VERSION ""

NS_ :

BS_:

BU_: Battery_Management_Cntrl_1 PowertrainControlModule AtmosphericSensor SafetyRestraintSystem2 Aftertreatment_2_GasOutlet Aftertreatment_2_GasIntake DieselParticulateFilterControl Turbocharger SafetyRestraintSystem1 CabDisplay2 Aftertreatment_1_GasOutlet Aftertreatment_1_GasIntake OnBoardDataLogger OffBoardDiagnosticTool2 OffBoardDiagnosticTool1 FileServer ParkingBrakeController SeatController2 FanDriveController SteeringColumnUnit CommunicationUnitRadio CommunicationUnitSatellite CommunicationUnitCellular PropulsionBatteryCharger ChassisController2 ChassisController1 EngineValveControl AuxiliaryHeater2 AuxiliaryHeater1 ClutchUnit RampControl InformationSystem1 SuspensionSystemController2 OilSensor VehicleDynamicStability ExhaustEmissionController TransmissionDisplay2 TransmissionDisplay1 ClimateControl2 WaterPumpController RearAxleSteeringController LightingOperatorControl SeatController1 IgnitionController2 IgnitionController1 TirePressureController CabController2 CabController1 PneumaticSystemController SuspensionSystemController1 HydraulicPumpController EnduranceBrakingSystem RetarderExhaustEngine2 OnBoardDiagnosticUnit HeadwayController RetarderExhaustEngine1 CabDisplay1 ManagementComputer VirtualTerminal OffVehicleGateway PowerTakeOffFront HitchControl AuxiliaryValveControl BodyController TractorTrailerBridge1 StarterSystem ElectricalSystem VehicleSecurity VehicleNavigation AerodynamicControl ElectricalChargingSystem ClimateControl1 TripRecorder InstrumentCluster SuspensionDriveAxle2 SuspensionDriveAxle1 SuspensionSteerAxle SteeringController FuelSystem CruiseControl RetarderDriveline RetarderEngine BrakesDriveAxle2 BrakesDriveAxle1 BrakesSystemController BrakesSteerAxle AxleDrive2 AxleDrive1 AxleSteering PowerTakeOff ShiftConsoleSecondary ShiftConsolePrimary Transmission2 Transmission1 Engine2 Engine1
VAL_TABLE_ FMI 22 "Data Drifted Low" 21 "Data Drifted High" 20 "Received Network Data In Error" 0 "Above normal (most severe)" 1 "Below normal (most severe)" 2 "Data erratic" 3 "Voltage above normal" 4 "Voltage below normal" 5 "Current below normal" 6 "Current above normal" 7 "Mechanical system not responding" 8 "Abnormal frequency" 9 "Abnormal update rate" 10 "Abnormal rate of change" 11 "Root cause not known" 12 "Bad intelligent device" 13 "Out of calibration" 14 "Special intstructions" 15 "Above normal (least severe)" 16 "Above normal (moderately severe)" 17 "Below normal (least severe)" 18 "Below normal (moderately severe)" 19 "Received network data in error" 31 "Condition Exists" ;
VAL_TABLE_ TireLocation_MUX 51 "TirePress_33_MUX_51" 50 "TirePress_32_MUX_50" 49 "TirePress_31_MUX_49" 48 "TirePress_30_MUX_48" 35 "TirePress_23_MUX_35" 34 "TirePress_22_MUX_34" 33 "TirePress_21_MUX_33" 32 "TirePress_20_MUX_32" 19 "TirePress_13_MUX_19" 18 "TirePress_12_MUX_18" 17 "TirePress_11_MUX_17" 16 "TirePress_10_MUX_16" 1 "TirePress_01_MUX_1" 0 "TirePress_00_MUX_0" ;

BO_ 3221225472 VECTOR__INDEPENDENT_SIG_MSG: 0 Vector__XXX
 SG_ HVES1HVBPsvITR_8432 : 0|16@1+ (0.1,0) [0|6425.5] "Ohm/V" Vector__XXX
 SG_ HVES1HVBAcvITR_8431 : 0|16@1+ (0.1,0) [0|6425.5] "Ohm/V" Vector__XXX
 SG_ HVES1LoCellStOChaCellNo_8248 : 0|8@1+ (1,0) [0|250] "count" Vector__XXX
 SG_ HVES1LoCellStOChaModuNo_8247 : 0|8@1+ (1,0) [0|250] "count" Vector__XXX
 SG_ HVES1HiCellStOChaCellNo_8246 : 0|8@1+ (1,0) [0|250] "count" Vector__XXX
 SG_ HVES1HiCellStOChaModuNo_8245 : 0|8@1+ (1,0) [0|250] "count" Vector__XXX
 SG_ TranIdleGovrnrFuelingInhbit_7829 : 0|8@1- (1,0) [0|0] "" Vector__XXX
 SG_ NumberOfMembersInWorkingSet : 0|8@1+ (1,0) [0|0] "" Vector__XXX
 SG_ SourceAddress : 0|8@1+ (1,0) [0|0] "" Vector__XXX
 SG_ NncntnuslyMonitoredSystemsStatus : 0|16@1+ (1,0) [0|0] "" Vector__XXX
 SG_ NncntnslyMonitoredSystemsSupport : 0|16@1+ (1,0) [0|0] "" Vector__XXX
 SG_ CntnslyMntrdSystmsSupport_Status : 0|8@1+ (1,0) [0|0] "" Vector__XXX
 SG_ AETCTorqueValue : 0|16@1+ (1,0) [0|64255] "Nm" Vector__XXX
 SG_ TrailerWeight : 0|16@1+ (2,0) [0|128510] "kg" Vector__XXX
 SG_ ReferenceTirePressSetting : 0|8@1+ (8,0) [0|2000] "kPa" Vector__XXX
 SG_ ReferenceTirePress : 0|8@1+ (8,0) [0|2000] "kPa" Vector__XXX
 SG_ TirePressThresholdDetection : 0|3@1+ (1,0) [0|7] "" Vector__XXX
 SG_ TireAirLeakageRate : 0|16@1+ (0.1,0) [0|6425.5] "Pa/s" Vector__XXX
 SG_ CTIWheelEndElectricalFault : 0|2@1+ (1,0) [0|3] "" Vector__XXX
 SG_ CTITireStatus : 0|2@1+ (1,0) [0|3] "" Vector__XXX
 SG_ CTIWheelSensorStatus : 0|2@1+ (1,0) [0|3] "" Vector__XXX
 SG_ TireTemp : 0|16@1+ (0.03125,-273) [-273|1734.96875] "deg C" Vector__XXX
 SG_ TirePress : 0|8@1+ (4,0) [0|1000] "kPa" Vector__XXX
 SG_ EngTurningGearEngaged : 0|2@1+ (1,0) [0|3] "" Vector__XXX
 SG_ AETCSpeedValue : 0|16@1+ (0.125,0) [0|8031.875] "rpm" Vector__XXX

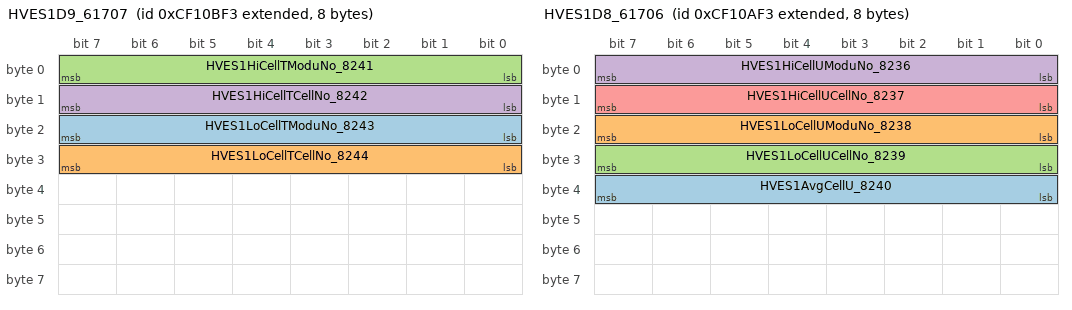
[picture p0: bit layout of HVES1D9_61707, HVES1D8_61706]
BO_ 2364607475 HVES1D9_61707: 8 Battery_Management_Cntrl_1
 SG_ HVES1LoCellTModuNo_8243 : 16|8@1+ (1,0) [0|250] "count" Vector__XXX
 SG_ HVES1LoCellTCellNo_8244 : 24|8@1+ (1,0) [0|250] "count" Vector__XXX
 SG_ HVES1HiCellTModuNo_8241 : 0|8@1+ (1,0) [0|250] "count" Vector__XXX
 SG_ HVES1HiCellTCellNo_8242 : 8|8@1+ (1,0) [0|250] "count" Vector__XXX

BO_ 2364607219 HVES1D8_61706: 8 Battery_Management_Cntrl_1
 SG_ HVES1AvgCellU_8240 : 32|8@1+ (1,0) [0|250] "count" Vector__XXX
 SG_ HVES1LoCellUModuNo_8238 : 16|8@1+ (1,0) [0|250] "count" Vector__XXX
 SG_ HVES1LoCellUCellNo_8239 : 24|8@1+ (1,0) [0|250] "count" Vector__XXX
 SG_ HVES1HiCellUModuNo_8236 : 0|8@1+ (1,0) [0|250] "count" Vector__XXX
 SG_ HVES1HiCellUCellNo_8237 : 8|8@1+ (1,0) [0|250] "count" Vector__XXX

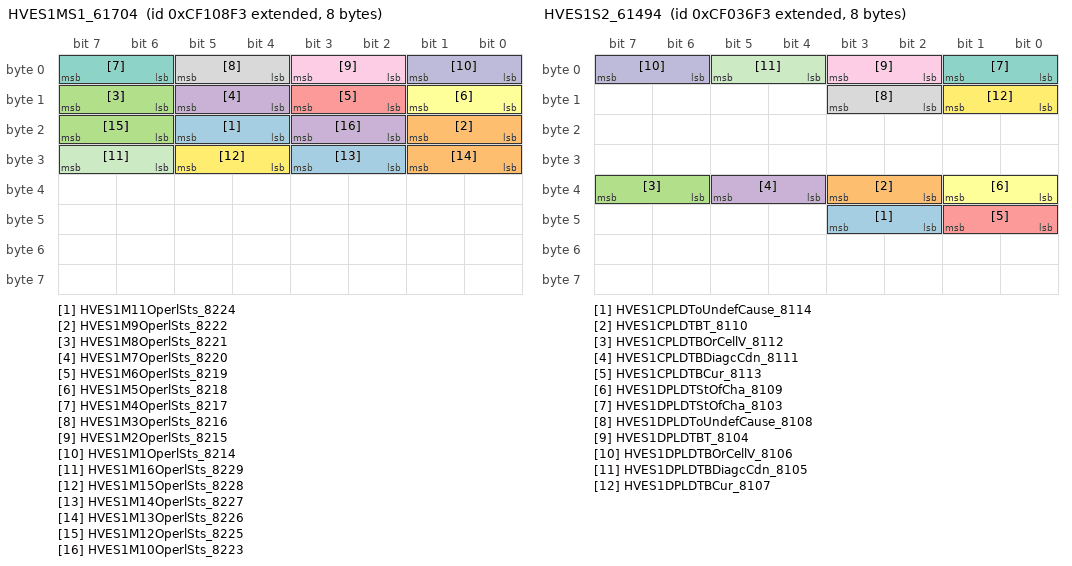
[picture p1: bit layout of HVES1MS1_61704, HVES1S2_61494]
BO_ 2364606707 HVES1MS1_61704: 8 Battery_Management_Cntrl_1
 SG_ HVES1M11OperlSts_8224 : 20|2@1+ (1,0) [0|3] "bit" Vector__XXX
 SG_ HVES1M9OperlSts_8222 : 16|2@1+ (1,0) [0|3] "bit" Vector__XXX
 SG_ HVES1M8OperlSts_8221 : 14|2@1+ (1,0) [0|3] "bit" Vector__XXX
 SG_ HVES1M7OperlSts_8220 : 12|2@1+ (1,0) [0|3] "bit" Vector__XXX
 SG_ HVES1M6OperlSts_8219 : 10|2@1+ (1,0) [0|3] "bit" Vector__XXX
 SG_ HVES1M5OperlSts_8218 : 8|2@1+ (1,0) [0|3] "bit" Vector__XXX
 SG_ HVES1M4OperlSts_8217 : 6|2@1+ (1,0) [0|3] "bit" Vector__XXX
 SG_ HVES1M3OperlSts_8216 : 4|2@1+ (1,0) [0|3] "bit" Vector__XXX
 SG_ HVES1M2OperlSts_8215 : 2|2@1+ (1,0) [0|3] "bit" Vector__XXX
 SG_ HVES1M1OperlSts_8214 : 0|2@1+ (1,0) [0|3] "bit" Vector__XXX
 SG_ HVES1M16OperlSts_8229 : 30|2@1+ (1,0) [0|3] "bit" Vector__XXX
 SG_ HVES1M15OperlSts_8228 : 28|2@1+ (1,0) [0|3] "bit" Vector__XXX
 SG_ HVES1M14OperlSts_8227 : 26|2@1+ (1,0) [0|3] "bit" Vector__XXX
 SG_ HVES1M13OperlSts_8226 : 24|2@1+ (1,0) [0|3] "bit" Vector__XXX
 SG_ HVES1M12OperlSts_8225 : 22|2@1+ (1,0) [0|3] "bit" Vector__XXX
 SG_ HVES1M10OperlSts_8223 : 18|2@1+ (1,0) [0|3] "bit" Vector__XXX

BO_ 2364552947 HVES1S2_61494: 8 Battery_Management_Cntrl_1
 SG_ HVES1CPLDToUndefCause_8114 : 42|2@1+ (1,0) [0|3] "bit" Vector__XXX
 SG_ HVES1CPLDTBT_8110 : 34|2@1+ (1,0) [0|3] "bit" Vector__XXX
 SG_ HVES1CPLDTBOrCellV_8112 : 38|2@1+ (1,0) [0|3] "bit" Vector__XXX
 SG_ HVES1CPLDTBDiagcCdn_8111 : 36|2@1+ (1,0) [0|3] "bit" Vector__XXX
 SG_ HVES1CPLDTBCur_8113 : 40|2@1+ (1,0) [0|3] "bit" Vector__XXX
 SG_ HVES1DPLDTStOfCha_8109 : 32|2@1+ (1,0) [0|3] "bit" Vector__XXX
 SG_ HVES1DPLDTStOfCha_8103 : 0|2@1+ (1,0) [0|3] "bit" Vector__XXX
 SG_ HVES1DPLDToUndefCause_8108 : 10|2@1+ (1,0) [0|3] "bit" Vector__XXX
 SG_ HVES1DPLDTBT_8104 : 2|2@1+ (1,0) [0|3] "bit" Vector__XXX
 SG_ HVES1DPLDTBOrCellV_8106 : 6|2@1+ (1,0) [0|3] "bit" Vector__XXX
 SG_ HVES1DPLDTBDiagcCdn_8105 : 4|2@1+ (1,0) [0|3] "bit" Vector__XXX
 SG_ HVES1DPLDTBCur_8107 : 8|2@1+ (1,0) [0|3] "bit" Vector__XXX

BO_ 2633785075 HVES1HIST_64606: 8 Battery_Management_Cntrl_1
 SG_ HVES1TotEgyThput_8211 : 24|32@1- (100,0) [0|421108121500] "Watt-hour" Vector__XXX
 SG_ HVES1TotAccumCha_8212 : 56|32@1- (100,0) [0|421108121500] "Ah" Vector__XXX
 SG_ HVES1StOfHealth_8121 : 0|8@1- (0.02044,0) [0|5.11] "V" Vector__XXX
 SG_ HVES1CtorOpenUndLoa_8122 : 8|16@1+ (1,0) [0|64255] "count" Vector__XXX

BO_ 2566675955 HVES1CFG_64605: 8 Battery_Management_Cntrl_1
 SG_ HVES1RecomMinSOC_8118 : 48|16@1- (0.0015625,0) [0|100.3984375] "%" Vector__XXX
 SG_ HVES1RecomMinOpergV_8116 : 16|16@1- (0.05,0) [0|3212.75] "V" Vector__XXX
 SG_ HVES1RecomMinOpergT_8208 : 96|16@1- (0.03125,-273) [-273|1734.96875] "deg C" Vector__XXX
 SG_ HVES1RecomMaxSOC_8119 : 64|16@1- (0.0015625,0) [0|100.3984375] "%" Vector__XXX
 SG_ HVES1RecomMaxOpergV_8117 : 32|16@1- (0.05,0) [0|3212.75] "V" Vector__XXX
 SG_ HVES1RecomMaxOpergT_8120 : 80|16@1- (0.03125,-273) [-273|1734.96875] "deg C" Vector__XXX
 SG_ HVES1NomVoltage_8115 : 0|16@1- (0.05,0) [0|3212.75] "V" Vector__XXX
 SG_ HVES1CellMinVLim_8210 : 120|8@1- (0.02044,0) [0|5.11] "V" Vector__XXX
 SG_ HVES1CellMaxVLim_8209 : 112|8@1- (0.02044,0) [0|5.11] "V" Vector__XXX

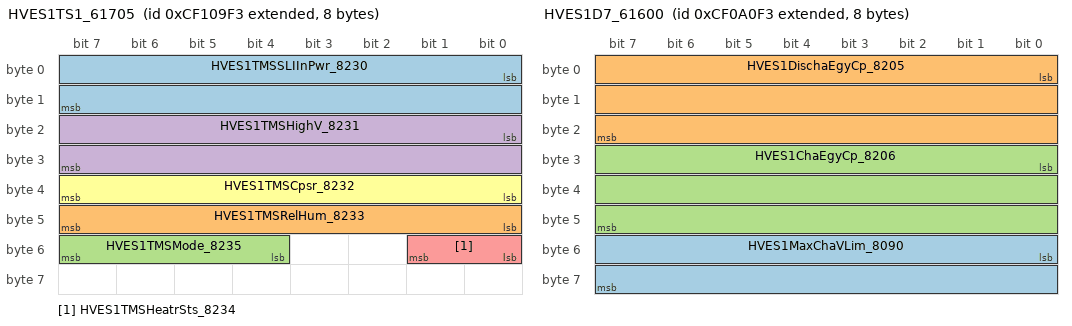
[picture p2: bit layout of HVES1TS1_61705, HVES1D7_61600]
BO_ 2364606963 HVES1TS1_61705: 8 Battery_Management_Cntrl_1
 SG_ HVES1TMSSLIInPwr_8230 : 0|16@1- (0.5,0) [0|32127.5] "W" Vector__XXX
 SG_ HVES1TMSRelHum_8233 : 40|8@1- (0.4,0) [0|100] "%" Vector__XXX
 SG_ HVES1TMSMode_8235 : 52|4@1- (1,0) [0|15] "bits" Vector__XXX
 SG_ HVES1TMSHighV_8231 : 16|16@1- (0.5,0) [0|32127.5] "W" Vector__XXX
 SG_ HVES1TMSHeatrSts_8234 : 48|2@1- (1,0) [0|3] "bits" Vector__XXX
 SG_ HVES1TMSCpsr_8232 : 32|8@1- (32,0) [0|8000] "rpm" Vector__XXX

BO_ 2364580083 HVES1D7_61600: 8 Battery_Management_Cntrl_1
 SG_ HVES1MaxChaVLim_8090 : 48|16@1- (0.05,0) [0|3212.75] "V" Vector__XXX
 SG_ HVES1DischaEgyCp_8205 : 0|24@1- (0.001,0) [0|16449.535] "kWh" Vector__XXX
 SG_ HVES1ChaEgyCp_8206 : 24|24@1- (0.001,0) [0|16449.535] "kWh" Vector__XXX

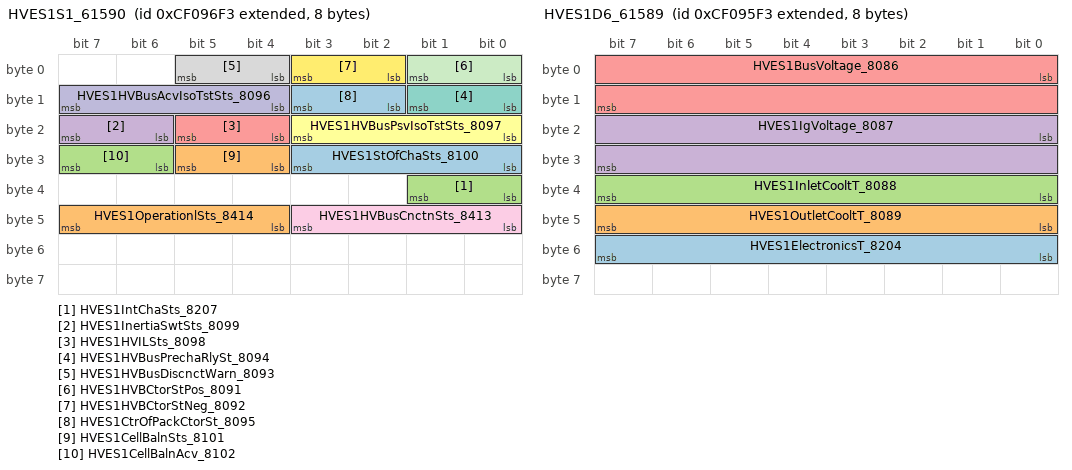
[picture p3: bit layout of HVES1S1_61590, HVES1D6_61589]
BO_ 2364577523 HVES1S1_61590: 8 Battery_Management_Cntrl_1
 SG_ HVES1StOfChaSts_8100 : 24|4@1+ (1,0) [0|15] "bits" Vector__XXX
 SG_ HVES1OperationlSts_8414 : 44|4@1+ (1,0) [0|15] "bit" Vector__XXX
 SG_ HVES1IntChaSts_8207 : 32|2@1- (1,0) [0|3] "bits" Vector__XXX
 SG_ HVES1InertiaSwtSts_8099 : 22|2@1+ (1,0) [0|3] "bits" Vector__XXX
 SG_ HVES1HVILSts_8098 : 20|2@1+ (1,0) [0|3] "bits" Vector__XXX
 SG_ HVES1HVBusPsvIsoTstSts_8097 : 16|4@1- (1,0) [0|15] "bits" Vector__XXX
 SG_ HVES1HVBusPrechaRlySt_8094 : 8|2@1+ (1,0) [0|3] "bits" Vector__XXX
 SG_ HVES1HVBusDiscnctWarn_8093 : 4|2@1+ (1,0) [0|15] "bits" Vector__XXX
 SG_ HVES1HVBusCnctnSts_8413 : 40|4@1- (1,0) [0|15] "bits" Vector__XXX
 SG_ HVES1HVBusAcvIsoTstSts_8096 : 12|4@1- (1,0) [0|15] "bits" Vector__XXX
 SG_ HVES1HVBCtorStPos_8091 : 0|2@1- (1,0) [0|3] "bit" Vector__XXX
 SG_ HVES1HVBCtorStNeg_8092 : 2|2@1- (1,0) [0|3] "bit" Vector__XXX
 SG_ HVES1CtrOfPackCtorSt_8095 : 10|2@1+ (1,0) [0|3] "bits" Vector__XXX
 SG_ HVES1CellBalnSts_8101 : 28|2@1+ (1,0) [0|3] "bit" Vector__XXX
 SG_ HVES1CellBalnAcv_8102 : 30|2@1+ (1,0) [0|3] "bit" Vector__XXX

BO_ 2364577267 HVES1D6_61589: 8 Battery_Management_Cntrl_1
 SG_ HVES1ElectronicsT_8204 : 48|8@1- (1,-40) [-40|210] "deg C" Vector__XXX
 SG_ HVES1OutletCooltT_8089 : 40|8@1- (1,-40) [-40|210] "deg C" Vector__XXX
 SG_ HVES1InletCooltT_8088 : 32|8@1- (1,-40) [-40|210] "deg C" Vector__XXX
 SG_ HVES1IgVoltage_8087 : 16|16@1- (0.01,0) [0|642.55] "V" Vector__XXX
 SG_ HVES1BusVoltage_8086 : 0|16@1- (0.05,0) [0|3212.75] "V" Vector__XXX

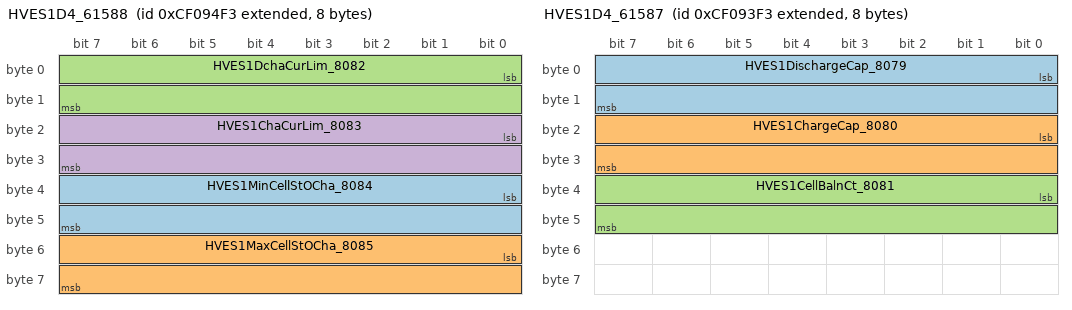
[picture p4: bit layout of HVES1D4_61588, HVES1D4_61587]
BO_ 2364577011 HVES1D4_61588: 8 Battery_Management_Cntrl_1
 SG_ HVES1MinCellStOCha_8084 : 32|16@1- (0.0015625,0) [0|100.3984375] "%" Vector__XXX
 SG_ HVES1MaxCellStOCha_8085 : 48|16@1- (0.0015625,0) [0|100.3984375] "%" Vector__XXX
 SG_ HVES1DchaCurLim_8082 : 0|16@1- (0.05,-1600) [-1600|1612.75] "A" Vector__XXX
 SG_ HVES1ChaCurLim_8083 : 16|16@1- (0.05,-1600) [-1600|1612.75] "A" Vector__XXX

BO_ 2364576755 HVES1D4_61587: 8 Battery_Management_Cntrl_1
 SG_ HVES1DischargeCap_8079 : 0|16@1- (0.01,0) [0|642.55] "Ah" Vector__XXX
 SG_ HVES1ChargeCap_8080 : 16|16@1- (0.01,0) [0|642.55] "Ah" Vector__XXX
 SG_ HVES1CellBalnCt_8081 : 32|16@1- (1,0) [0|64255] "count" Vector__XXX

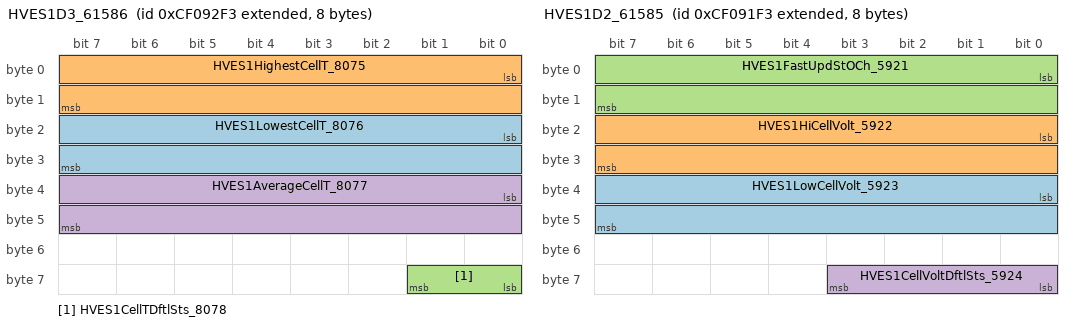
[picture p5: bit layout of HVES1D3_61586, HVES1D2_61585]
BO_ 2364576499 HVES1D3_61586: 8 Battery_Management_Cntrl_1
 SG_ HVES1LowestCellT_8076 : 16|16@1- (0.03125,-273) [-273|1734.96875] "degrees C" Vector__XXX
 SG_ HVES1HighestCellT_8075 : 0|16@1- (0.03125,-273) [-273|1734.96875] "degrees C" Vector__XXX
 SG_ HVES1CellTDftlSts_8078 : 56|2@1- (1,0) [0|3] "bits" Vector__XXX
 SG_ HVES1AverageCellT_8077 : 32|16@1- (0.03125,-273) [-273|1734.96875] "degrees C" Vector__XXX

BO_ 2364576243 HVES1D2_61585: 8 Battery_Management_Cntrl_1
 SG_ HVES1LowCellVolt_5923 : 32|16@1- (0.001,0) [0|64.255] "V" Vector__XXX
 SG_ HVES1HiCellVolt_5922 : 16|16@1- (0.001,0) [0|64.255] "V" Vector__XXX
 SG_ HVES1FastUpdStOCh_5921 : 0|16@1- (0.0015625,0) [0|100.3984375] "%" Vector__XXX
 SG_ HVES1CellVoltDftlSts_5924 : 56|4@1- (1,0) [0|15] "bot" Vector__XXX

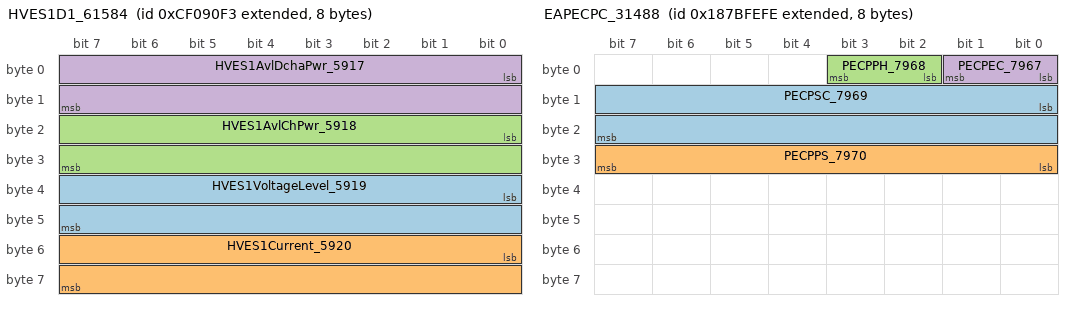
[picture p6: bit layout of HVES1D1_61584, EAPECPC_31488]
BO_ 2364575987 HVES1D1_61584: 8 Battery_Management_Cntrl_1
 SG_ HVES1VoltageLevel_5919 : 32|16@1- (0.05,0) [0|3212.75] "V" Vector__XXX
 SG_ HVES1Current_5920 : 48|16@1- (0.05,-1600) [-1600|1612.75] "A" Vector__XXX
 SG_ HVES1AvlChPwr_5918 : 16|16@1- (0.05,0) [0|3212.75] "kW" Vector__XXX
 SG_ HVES1AvlDchaPwr_5917 : 0|16@1- (0.05,0) [0|3212.75] "kW" Vector__XXX

BO_ 2558263038 EAPECPC_31488: 8 Vector__XXX
 SG_ PECPSC_7969 : 8|16@1+ (0.5,0) [0|32767.5] "rpm" Vector__XXX
 SG_ PECPPS_7970 : 24|8@1+ (0.5,0) [0|127.5] "%" Vector__XXX
 SG_ PECPPH_7968 : 2|2@1+ (1,0) [0|3] "" Vector__XXX
 SG_ PECPEC_7967 : 0|2@1+ (1,0) [0|3] "" Vector__XXX

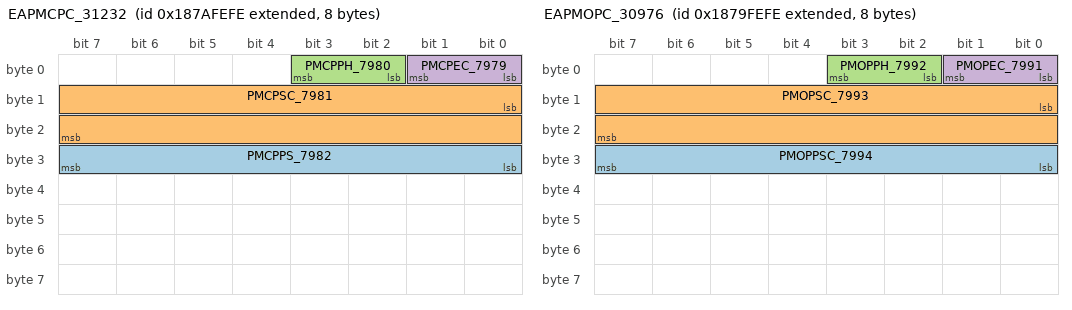
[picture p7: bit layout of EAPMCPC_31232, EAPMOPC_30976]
BO_ 2558197502 EAPMCPC_31232: 8 Vector__XXX
 SG_ PMCPPS_7982 : 24|8@1+ (0.5,0) [0|127.5] "%" Vector__XXX
 SG_ PMCPSC_7981 : 8|16@1+ (0.5,0) [0|32767.5] "rpm" Vector__XXX
 SG_ PMCPPH_7980 : 2|2@1+ (1,0) [0|3] "" Vector__XXX
 SG_ PMCPEC_7979 : 0|2@1+ (1,0) [0|3] "" Vector__XXX

BO_ 2558131966 EAPMOPC_30976: 8 Vector__XXX
 SG_ PMOPPSC_7994 : 24|8@1+ (0.5,0) [0|127.5] "%" Vector__XXX
 SG_ PMOPSC_7993 : 8|16@1+ (0.5,0) [0|32767.5] "rpm" Vector__XXX
 SG_ PMOPPH_7992 : 2|2@1+ (1,0) [0|3] "" Vector__XXX
 SG_ PMOPEC_7991 : 0|2@1+ (1,0) [0|3] "" Vector__XXX

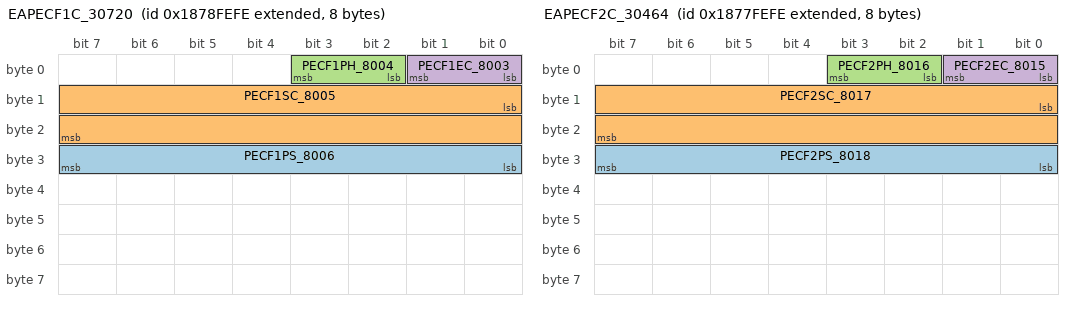
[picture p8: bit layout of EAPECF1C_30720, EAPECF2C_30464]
BO_ 2558066430 EAPECF1C_30720: 8 Vector__XXX
 SG_ PECF1PS_8006 : 24|8@1+ (0.5,0) [0|127.5] "%" Vector__XXX
 SG_ PECF1SC_8005 : 8|16@1+ (0.5,0) [0|32767.5] "rpm" Vector__XXX
 SG_ PECF1PH_8004 : 2|2@1+ (1,0) [0|3] "" Vector__XXX
 SG_ PECF1EC_8003 : 0|2@1+ (1,0) [0|3] "" Vector__XXX

BO_ 2558000894 EAPECF2C_30464: 8 Vector__XXX
 SG_ PECF2PS_8018 : 24|8@1+ (0.5,0) [0|127.5] "%" Vector__XXX
 SG_ PECF2SC_8017 : 8|16@1+ (0.5,0) [0|32767.5] "rpm" Vector__XXX
 SG_ PECF2PH_8016 : 2|2@1+ (1,0) [0|3] "" Vector__XXX
 SG_ PECF2EC_8015 : 0|2@1+ (1,0) [0|3] "" Vector__XXX

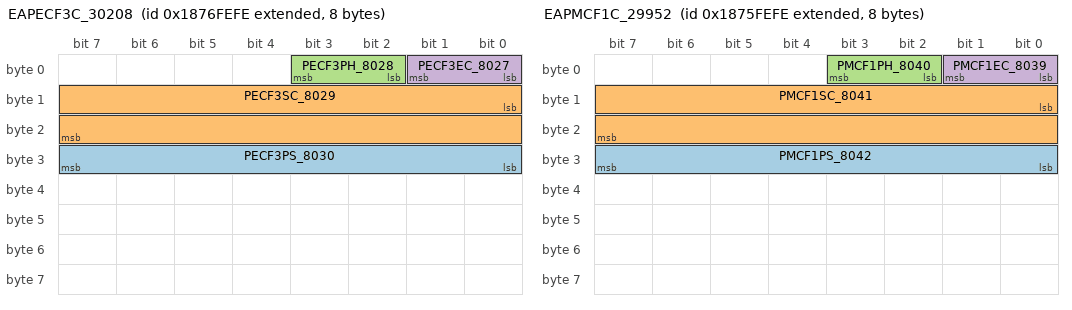
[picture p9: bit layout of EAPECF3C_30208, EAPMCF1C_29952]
BO_ 2557935358 EAPECF3C_30208: 8 Vector__XXX
 SG_ PECF3PS_8030 : 24|8@1+ (0.5,0) [0|127.5] "%" Vector__XXX
 SG_ PECF3SC_8029 : 8|16@1+ (0.5,0) [0|32767.5] "rpm" Vector__XXX
 SG_ PECF3PH_8028 : 2|2@1+ (1,0) [0|3] "" Vector__XXX
 SG_ PECF3EC_8027 : 0|2@1+ (1,0) [0|3] "" Vector__XXX

BO_ 2557869822 EAPMCF1C_29952: 8 Vector__XXX
 SG_ PMCF1PS_8042 : 24|8@1+ (0.5,0) [0|127.5] "%" Vector__XXX
 SG_ PMCF1SC_8041 : 8|16@1+ (0.5,0) [0|32767.5] "rpm" Vector__XXX
 SG_ PMCF1PH_8040 : 2|2@1+ (1,0) [0|3] "" Vector__XXX
 SG_ PMCF1EC_8039 : 0|2@1+ (1,0) [0|3] "" Vector__XXX

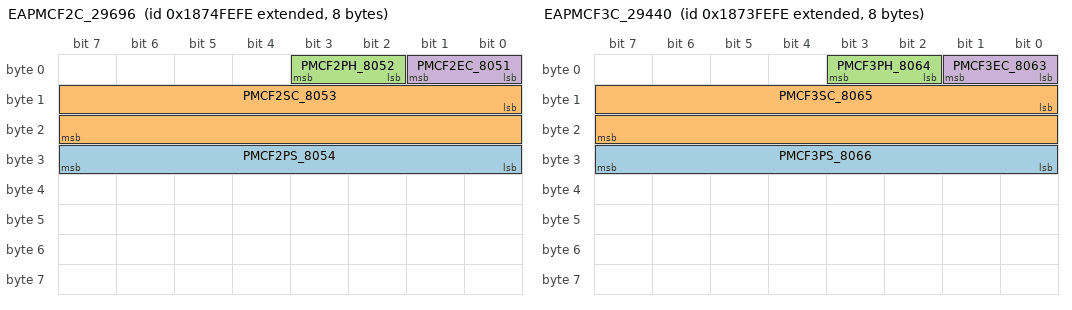
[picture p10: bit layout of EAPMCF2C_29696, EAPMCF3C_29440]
BO_ 2557804286 EAPMCF2C_29696: 8 Vector__XXX
 SG_ PMCF2PS_8054 : 24|8@1+ (0.5,0) [0|127.5] "%" Vector__XXX
 SG_ PMCF2SC_8053 : 8|16@1+ (0.5,0) [0|32767.5] "rpm" Vector__XXX
 SG_ PMCF2PH_8052 : 2|2@1+ (1,0) [0|3] "" Vector__XXX
 SG_ PMCF2EC_8051 : 0|2@1+ (1,0) [0|3] "" Vector__XXX

BO_ 2557738750 EAPMCF3C_29440: 8 Vector__XXX
 SG_ PMCF3PS_8066 : 24|8@1+ (0.5,0) [0|127.5] "%" Vector__XXX
 SG_ PMCF3SC_8065 : 8|16@1+ (0.5,0) [0|32767.5] "rpm" Vector__XXX
 SG_ PMCF3PH_8064 : 2|2@1+ (1,0) [0|3] "" Vector__XXX
 SG_ PMCF3EC_8063 : 0|2@1+ (1,0) [0|3] "" Vector__XXX

BO_ 2557673214 ODMCC_29184: 37 Vector__XXX
 SG_ ODMFB5CC_8203 : 272|24@1+ (1,0) [0|16449535] "" Vector__XXX
 SG_ ODMFB5CC_8202 : 248|24@1+ (1,0) [0|16449535] "" Vector__XXX
 SG_ ODMFB5CC_8201 : 224|24@1+ (1,0) [0|16449535] "" Vector__XXX
 SG_ ODMFB5CC_8200 : 200|24@1+ (1,0) [0|16449535] "" Vector__XXX
 SG_ ODMFB5CC_8199 : 176|24@1+ (1,0) [0|16449535] "" Vector__XXX
 SG_ ODMFB7CC_8198 : 152|24@1+ (1,0) [0|16449535] "" Vector__XXX
 SG_ ODMFB6CC_8197 : 128|24@1+ (1,0) [0|16449535] "" Vector__XXX
 SG_ ODMFB5CC_8196 : 104|24@1+ (1,0) [0|16449535] "" Vector__XXX
 SG_ ODMFB4CC_8195 : 80|24@1+ (1,0) [0|16449535] "" Vector__XXX
 SG_ ODMFB2CC_8193 : 32|24@1+ (1,0) [0|16449535] "" Vector__XXX
 SG_ ODMFB3CC_8194 : 56|24@1+ (1,0) [0|16449535] "" Vector__XXX
 SG_ ODMFB1CC_8192 : 8|24@1+ (1,0) [0|16449535] "" Vector__XXX
 SG_ ODMCIN_8191 : 0|8@1+ (1,0) [0|255] "" Vector__XXX

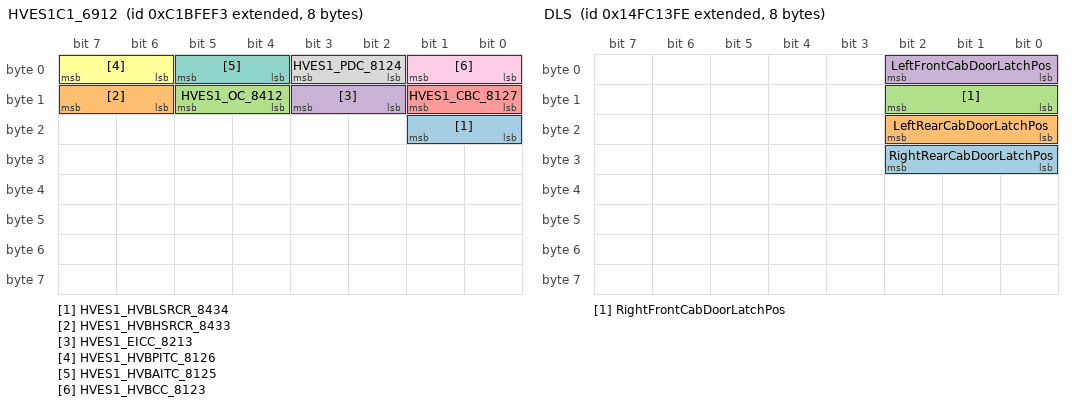
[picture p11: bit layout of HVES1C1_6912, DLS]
BO_ 2350644979 HVES1C1_6912: 8 Battery_Management_Cntrl_1
 SG_ HVES1_HVBLSRCR_8434 : 16|2@1+ (1,0) [0|3] "" Vector__XXX
 SG_ HVES1_HVBHSRCR_8433 : 14|2@1+ (1,0) [0|3] "" Vector__XXX
 SG_ HVES1_OC_8412 : 12|2@1+ (1,0) [0|3] "" Vector__XXX
 SG_ HVES1_EICC_8213 : 10|2@1+ (1,0) [0|3] "" Vector__XXX
 SG_ HVES1_CBC_8127 : 8|2@1+ (1,0) [0|3] "" Vector__XXX
 SG_ HVES1_HVBPITC_8126 : 6|2@1+ (1,0) [0|3] "" Vector__XXX
 SG_ HVES1_HVBAITC_8125 : 4|2@1+ (1,0) [0|3] "" Vector__XXX
 SG_ HVES1_PDC_8124 : 2|2@1+ (1,0) [0|3] "" Vector__XXX
 SG_ HVES1_HVBCC_8123 : 0|2@1+ (1,0) [0|3] "" Vector__XXX

BO_ 2566658558 PLST1: 8 Vector__XXX
 SG_ TotalHaulCycleCount : 32|32@1+ (1,0) [0|4211081215] "" Vector__XXX
 SG_ TotalDeliveredPayloadWeight : 0|32@1+ (100,0) [0|421108121500] "kg" Vector__XXX

BO_ 2566658302 PLST2: 8 Vector__XXX
 SG_ TotalPayloadTransactionCount : 0|32@1+ (1,0) [0|4211081215] "" Vector__XXX

BO_ 2499549182 PLT1: 8 Vector__XXX

BO_ 2499548926 PLT2: 8 Vector__XXX

BO_ 2499548670 VEP6: 8 Vector__XXX

BO_ 2499548158 DLS: 8 Vector__XXX
 SG_ RightRearCabDoorLatchPos : 24|3@1+ (1,0) [0|7] "" Vector__XXX
 SG_ LeftRearCabDoorLatchPos : 16|3@1+ (1,0) [0|7] "" Vector__XXX
 SG_ RightFrontCabDoorLatchPos : 8|3@1+ (1,0) [0|7] "" Vector__XXX
 SG_ LeftFrontCabDoorLatchPos : 0|3@1+ (1,0) [0|7] "" Vector__XXX

BO_ 2499547902 CDC: 8 Vector__XXX
 SG_ MirrorRight2HeatCmd : 54|2@1+ (1,0) [0|3] "" Vector__XXX
 SG_ MirrorLeft2HeatCmd : 52|2@1+ (1,0) [0|3] "" Vector__XXX
 SG_ MirrorRight1HeatCmd : 50|2@1+ (1,0) [0|3] "" Vector__XXX
 SG_ MirrorLeft1HeatCmd : 48|2@1+ (1,0) [0|3] "" Vector__XXX
 SG_ MirrorRight2VerticalCmd : 46|2@1+ (1,0) [0|3] "" Vector__XXX
 SG_ MirrorRight2HorizontalCmd : 44|2@1+ (1,0) [0|3] "" Vector__XXX
 SG_ MirrorLeft2VerticalCmd : 42|2@1+ (1,0) [0|3] "" Vector__XXX
 SG_ MirrorLeft2HorizontalCmd : 40|2@1+ (1,0) [0|3] "" Vector__XXX
 SG_ MirrorRight1VerticalCmd : 38|2@1+ (1,0) [0|3] "" Vector__XXX
 SG_ MirrorRight1HorizontalCmd : 36|2@1+ (1,0) [0|3] "" Vector__XXX
 SG_ MirrorLeft1VerticalCmd : 34|2@1+ (1,0) [0|3] "" Vector__XXX
 SG_ MirrorLeft1HorizontalCmd : 32|2@1+ (1,0) [0|3] "" Vector__XXX
 SG_ RightRearWindowPosCmd : 27|3@1+ (1,0) [0|7] "" Vector__XXX
 SG_ LeftRearWindowPosCmd : 24|3@1+ (1,0) [0|7] "" Vector__XXX
 SG_ RightFrontWindowPosCmd : 19|3@1+ (1,0) [0|7] "" Vector__XXX
 SG_ LeftFrontWindowPosCmd : 16|3@1+ (1,0) [0|7] "" Vector__XXX
 SG_ RemoteCabDoorLockReq : 8|3@1+ (1,0) [0|7] "" Vector__XXX
 SG_ DoorsLockActCmd : 0|3@1+ (1,0) [0|7] "" Vector__XXX

BO_ 2566656510 TGFI: 8 Vector__XXX
 SG_ EngTotalGasIdleFuelVolumeUsed : 32|32@1+ (0.5,0) [0|2105540607.5] "m³" Vector__XXX
 SG_ EngTotalGasFuelVolumeUsed : 0|32@1+ (0.5,0) [0|2105540607.5] "m³" Vector__XXX

BO_ 2565929214 ADASIS3: 8 Vector__XXX

BO_ 2565928958 ADASIS2: 8 Vector__XXX

BO_ 2565928702 ADASIS1: 8 Vector__XXX

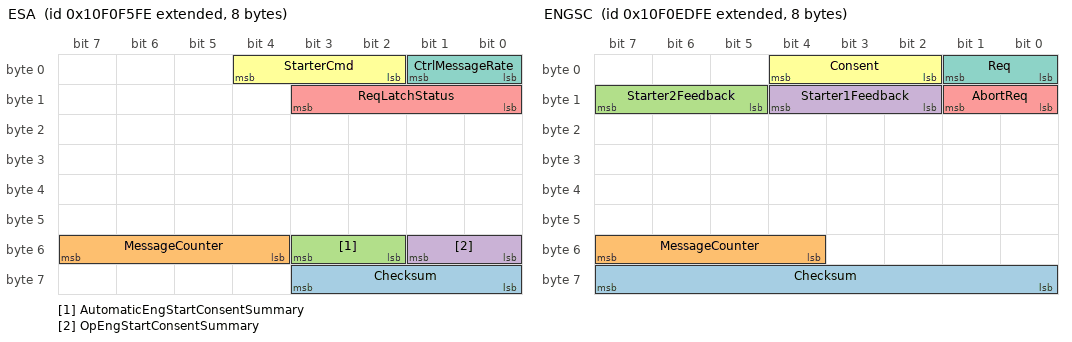
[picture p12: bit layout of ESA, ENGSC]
BO_ 2431710718 ESA: 8 Vector__XXX
 SG_ Checksum : 56|4@1+ (1,0) [0|15] "" Vector__XXX
 SG_ MessageCounter : 52|4@1+ (1,0) [0|15] "" Vector__XXX
 SG_ AutomaticEngStartConsentSummary : 50|2@1+ (1,0) [0|3] "" Vector__XXX
 SG_ OpEngStartConsentSummary : 48|2@1+ (1,0) [0|3] "" Vector__XXX
 SG_ ReqLatchStatus : 8|4@1+ (1,0) [0|15] "" Vector__XXX
 SG_ StarterCmd : 2|3@1+ (1,0) [0|7] "" Vector__XXX
 SG_ CtrlMessageRate : 0|2@1+ (1,0) [0|3] "" Vector__XXX

BO_ 2431708670 ENGSC: 8 Vector__XXX
 SG_ Checksum : 56|8@1+ (1,0) [0|255] "" Vector__XXX
 SG_ MessageCounter : 52|4@1+ (1,0) [0|15] "" Vector__XXX
 SG_ Starter2Feedback : 13|3@1+ (1,0) [0|7] "" Vector__XXX
 SG_ Starter1Feedback : 10|3@1+ (1,0) [0|7] "" Vector__XXX
 SG_ AbortReq : 8|2@1+ (1,0) [0|3] "" Vector__XXX
 SG_ Consent : 2|3@1+ (1,0) [0|7] "" Vector__XXX
 SG_ Req : 0|2@1+ (1,0) [0|3] "" Vector__XXX

BO_ 2566661118 LFC2: 8 Vector__XXX
 SG_ EngTotalDieselFuelDemand : 0|32@1+ (0.5,0) [0|2105540607.5] "L" Vector__XXX

BO_ 2633769726 EEC19: 8 Vector__XXX
 SG_ TotalEngEnergy : 0|32@1+ (1,0) [0|4211081215] "kWh" Vector__XXX

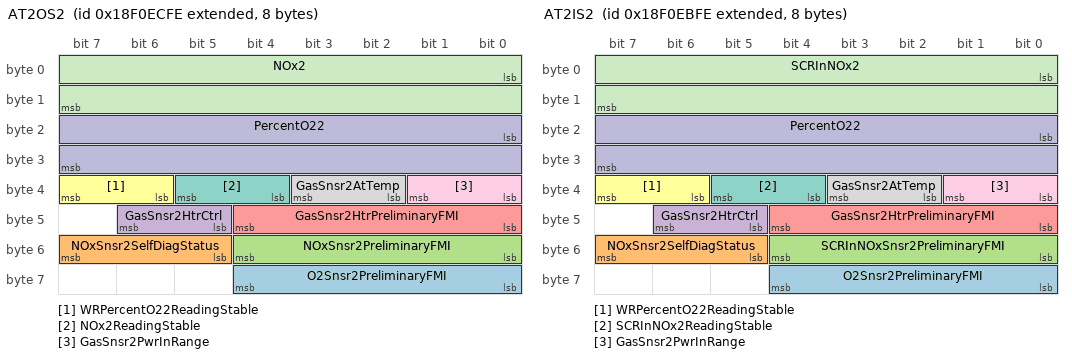
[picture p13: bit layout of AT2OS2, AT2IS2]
BO_ 2565926142 AT2OS2: 8 Vector__XXX
 SG_ O2Snsr2PreliminaryFMI : 56|5@1+ (1,0) [0|31] "" Vector__XXX
 SG_ NOxSnsr2SelfDiagStatus : 53|3@1+ (1,0) [0|7] "" Vector__XXX
 SG_ NOxSnsr2PreliminaryFMI : 48|5@1+ (1,0) [0|31] "" Vector__XXX
 SG_ GasSnsr2HtrCtrl : 45|2@1+ (1,0) [0|3] "" Vector__XXX
 SG_ GasSnsr2HtrPreliminaryFMI : 40|5@1+ (1,0) [0|31] "" Vector__XXX
 SG_ WRPercentO22ReadingStable : 38|2@1+ (1,0) [0|3] "" Vector__XXX
 SG_ NOx2ReadingStable : 36|2@1+ (1,0) [0|3] "" Vector__XXX
 SG_ GasSnsr2AtTemp : 34|2@1+ (1,0) [0|3] "" Vector__XXX
 SG_ GasSnsr2PwrInRange : 32|2@1+ (1,0) [0|3] "" Vector__XXX
 SG_ PercentO22 : 16|16@1+ (0.000514,-12) [-12|21.02707] "%" Vector__XXX
 SG_ NOx2 : 0|16@1+ (0.05,-200) [-200|3012.75] "ppm" Vector__XXX

BO_ 2565925886 AT2IS2: 8 Vector__XXX
 SG_ O2Snsr2PreliminaryFMI : 56|5@1+ (1,0) [0|31] "" Vector__XXX
 SG_ NOxSnsr2SelfDiagStatus : 53|3@1+ (1,0) [0|7] "" Vector__XXX
 SG_ SCRInNOxSnsr2PreliminaryFMI : 48|5@1+ (1,0) [0|31] "" Vector__XXX
 SG_ GasSnsr2HtrCtrl : 45|2@1+ (1,0) [0|3] "" Vector__XXX
 SG_ GasSnsr2HtrPreliminaryFMI : 40|5@1+ (1,0) [0|31] "" Vector__XXX
 SG_ WRPercentO22ReadingStable : 38|2@1+ (1,0) [0|3] "" Vector__XXX
 SG_ SCRInNOx2ReadingStable : 36|2@1+ (1,0) [0|3] "" Vector__XXX
 SG_ GasSnsr2AtTemp : 34|2@1+ (1,0) [0|3] "" Vector__XXX
 SG_ GasSnsr2PwrInRange : 32|2@1+ (1,0) [0|3] "" Vector__XXX
 SG_ PercentO22 : 16|16@1+ (0.000514,-12) [-12|21.02707] "%" Vector__XXX
 SG_ SCRInNOx2 : 0|16@1+ (0.05,-200) [-200|3012.75] "ppm" Vector__XXX

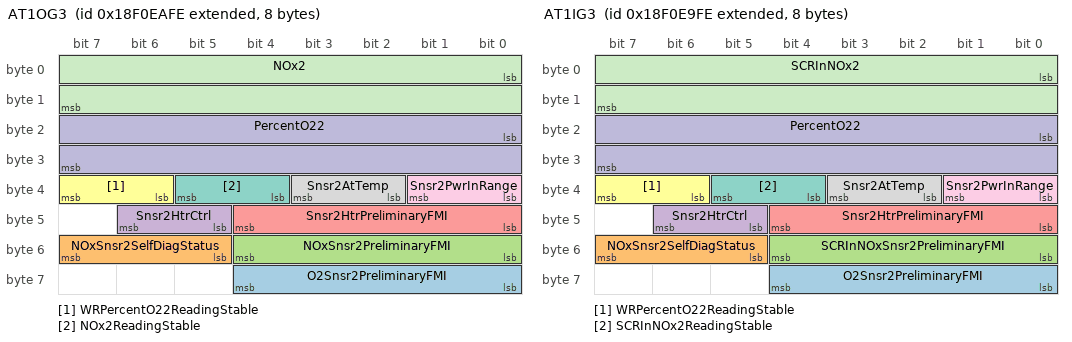
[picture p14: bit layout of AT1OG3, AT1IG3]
BO_ 2565925630 AT1OG3: 8 Vector__XXX
 SG_ O2Snsr2PreliminaryFMI : 56|5@1+ (1,0) [0|31] "" Vector__XXX
 SG_ NOxSnsr2SelfDiagStatus : 53|3@1+ (1,0) [0|7] "" Vector__XXX
 SG_ NOxSnsr2PreliminaryFMI : 48|5@1+ (1,0) [0|31] "" Vector__XXX
 SG_ Snsr2HtrCtrl : 45|2@1+ (1,0) [0|3] "" Vector__XXX
 SG_ Snsr2HtrPreliminaryFMI : 40|5@1+ (1,0) [0|31] "" Vector__XXX
 SG_ WRPercentO22ReadingStable : 38|2@1+ (1,0) [0|3] "" Vector__XXX
 SG_ NOx2ReadingStable : 36|2@1+ (1,0) [0|3] "" Vector__XXX
 SG_ Snsr2AtTemp : 34|2@1+ (1,0) [0|3] "" Vector__XXX
 SG_ Snsr2PwrInRange : 32|2@1+ (1,0) [0|3] "" Vector__XXX
 SG_ PercentO22 : 16|16@1+ (0.000514,-12) [-12|21.02707] "%" Vector__XXX
 SG_ NOx2 : 0|16@1+ (0.05,-200) [-200|3012.75] "ppm" Vector__XXX

BO_ 2565925374 AT1IG3: 8 Vector__XXX
 SG_ O2Snsr2PreliminaryFMI : 56|5@1+ (1,0) [0|31] "" Vector__XXX
 SG_ NOxSnsr2SelfDiagStatus : 53|3@1+ (1,0) [0|7] "" Vector__XXX
 SG_ SCRInNOxSnsr2PreliminaryFMI : 48|5@1+ (1,0) [0|31] "" Vector__XXX
 SG_ Snsr2HtrCtrl : 45|2@1+ (1,0) [0|3] "" Vector__XXX
 SG_ Snsr2HtrPreliminaryFMI : 40|5@1+ (1,0) [0|31] "" Vector__XXX
 SG_ WRPercentO22ReadingStable : 38|2@1+ (1,0) [0|3] "" Vector__XXX
 SG_ SCRInNOx2ReadingStable : 36|2@1+ (1,0) [0|3] "" Vector__XXX
 SG_ Snsr2AtTemp : 34|2@1+ (1,0) [0|3] "" Vector__XXX
 SG_ Snsr2PwrInRange : 32|2@1+ (1,0) [0|3] "" Vector__XXX
 SG_ PercentO22 : 16|16@1+ (0.000514,-12) [-12|21.02707] "%" Vector__XXX
 SG_ SCRInNOx2 : 0|16@1+ (0.05,-200) [-200|3012.75] "ppm" Vector__XXX

BO_ 2364598526 TFAC2: 8 Vector__XXX
 SG_ FuelAct4CtrlCmd : 48|16@1+ (0.0025,0) [0|160.6375] "%" Vector__XXX
 SG_ FuelAct3CtrlCmd : 32|16@1+ (0.0025,0) [0|100] "%" Vector__XXX

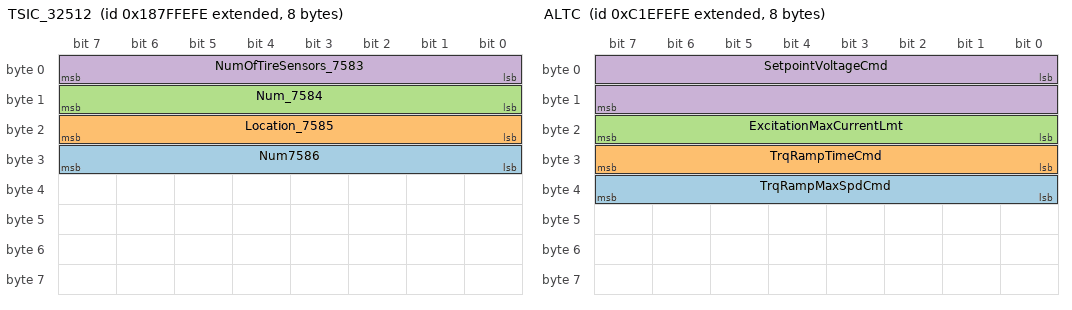
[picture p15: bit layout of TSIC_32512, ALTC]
BO_ 2558525182 TSIC_32512: 8 Vector__XXX
 SG_ Num7586 : 24|8@1+ (1,0) [0|255] "" Vector__XXX
 SG_ Location_7585 : 16|8@1+ (1,0) [0|0] "" Vector__XXX
 SG_ Num_7584 : 8|8@1+ (1,0) [0|250] "" Vector__XXX
 SG_ NumOfTireSensors_7583 : 0|8@1+ (1,0) [0|250] "" Vector__XXX

BO_ 2350841598 ALTC: 8 Vector__XXX
 SG_ TrqRampMaxSpdCmd : 32|8@1+ (32,0) [0|8000] "rpm" Vector__XXX
 SG_ TrqRampTimeCmd : 24|8@1+ (0.1,0) [0.1|25] "s" Vector__XXX
 SG_ ExcitationMaxCurrentLmt : 16|8@1+ (0.25,0) [0|62.5] "A" Vector__XXX
 SG_ SetpointVoltageCmd : 0|16@1+ (0.001,0) [0|64.255] "V" Vector__XXX

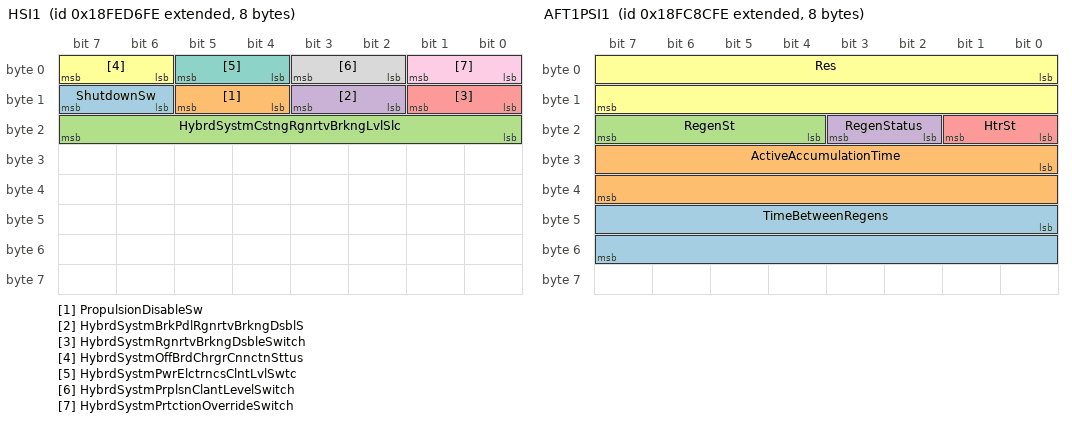
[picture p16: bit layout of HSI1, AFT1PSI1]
BO_ 2566838014 HSI1: 8 Vector__XXX
 SG_ ShutdownSw : 14|2@1+ (1,0) [0|3] "" Vector__XXX
 SG_ PropulsionDisableSw : 12|2@1+ (1,0) [0|3] "" Vector__XXX
 SG_ HybrdSystmCstngRgnrtvBrkngLvlSlc : 16|8@1+ (0.4,0) [0|100] "%" Vector__XXX
 SG_ HybrdSystmBrkPdlRgnrtvBrkngDsblS : 10|2@1+ (1,0) [0|3] "" Vector__XXX
 SG_ HybrdSystmRgnrtvBrkngDsbleSwitch : 8|2@1+ (1,0) [0|3] "" Vector__XXX
 SG_ HybrdSystmOffBrdChrgrCnnctnSttus : 6|2@1+ (1,0) [0|3] "" Vector__XXX
 SG_ HybrdSystmPwrElctrncsClntLvlSwtc : 4|2@1+ (1,0) [0|3] "" Vector__XXX
 SG_ HybrdSystmPrplsnClantLevelSwitch : 2|2@1+ (1,0) [0|3] "" Vector__XXX
 SG_ HybrdSystmPrtctionOverrideSwitch : 0|2@1+ (1,0) [0|3] "" Vector__XXX

BO_ 2566761726 EFI: 8 Vector__XXX
 SG_ EngIdleFuelFlowRateThreshold : 8|32@1+ (0.001,0) [0|4211081.215] "L/h" Vector__XXX
 SG_ NmbrOfFlCnsmptnMntrngTransducers : 0|8@1+ (1,0) [0|250] "" Vector__XXX

BO_ 2566756350 LFI3: 8 Vector__XXX
 SG_ EngFuelReturnTemp : 8|8@1+ (1,-40) [-40|210] "°C" Vector__XXX
 SG_ EngFuelSupplyTemp : 0|8@1+ (1,-40) [-40|210] "°C" Vector__XXX

BO_ 2566756094 LFI2: 8 Vector__XXX
 SG_ EngFuelReturnFlowRate : 32|32@1+ (0.001,0) [0|4211081.215] "L/h" Vector__XXX
 SG_ EngFuelSupplyFlowRate : 0|32@1+ (0.001,0) [0|4211081.215] "L/h" Vector__XXX

BO_ 2566687998 AFT1PSI1: 8 Vector__XXX
 SG_ TimeBetweenRegens : 40|16@1+ (6,0) [0|385530] "s" Vector__XXX
 SG_ ActiveAccumulationTime : 24|16@1+ (6,0) [0|385530] "s" Vector__XXX
 SG_ RegenSt : 20|4@1+ (1,0) [0|15] "" Vector__XXX
 SG_ RegenStatus : 18|2@1+ (1,0) [0|3] "" Vector__XXX
 SG_ HtrSt : 16|2@1+ (1,0) [0|3] "" Vector__XXX
 SG_ Res : 0|16@1+ (1,0) [0|62500] "kohm" Vector__XXX

BO_ 2566687742 AFT1PSI2: 8 Vector__XXX
 SG_ HtrRes : 40|16@1+ (0.1,0) [0|6425.5] "ohm" Vector__XXX
 SG_ MaxRes : 32|16@1+ (250,0) [0|62500] "kohm" Vector__XXX
 SG_ Temp : 16|16@1+ (0.03125,-273) [-273|1734.96875] "°C" Vector__XXX
 SG_ RegenFailedCount : 8|8@1+ (1,0) [0|250] "" Vector__XXX
 SG_ PwrSupply : 4|2@1+ (1,0) [0|3] "" Vector__XXX
 SG_ DetectionStatus : 0|4@1+ (1,0) [0|15] "" Vector__XXX

BO_ 2365348350 ELS: 8 Vector__XXX
 SG_ EngLoadShareStatus : 2|4@1+ (1,0) [0|15] "" Vector__XXX
 SG_ EngUnloadStatus : 0|2@1+ (1,0) [0|3] "" Vector__XXX

BO_ 2566674686 TCI7: 8 Vector__XXX
 SG_ EngTurbo4LubeOilPress : 16|8@1+ (4,0) [0|1000] "kPa" Vector__XXX
 SG_ EngTurbo3LubeOilPress : 8|8@1+ (4,0) [0|1000] "kPa" Vector__XXX
 SG_ EngTurbo2LubeOilPress : 0|8@1+ (4,0) [0|1000] "kPa" Vector__XXX

BO_ 2566674430 SCROII1: 8 Vector__XXX
 SG_ DslExhstFldQalityMalfunctionTime : 32|32@1+ (1,0) [0|4211081215] "s" Vector__XXX
 SG_ DieselExhaustFluidTank1EmptyTime : 0|32@1+ (1,0) [0|4211081215] "s" Vector__XXX

BO_ 2566674174 SCROII2: 8 Vector__XXX
 SG_ SCROperatorInducementTotalTime : 32|32@1+ (1,0) [0|4211081215] "s" Vector__XXX
 SG_ AFTSCRMalfunctionTime : 0|32@1+ (1,0) [0|4211081215] "s" Vector__XXX

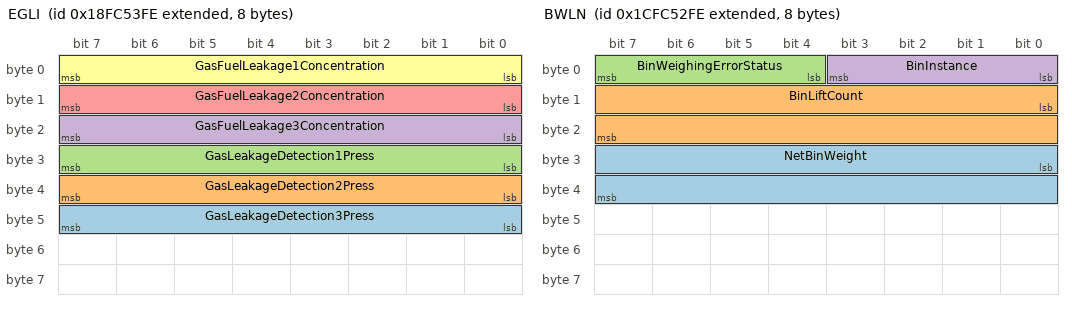
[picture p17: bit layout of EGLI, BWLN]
BO_ 2566673406 EGLI: 8 Vector__XXX
 SG_ GasLeakageDetection3Press : 40|8@1+ (4,0) [0|100] "kPa" Vector__XXX
 SG_ GasLeakageDetection2Press : 32|8@1+ (4,0) [0|100] "kPa" Vector__XXX
 SG_ GasLeakageDetection1Press : 24|8@1+ (4,0) [0|100] "kPa" Vector__XXX
 SG_ GasFuelLeakage3Concentration : 16|8@1+ (0.5,0) [0|100] "%" Vector__XXX
 SG_ GasFuelLeakage2Concentration : 8|8@1+ (0.5,0) [0|100] "%" Vector__XXX
 SG_ GasFuelLeakage1Concentration : 0|8@1+ (0.5,0) [0|100] "%" Vector__XXX

BO_ 2633782014 BWLN: 8 Vector__XXX
 SG_ NetBinWeight : 24|16@1+ (2,0) [0|128510] "kg" Vector__XXX
 SG_ BinLiftCount : 8|16@1+ (1,0) [0|64255] "" Vector__XXX
 SG_ BinWeighingErrorStatus : 4|4@1+ (1,0) [0|15] "" Vector__XXX
 SG_ BinInstance : 0|4@1+ (1,0) [0|15] "" Vector__XXX

BO_ 2365346302 ASC7: 8 Vector__XXX
 SG_ LiftAxle2Status : 3|3@1+ (1,0) [0|7] "" Vector__XXX
 SG_ LiftAxle1Status : 0|3@1+ (1,0) [0|7] "" Vector__XXX

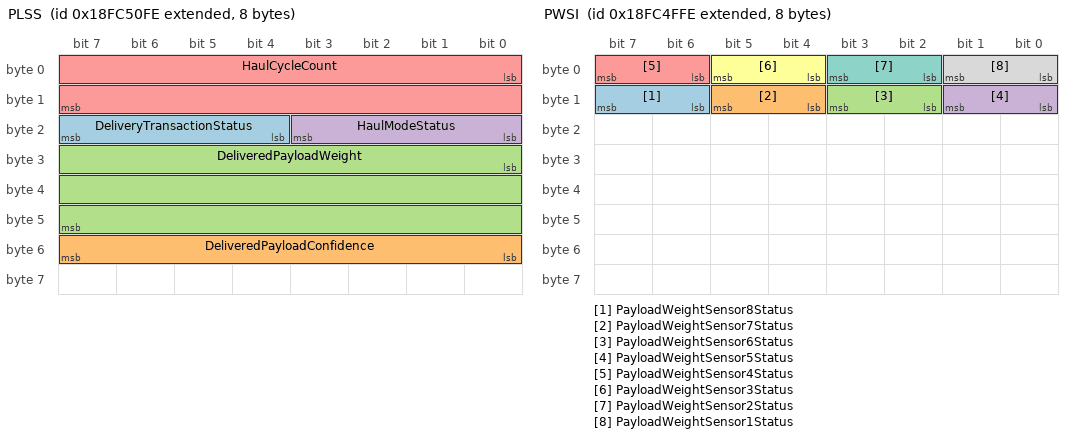
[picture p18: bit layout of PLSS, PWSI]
BO_ 2566672638 PLSS: 8 Vector__XXX
 SG_ DeliveryTransactionStatus : 20|4@1+ (1,0) [0|15] "" Vector__XXX
 SG_ DeliveredPayloadConfidence : 48|8@1+ (0.5,0) [0|100] "%" Vector__XXX
 SG_ DeliveredPayloadWeight : 24|24@1+ (2,0) [0|32899070] "kg" Vector__XXX
 SG_ HaulModeStatus : 16|4@1+ (1,0) [0|15] "" Vector__XXX
 SG_ HaulCycleCount : 0|16@1+ (1,0) [0|64255] "" Vector__XXX

BO_ 2566672382 PWSI: 8 Vector__XXX
 SG_ PayloadWeightSensor8Status : 14|2@1+ (1,0) [0|3] "" Vector__XXX
 SG_ PayloadWeightSensor7Status : 12|2@1+ (1,0) [0|3] "" Vector__XXX
 SG_ PayloadWeightSensor6Status : 10|2@1+ (1,0) [0|3] "" Vector__XXX
 SG_ PayloadWeightSensor5Status : 8|2@1+ (1,0) [0|3] "" Vector__XXX
 SG_ PayloadWeightSensor4Status : 6|2@1+ (1,0) [0|3] "" Vector__XXX
 SG_ PayloadWeightSensor3Status : 4|2@1+ (1,0) [0|3] "" Vector__XXX
 SG_ PayloadWeightSensor2Status : 2|2@1+ (1,0) [0|3] "" Vector__XXX
 SG_ PayloadWeightSensor1Status : 0|2@1+ (1,0) [0|3] "" Vector__XXX

BO_ 2566672126 A1SCRDSI3: 8 Vector__XXX
 SG_ DEFDoser2Temp : 16|8@1+ (1,-40) [-40|210] "°C" Vector__XXX
 SG_ DEFDoser2AbsPress : 8|8@1+ (8,0) [0|2000] "kPa" Vector__XXX
 SG_ DEFDosingPress : 0|8@1+ (4,0) [0|1000] "kPa" Vector__XXX

BO_ 2566671870 A2SCRDSI3: 8 Vector__XXX
 SG_ DEFDosing2Temp : 16|8@1+ (1,-40) [-40|210] "°C" Vector__XXX
 SG_ DEFDoser2AbsPress : 8|8@1+ (8,0) [0|2000] "kPa" Vector__XXX
 SG_ DEFDosingPress : 0|8@1+ (4,0) [0|1000] "kPa" Vector__XXX

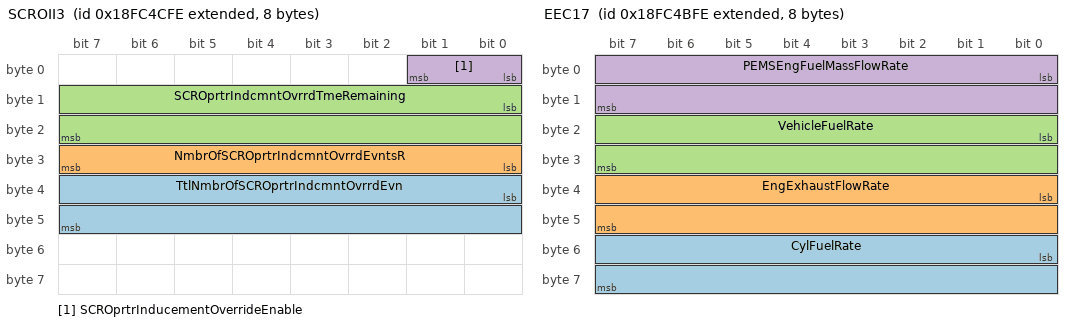
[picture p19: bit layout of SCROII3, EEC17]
BO_ 2566671614 SCROII3: 8 Vector__XXX
 SG_ TtlNmbrOfSCROprtrIndcmntOvrrdEvn : 32|16@1+ (1,0) [0|64255] "" Vector__XXX
 SG_ NmbrOfSCROprtrIndcmntOvrrdEvntsR : 24|8@1+ (1,0) [0|250] "" Vector__XXX
 SG_ SCROprtrIndcmntOvrrdTmeRemaining : 8|16@1+ (1,0) [0|64255] "s" Vector__XXX
 SG_ SCROprtrInducementOverrideEnable : 0|2@1+ (1,0) [0|3] "" Vector__XXX

BO_ 2566671358 EEC17: 8 Vector__XXX
 SG_ CylFuelRate : 48|16@1+ (0.03125,0) [0|2007.96875] "mg/stroke" Vector__XXX
 SG_ EngExhaustFlowRate : 32|16@1+ (0.2,0) [0|12851] "kg/h" Vector__XXX
 SG_ VehicleFuelRate : 16|16@1+ (0.02,0) [0|1285.1] "g/s" Vector__XXX
 SG_ PEMSEngFuelMassFlowRate : 0|16@1+ (0.02,0) [0|1285.1] "g/s" Vector__XXX

CM_ BU_ PowertrainControlModule "Electronic control module in charge of controlling and coordinating the operation of a hybrid propulsion system.";
CM_ BU_ HitchControl "Straight truck hitch (NOT Agricultural hitch – it is in IG 2) ";
CM_ BO_ 3221225472 "This is a message for not used signals, created by Vector CANdb++ DBC OLE DB Provider.";
CM_ SG_ 3221225472 HVES1HVBPsvITR_8432 "See HVES1 High-Voltage Bus Passive Isolation Test Status (SPN 8097) for test status and HVES1 High-Voltage Bus Active Isolation Test Command (SPN 8126) for the command to run the test.";
CM_ SG_ 3221225472 HVES1HVBAcvITR_8431 "See HVES1 High-Voltage Bus Active Isolation Test Status (SPN 8096) for test status and HVES1 High-Voltage Bus Active Isolation Test Command (SPN 8125) for the command to run the test.";
CM_ SG_ 3221225472 HVES1LoCellStOChaCellNo_8248 "Identifies the location of the HVES1 Lowest Cell State of Charge (SPN 8084) within the HVES1 Lowest Cell State of Charge Module Number (SPN 8247).";
CM_ SG_ 3221225472 HVES1LoCellStOChaModuNo_8247 "Identifies the location of the HVES1 Highest Cell State of Charge (SPN 8085) within the HVES1 Highest Cell State of Charge Module Number (SPN 8245).";
CM_ SG_ 3221225472 HVES1HiCellStOChaCellNo_8246 "Identifies the location of the HVES1 Highest Cell State of Charge (SPN 8085) within the HVES1 Highest Cell State of Charge Module Number (SPN 8245).";
CM_ SG_ 3221225472 HVES1HiCellStOChaModuNo_8245 "Identifies the location of the module containing the HVES1 Highest Cell State of Charge (SPN 8085).";
CM_ SG_ 3221225472 TranIdleGovrnrFuelingInhbit_7829 "This parameter is a command provided to the Engine Control Module (ECM) from the Transmission Control Module (TCM) to inhibit idle governor fueling in the unlikely event that transmission has detected a failure preventing driveline disengagement.";
CM_ SG_ 3221225472 NumberOfMembersInWorkingSet "The number of members in a particular Working Set.";
CM_ SG_ 3221225472 SourceAddress "Instance of a Source Address listed a Network Message data field.";
CM_ SG_ 3221225472 NncntnuslyMonitoredSystemsStatus "Identifies the non-continuously monitored systems status. Each bit identifies whether a particular test is complete for a given controller.
";
CM_ SG_ 3221225472 NncntnslyMonitoredSystemsSupport "Identifies the non-continuously monitored systems support.
";
CM_ SG_ 3221225472 CntnslyMntrdSystmsSupport_Status "Identifies the continuously monitored system support and status.
";
CM_ SG_ 3221225472 AETCTorqueValue "Engine torque value of the data points in PGN 64912 – Advertised Engine Torque Curve (AETC).";
CM_ SG_ 3221225472 TrailerWeight "Total mass of freight-carrying vehicle designed to be pulled by truck, including the weight of the contents.";
CM_ SG_ 3221225472 ReferenceTirePressSetting "Reference value of the tire pressure setting as basis for the tire pressure monitoring ...";
CM_ SG_ 3221225472 ReferenceTirePress "Reference value of the tire pressure as basis for the tire pressure monitoring ...";
CM_ SG_ 3221225472 TirePressThresholdDetection "Signal indicating the pressure level of the tire.  The levels defined represent different pressure conditions of the tire: 000 Extreme over pressure - The tire pressure is at a level where the safety of the vehicle may be jeopardised.";
CM_ SG_ 3221225472 TireAirLeakageRate "The pressure loss rate of a tire.";
CM_ SG_ 3221225472 CTIWheelEndElectricalFault "Indicates the status of electrical fault on CTI wheel interface.";
CM_ SG_ 3221225472 CTITireStatus "Indicates the status of the tire.";
CM_ SG_ 3221225472 CTIWheelSensorStatus "Indicates whether the wheel is being monitored by the CTI controller.";
CM_ SG_ 3221225472 TireTemp "Temperature at the surface of the tire sidewall.";
CM_ SG_ 3221225472 TirePress "Pressure at which air is contained in cavity formed by tire and rim.";
CM_ SG_ 3221225472 EngTurningGearEngaged "Status signal which indicates that the turning gear is engaged.  The turning gear is used to turn the flywheel/crankshaft, ...";
CM_ SG_ 3221225472 AETCSpeedValue "Engine speed value of the data points in PGN 64912 – Advertised Engine Torque Curve (AETC).";
CM_ BO_ 2364607475 "Data set 9 (thermal) for High Voltage Energy Storage pack (or system) 1.";
CM_ SG_ 2364607475 HVES1LoCellTModuNo_8243 "Identifies the location of the module containing the HVES1 Highest Cell Temperature (SPN 8075).";
CM_ SG_ 2364607475 HVES1LoCellTCellNo_8244 "Identifies the location of the HVES1 Highest Cell Temperature (SPN 8075) within the HVES1 Highest Cell Temperature Module Number (SPN 8241).";
CM_ SG_ 2364607475 HVES1HiCellTModuNo_8241 "Identifies the location of the module containing the HVES1 Highest Cell Voltage (SPN 5922).";
CM_ SG_ 2364607475 HVES1HiCellTCellNo_8242 "ntifies the location of HVES1 Highest Cell Voltage (SPN 5922) within the HVES1 Highest Cell Voltage Module Number (SPN 8236).";
CM_ BO_ 2364607219 "Data set 8 (electrical data) for High Voltage Energy Storage pack (or system) 1.";
CM_ SG_ 2364607219 HVES1AvgCellU_8240 "The average cell voltage in the High Voltage Energy Storage 1 pack (or system).";
CM_ SG_ 2364607219 HVES1LoCellUModuNo_8238 "Identifies the location of the module containing the HVES1 Lowest Cell Temperature (SPN 8076).";
CM_ SG_ 2364607219 HVES1LoCellUCellNo_8239 "Identifies the location of the HVES1 Lowest Cell Temperature (SPN 8076) within the HVES1 Lowest Cell Temperature Module Number (SPN 8243).";
CM_ SG_ 2364607219 HVES1HiCellUModuNo_8236 "Identifies the location of the module containing the HVES1 Highest Cell Voltage (SPN 5922).";
CM_ SG_ 2364607219 HVES1HiCellUCellNo_8237 "ntifies the location of HVES1 Highest Cell Voltage (SPN 5922) within the HVES1 Highest Cell Voltage Module Number (SPN 8236).";
CM_ BO_ 2364606707 "Module Status message 1 for High Voltage Energy Storage pack (or system) 1.";
CM_ SG_ 2364606707 HVES1M11OperlSts_8224 "Not Operational is used when the module is initializing or not able to function (e.g. internal module level monitors have failed).  Operational indicates that the module is fully functional.  Error is used when the module status is not known.";
CM_ SG_ 2364606707 HVES1M9OperlSts_8222 "Not Operational is used when the module is initializing or not able to function (e.g. internal module level monitors have failed).  Operational indicates that the module is fully functional.  Error is used when the module status is not known.";
CM_ SG_ 2364606707 HVES1M8OperlSts_8221 "Not Operational is used when the module is initializing or not able to function (e.g. internal module level monitors have failed).  Operational indicates that the module is fully functional.  Error is used when the module status is not known.";
CM_ SG_ 2364606707 HVES1M7OperlSts_8220 "Not Operational is used when the module is initializing or not able to function (e.g. internal module level monitors have failed).  Operational indicates that the module is fully functional.  Error is used when the module status is not known.";
CM_ SG_ 2364606707 HVES1M6OperlSts_8219 "Not Operational is used when the module is initializing or not able to function (e.g. internal module level monitors have failed).  Operational indicates that the module is fully functional.  Error is used when the module status is not known.";
CM_ SG_ 2364606707 HVES1M5OperlSts_8218 "Not Operational is used when the module is initializing or not able to function (e.g. internal module level monitors have failed).  Operational indicates that the module is fully functional.  Error is used when the module status is not known.";
CM_ SG_ 2364606707 HVES1M4OperlSts_8217 "Not Operational is used when the module is initializing or not able to function (e.g. internal module level monitors have failed).  Operational indicates that the module is fully functional.  Error is used when the module status is not known.";
CM_ SG_ 2364606707 HVES1M3OperlSts_8216 "Not Operational is used when the module is initializing or not able to function (e.g. internal module level monitors have failed).  Operational indicates that the module is fully functional.  Error is used when the module status is not known.";
CM_ SG_ 2364606707 HVES1M2OperlSts_8215 "Not Operational is used when the module is initializing or not able to function (e.g. internal module level monitors have failed).  Operational indicates that the module is fully functional.  Error is used when the module status is not known.";
CM_ SG_ 2364606707 HVES1M1OperlSts_8214 "Not Operational is used when the module is initializing or not able to function (e.g. internal module level monitors have failed).  Operational indicates that the module is fully functional.  Error is used when the module status is not known.";
CM_ SG_ 2364606707 HVES1M16OperlSts_8229 "Not Operational is used when the module is initializing or not able to function (e.g. internal module level monitors have failed).  Operational indicates that the module is fully functional.  Error is used when the module status is not known.";
CM_ SG_ 2364606707 HVES1M15OperlSts_8228 "Not Operational is used when the module is initializing or not able to function (e.g. internal module level monitors have failed).  Operational indicates that the module is fully functional.  Error is used when the module status is not known.";
CM_ SG_ 2364606707 HVES1M14OperlSts_8227 "Not Operational is used when the module is initializing or not able to function (e.g. internal module level monitors have failed).  Operational indicates that the module is fully functional.  Error is used when the module status is not known.";
CM_ SG_ 2364606707 HVES1M13OperlSts_8226 "Not Operational is used when the module is initializing or not able to function (e.g. internal module level monitors have failed).  Operational indicates that the module is fully functional.  Error is used when the module status is not known.";
CM_ SG_ 2364606707 HVES1M12OperlSts_8225 "Not Operational is used when the module is initializing or not able to function (e.g. internal module level monitors have failed).  Operational indicates that the module is fully functional.  Error is used when the module status is not known.";
CM_ SG_ 2364606707 HVES1M10OperlSts_8223 "Not Operational is used when the module is initializing or not able to function (e.g. internal module level monitors have failed).  Operational indicates that the module is fully functional.  Error is used when the module status is not known.";
CM_ BO_ 2364552947 "Status data set 2 for High Voltage Energy Storage pack (or system) 1.";
CM_ SG_ 2364552947 HVES1CPLDToUndefCause_8114 "Indicates whether or not HVES1 charge power is being limited due to an undefined cause.";
CM_ SG_ 2364552947 HVES1CPLDTBT_8110 "Indicates whether or not HVES1 charge power is being limited due to battery temperature.";
CM_ SG_ 2364552947 HVES1CPLDTBOrCellV_8112 "Indicates whether or not HVES1 charge power is being limited due to a battery or cell voltage level.";
CM_ SG_ 2364552947 HVES1CPLDTBDiagcCdn_8111 "Indicates whether or not HVES1 charge power is being limited due to a battery diagnostic condition.";
CM_ SG_ 2364552947 HVES1CPLDTBCur_8113 "Indicates whether or not HVES1 charge power is being limited due to battery current.";
CM_ SG_ 2364552947 HVES1DPLDTStOfCha_8109 "Indicates whether or not HVES1 charge power is being limited due to state of charge.";
CM_ SG_ 2364552947 HVES1DPLDTStOfCha_8103 "Indicates whether or not HVES1 discharge power is being limited due to state of charge.";
CM_ SG_ 2364552947 HVES1DPLDToUndefCause_8108 "Indicates whether or not HVES1 discharge power is being limited due to an undefined cause.";
CM_ SG_ 2364552947 HVES1DPLDTBT_8104 "Indicates whether or not HVES1 discharge power is being limited due to battery temperature.";
CM_ SG_ 2364552947 HVES1DPLDTBOrCellV_8106 "Indicates whether or not HVES1 discharge power is being limited due to a battery or cell voltage level.";
CM_ SG_ 2364552947 HVES1DPLDTBDiagcCdn_8105 "Indicates whether or not HVES1 discharge power is being limited due to a battery diagnostic condition.";
CM_ SG_ 2364552947 HVES1DPLDTBCur_8107 "Indicates whether or not HVES1 discharge power is being limited due to battery current.";
CM_ BO_ 2633785075 "Historical data for High Voltage Energy Storage pack (or system) 1.";
CM_ SG_ 2633785075 HVES1TotEgyThput_8211 "The total energy throughput which has flowed through High Voltage Energy Storage 1 pack (or system).  This parameter is the sum of the absolute values of the Energy into and out of HVES1.  ";
CM_ SG_ 2633785075 HVES1TotAccumCha_8212 "The total accumulated amp hours which have flowed through High Voltage Energy Storage 1 pack (or system).  This parameter is the sum of the absolute values of the Ampere hours into and out of HVES1.  ";
CM_ SG_ 2633785075 HVES1StOfHealth_8121 "This value should begin at 100%, and end at 0% when “no” energy is able to be put in or taken out.  “No” could be absolute zero, or it could be some rated value of the pack.";
CM_ SG_ 2633785075 HVES1CtorOpenUndLoa_8122 "The current level shall be defined by the HVES manufacturer, but in general should be a level at which the contactor life may be reduced if repeated cycles occur.";
CM_ BO_ 2566675955 "Configuration data for High Voltage Energy Storage pack (or system) 1.  Note that configuration data should not dynamically change during vehicle operation.";
CM_ SG_ 2566675955 HVES1RecomMinSOC_8118 "Per the HVES manufacturer, this is the recommended minimum state of charge for High Voltage Energy Storage 1 pack (or system) operation.  Operating below this value may compromise HVES life.";
CM_ SG_ 2566675955 HVES1RecomMinOpergV_8116 "Per the HVES manufacturer, this is the minimum recommended voltage level for High Voltage Energy Storage 1 pack (or system) operation.  Operating below this value may compromise HVES life.";
CM_ SG_ 2566675955 HVES1RecomMinOpergT_8208 "Per the HVES manufacturer, this is the recommended minimum temperature for High Voltage Energy Storage 1 pack (or system) operation.  Operating below this value may damage HVES hardware, or compromise HVES life.";
CM_ SG_ 2566675955 HVES1RecomMaxSOC_8119 "Per the HVES manufacturer, this is the recommended maximum state of charge for High Voltage Energy Storage 1 pack (or system) operation.  Operating above this value may compromise HVES life.";
CM_ SG_ 2566675955 HVES1RecomMaxOpergV_8117 "Per the HVES manufacturer, this is the maximum recommended voltage level for High Voltage Energy Storage 1 pack (or system) operation.  Operating above this value may compromise HVES life.";
CM_ SG_ 2566675955 HVES1RecomMaxOpergT_8120 "Per the HVES manufacturer, this is the recommended maximum temperature for High Voltage Energy Storage 1 pack (or system) operation.  Operating above this value may damage HVES hardware, or compromise HVES life.";
CM_ SG_ 2566675955 HVES1NomVoltage_8115 "Per the HVES manufacturer, this is the nominal operating voltage of the High Voltage Energy Storage 1 pack (or system), e.g. “300V” or “600V”.";
CM_ SG_ 2566675955 HVES1CellMinVLim_8210 "Per the HVES manufacturer, this is the minimum cell voltage for High Voltage Energy Storage 1 pack (or system) operation.  Operating below this value may damage HVES hardware, or compromise HVES life.";
CM_ SG_ 2566675955 HVES1CellMaxVLim_8209 "Per the HVES manufacturer, this is the maximum cell voltage for High Voltage Energy Storage 1 pack (or system) operation.  Operating above this value may damage HVES hardware, or compromise HVES life.";
CM_ BO_ 2364606963 "A collection of data that High Voltage Energy Storage 1 Thermal Management System sends to the Hybrid Controller.";
CM_ SG_ 2364606963 HVES1TMSSLIInPwr_8230 "In multiple HVES configurations, this is the low-voltage power consumed by the HVES1 Thermal Management System (TMS).   If there is only one HVES, or a single TMS for all HVES, then this represents the total low-voltage power consumed.  ";
CM_ SG_ 2364606963 HVES1TMSRelHum_8233 "When the High Voltage Energy Storage 1 Thermal Management System is equipped with a relative humidity sensor, this is the  measured Relative Humidity.";
CM_ SG_ 2364606963 HVES1TMSMode_8235 " The heat transfer medium may be (e.g. liquid or air).  The cooling system may be fans, liquid coolant, or a combination of mediums.  The system may include an air and/or liquid conditioning system with active Cooling, Heating, and/or Drying capabilities.";
CM_ SG_ 2364606963 HVES1TMSHighV_8231 "In multiple HVES configurations, this is the high-voltage power consumed by the HVES1 Thermal Management System (TMS).   If there is only one HVES, or a single TMS for all HVES, then this represents the total high voltage power consumed.";
CM_ SG_ 2364606963 HVES1TMSHeatrSts_8234 "This is the state of the High Voltage Energy Storage 1 heater";
CM_ SG_ 2364606963 HVES1TMSCpsr_8232 "When the High Voltage Energy Storage 1 Thermal Management System is equipped with an active cooling system (e.g. air conditioner), this is the Compressor Speed.";
CM_ BO_ 2364580083 "Data set 7 (electrical) for High Voltage Energy Storage pack (or system) 1.";
CM_ SG_ 2364580083 HVES1MaxChaVLim_8090 "The maximum voltage level not to be exceeded while charging the High Voltage Energy Storage 1 pack (or system).  If this parameter is not supported, the maximum charge voltage should be limited to SPN 8117 (HVES1 Recommended Maximum Operating Voltage).";
CM_ SG_ 2364580083 HVES1DischaEgyCp_8205 "The amount of stored electrical energy in High Voltage Energy Storage 1 pack (or system) that is available for use by the hybrid system, i.e. “how full is the tank”.  See HVES1 Discharge Capacity (SPN 8079) for Ampere-hours (Ah).";
CM_ SG_ 2364580083 HVES1ChaEgyCp_8206 "The amount of stored electrical energy in High Voltage Energy Storage 1 pack (or system) that is available for use by the hybrid system, i.e. “how full is the tank”.  See HVES1 Discharge Capacity (SPN 8079) for Ampere-hours (Ah).";
CM_ BO_ 2364577523 "Status data set 1 for High Voltage Energy Storage pack (or system) 1.";
CM_ SG_ 2364577523 HVES1StOfChaSts_8100 "Status of the High Voltage Energy Storage 1 pack (or system) State of Charge (SOC).  Note:  A given HVES controller may not support all of the states.";
CM_ SG_ 2364577523 HVES1OperationlSts_8414 "Provides feedback on where the HVES1 pack (or system) is in its operating spectrum, and includes feedback in response to the Operation Consent [i.e. HVES1 Operation Consent (SPN 8412)] and Power Down Command";
CM_ SG_ 2364577523 HVES1IntChaSts_8207 "Indicates that the charger in the HVES1 is on.  External chargers may use the External Energy Source Connection Status (SPN 7898) and related SPNs.";
CM_ SG_ 2364577523 HVES1InertiaSwtSts_8099 "Switch indicating that an impact has been sensed by the HVES1 pack (or system).   May require action.  For example, a controller may elect to take HVES1 off-line to reduce an electrocution hazard during or after a vehicle crash.";
CM_ SG_ 2364577523 HVES1HVILSts_8098 "Status of the High Voltage Interlock Loop from the viewpoint of the High Voltage Energy Storage 1 pack (or system).";
CM_ SG_ 2364577523 HVES1HVBusPsvIsoTstSts_8097 "Status of the high-voltage bus electrical passive isolation test as performed by the High Voltage Energy Storage 1 pack (or system).";
CM_ SG_ 2364577523 HVES1HVBusPrechaRlySt_8094 " Position of the high-voltage bus contactor pre-charge relay.  When this relay is closed, the High Voltage Energy Storage 1 pack (or system) is bringing the high-voltage bus up to its operating level.";
CM_ SG_ 2364577523 HVES1HVBusDiscnctWarn_8093 "Indicates that the High Voltage Energy Storage 1 pack (or system) is about to disconnect from the high voltage bus due to unacceptable conditions.";
CM_ SG_ 2364577523 HVES1HVBusCnctnSts_8413 "This parameter provides high level feedback on the HVES1 pack (or system) high voltage bus connection.  For specific contactor information, see  (SPN 8091),  (SPN 8095), and  (SPN 8094).";
CM_ SG_ 2364577523 HVES1HVBusAcvIsoTstSts_8096 "Status of the high-voltage bus electrical active isolation test as performed by the High Voltage Energy Storage 1 pack (or system).";
CM_ SG_ 2364577523 HVES1HVBCtorStPos_8091 " When this contactor is closed, the positive side of HVES1 is connected to the positive side.  In systems where all contactors are controlled as a single unit, this parameter may be used to convey the overall contactor status.";
CM_ SG_ 2364577523 HVES1HVBCtorStNeg_8092 " If a system controls the positive, negative, and center contactors as a single unit, then SPN 8091 should be used to convey overall contactor status.";
CM_ SG_ 2364577523 HVES1CtrOfPackCtorSt_8095 " When this contactor is closed, the positive half of the HVES1 pack (or system) is connected to the negative half.  If a system controls the positive, negative, and center contactors as a single unit, then SPN 8091 should be used.";
CM_ SG_ 2364577523 HVES1CellBalnSts_8101 "Indicates whether or not the cells in the High Voltage Energy Storage 1 pack (or system) are balanced.";
CM_ BO_ 2364577267 "Data set 6 (external or interface data) for High Voltage Energy Storage pack (or system) 1.";
CM_ SG_ 2364577267 HVES1ElectronicsT_8204 "The temperature of the electronics or control modules in the High Voltage Energy Storage 1 pack (or system).  If there are mulitple temperature sensors then this parameter would be set to the maximum sensor reading.";
CM_ SG_ 2364577267 HVES1OutletCooltT_8089 "The temperature of liquid coolant as it exits the High Voltage Energy Storage 1 pack (or system).";
CM_ SG_ 2364577267 HVES1InletCooltT_8088 "The temperature of liquid coolant as it enters the High Voltage Energy Storage 1 pack (or system).";
CM_ SG_ 2364577267 HVES1IgVoltage_8087 "The voltage level at the ignition input of the High Voltage Energy Storage 1 pack (or system) controller.";
CM_ SG_ 2364577267 HVES1BusVoltage_8086 "The voltage level of the high voltage bus, as measured by the High Voltage Energy Storage 1 pack (or system) on the bus side (not the battery side) of its contactors.";
CM_ BO_ 2364577011 "Data set 5 (electrical data) for High Voltage Energy Storage pack (or system) 1.";
CM_ SG_ 2364577011 HVES1MinCellStOCha_8084 "Indicates the state of charge of the lowest-charged cell in the High Voltage Energy Storage 1 pack (or system).  0% means no charge remaining, 100% means the cell is fully charged.   If a single state of charge value covers more than one cell, the value";
CM_ SG_ 2364577011 HVES1MaxCellStOCha_8085 "Indicates the state of charge of the highest-charged cell in the High Voltage Energy Storage 1 pack (or system).  0% means no charge remaining, 100% means the cell is fully charged.  If a single state of charge value covers more than one cell";
CM_ SG_ 2364577011 HVES1DchaCurLim_8082 "The maximum permissible current flow out of the High Voltage Energy Storage 1 pack (or system).  This parameter is defined from the high voltage energy storage system's point of view.  A negative value represents current flowing out of";
CM_ SG_ 2364577011 HVES1ChaCurLim_8083 "The maximum permissible current flow into the High Voltage Energy Storage 1 pack (or system).  This parameter is defined from the high voltage energy storage system's point of view.  A positive value represents current flowing into";
CM_ BO_ 2364576755 "Data set 4 (electrical data) for High Voltage Energy Storage pack (or system) 1.";
CM_ SG_ 2364576755 HVES1DischargeCap_8079 "The amount of stored electrical charge in the High Voltage Energy Storage 1 pack (or system) that is available for use by the hybrid system, i.e. “how full is the tank”.  See HVES1 Discharge Energy Capacity (SPN 8205) for kilowatt-hours (kWh).";
CM_ SG_ 2364576755 HVES1ChargeCap_8080 "The amount of unused electrical charge storage in the High Voltage Energy Storage 1 pack (or system) that is available to be filled by charging, i.e. “how much empty space is remaining in the tank”.  See HVES1 Charge Energy Capacity (SPN 8206)";
CM_ SG_ 2364576755 HVES1CellBalnCt_8081 "The number of cells that are currently being balanced in the High Voltage Energy Storage 1 pack (or system).";
CM_ BO_ 2364576499 "Data set 3 (thermal data) for High Voltage Energy Storage pack (or system) 1.";
CM_ SG_ 2364576499 HVES1LowestCellT_8076 "The lowest temperature level reported by any cell in the High Voltage Energy Storage 1 pack (or system).  If a single temperature sensor covers more than one cell, the value in this parameter is for the smallest group of cells measured.";
CM_ SG_ 2364576499 HVES1HighestCellT_8075 "The highest temperature level reported by any cell in the High Voltage Energy Storage 1 pack (or system).  If a single temperature sensor covers more than one cell, the value in this parameter is for the smallest group of cells measured.";
CM_ SG_ 2364576499 HVES1AverageCellT_8077 "The average temperature level of all cells in the High Voltage Energy Storage 1 pack (or system).";
CM_ BO_ 2364576243 "Data set 2 (electrical data) for High Voltage Energy Storage pack (or system) 1.";
CM_ SG_ 2364576243 HVES1LowCellVolt_5923 "The lowest voltage level reported by any cell in the High Voltage Energy Storage 1 pack (or system).   If a single voltage sensor covers more than one cell, the value in this parameter is for the smallest group of cells measured.  See HVES1 Lowest";
CM_ SG_ 2364576243 HVES1HiCellVolt_5922 "Highest Cell Voltage Cell Number (SPN 8237) for cell location information.";
CM_ SG_ 2364576243 HVES1FastUpdStOCh_5921 "Indicates the High Voltage Energy Storage 1 pack (or system) state of charge.  0% means no charge remaining, 100% means the system is fully charged in terms of physical limits of the energy storage system.  Acceptable state of charge upper and";
CM_ SG_ 2364576243 HVES1CellVoltDftlSts_5924 "Indicates whether or not the differential between the highest and lowest cell voltages are within acceptable limits, according to the High Voltage Energy Storage 1 pack (or system).   The actual voltage differential can be calculated by ";
CM_ BO_ 2364575987 "Data set 1 (electrical data) for High Voltage Energy Storage pack (or system) 1.";
CM_ SG_ 2364575987 HVES1VoltageLevel_5919 "The voltage level of the High Voltage Energy Storage 1 pack (or system).  This parameter should be synchronized with SPN 5920 (HVES1 Current) such that a realized power value can be calculated.  If the HVES component physically ";
CM_ SG_ 2364575987 HVES1Current_5920 "The current in or out of the High Voltage Energy 
";
CM_ SG_ 2364575987 HVES1AvlChPwr_5918 "The rate at which the High Voltage Energy Storage 1 pack (or system) can currently receive energy from a regenerative or recharging system.";
CM_ SG_ 2364575987 HVES1AvlDchaPwr_5917 "The rate at which the High Voltage Energy Storage 1 pack (or system) can currently provide energy for propulsion or other uses.";
CM_ BO_ 2558263038 "Electrified Accessory Power Electronics Coolant Pump Command - The command message to the electrified accessory: Power Electronics Coolant Pump.  See PGN 64511 for the corresponding status message.";
CM_ SG_ 2558263038 PECPSC_7969 "Speed command to the Power Electronics Coolant Pump.
";
CM_ SG_ 2558263038 PECPPS_7970 "Power Electronics Coolant Pump Percent Speed Command";
CM_ SG_ 2558263038 PECPPH_7968 "Command to allow the Power Electronics Coolant Pump to remain alive independently of the electrical enable input to the Accessory Motor.  
00 - Power Hold Disabled
01 - Power Hold Enabled
10 - Reserved
11 - Don't Care/Take no action";
CM_ SG_ 2558263038 PECPEC_7967 "Enable and direction command to the Power Electonics Coolant Pump.

00 - Accessory Motor Off
01 - Accessory Motor On Normal/Default Direction
10 - Accessory Motor On Reverse Direction
11 - Don't Care/Take no action";
CM_ BO_ 2558197502 "Electrified Accessory Propulsion Motor Coolant Pump Command - The command message to the electrified accessory: Propulsion Motor Coolant pump.  See PGN 64510 for the corresponding status message.";
CM_ SG_ 2558197502 PMCPPS_7982 "Speed command to the Propulsion Motor Coolant Pump in percentage of maximum speed.";
CM_ SG_ 2558197502 PMCPSC_7981 "Speed command to the Propulsion Motor Coolant Pump. ";
CM_ SG_ 2558197502 PMCPPH_7980 "Command to allow the Propulsion Motor Coolant Pump to remain alive independently of the electrical enable input to the Accessory Motor. 
00 - Power Hold Disabled
01 - Power Hold Enabled
10 - Reserved
11 - Don't Care/Take no action";
CM_ SG_ 2558197502 PMCPEC_7979 "Enable and direction command to the Propulsion Motor Coolant Pump.

00 - Accessory Motor Off
01 - Accessory Motor On Normal/Default Direction
10 - Accessory Motor On Reverse Direction
11 - Don't Care/Take no action";
CM_ BO_ 2558131966 "Electrified Accessory Propulsion Motor Oil Pump Command - The command message to the electrified accessory: Propulsion Motor Oil pump.  See PGN 64509 for the corresponding status message.";
CM_ SG_ 2558131966 PMOPPSC_7994 "Speed command to the Propulsion Motor Oil Pump in percentage of maximum speed.
";
CM_ SG_ 2558131966 PMOPSC_7993 "Speed command to the Propulsion Motor Oil Pump. ";
CM_ SG_ 2558131966 PMOPPH_7992 "Command to allow the Propulsion Motor Oil Pump to remain alive independently of the electrical enable input to the Accessory Motor.
00 - Power Hold Disabled
01 - Power Hold Enabled
10 - Reserved
11 - Don't Care/Take no action";
CM_ SG_ 2558131966 PMOPEC_7991 "Enable and direction command to the Propulsion Motor Oil Pump.

00 - Accessory Motor Off
01 - Accessory Motor On Normal/Default Direction
10 - Accessory Motor On Reverse Direction
11 - Don't Care/Take no action";
CM_ BO_ 2558066430 "Electrified Accessory Power Electronics Coolant Fan 1 Command - The command message to the electrified accessory: Power Electronics Coolant Fan 1.  See PGN 64508 for the corresponding status message.";
CM_ SG_ 2558066430 PECF1PS_8006 "Speed command to the Power Electronics Coolant Fan 1 in percentage of maximum speed.";
CM_ SG_ 2558066430 PECF1SC_8005 "Speed command to the Power Electronics Coolant Fan 1.";
CM_ SG_ 2558066430 PECF1PH_8004 "Command to allow the Power Electronics Coolant Fan 1 to remain alive independently of the electrical enable input to the Accessory Motor.
00 - Power Hold Disabled
01 - Power Hold Enabled
10 - Reserved
11 - Don't Care/Take no action";
CM_ SG_ 2558066430 PECF1EC_8003 "Enable and direction command to the Power Electonics Coolant Fan 1.

00 - Accessory Motor Off
01 - Accessory Motor On Normal/Default Direction
10 - Accessory Motor On Reverse Direction
11 - Don't Care/Take no action";
CM_ BO_ 2558000894 "Electrified Accessory Power Electronics Coolant Fan 2 Command - The command message to the electrified accessory: Power Electronics Coolant Fan 2.  See PGN 64507 for the corresponding status message.";
CM_ SG_ 2558000894 PECF2PS_8018 "Speed command to the Power Electronics Coolant Fan 2 in percentage of maximum speed.";
CM_ SG_ 2558000894 PECF2SC_8017 "Speed command to the Power Electronics Coolant Fan 2.";
CM_ SG_ 2558000894 PECF2PH_8016 "Command to allow the Power Electronics Coolant Fan 2 to remain alive independently of the electrical enable input to the Accessory Motor.  
00 - Power Hold Disabled
01 - Power Hold Enabled
10 - Reserved
11 - Don't Care/Take no action";
CM_ SG_ 2558000894 PECF2EC_8015 "Enable and direction command to the Power Electonics Coolant Fan 2.

00 - Accessory Motor Off
01 - Accessory Motor On Normal/Default Direction
10 - Accessory Motor On Reverse Direction
11 - Don't Care/Take no action";
CM_ BO_ 2557935358 "Electrified Accessory Power Electronics Coolant Fan 3 Command - The command message to the electrified accessory: Power Electronics Coolant Fan 3.  See PGN 64506 for the corresponding status message.";
CM_ SG_ 2557935358 PECF3PS_8030 "Speed command to the Power Electronics Coolant Fan 3 in percentage of maximum speed.";
CM_ SG_ 2557935358 PECF3SC_8029 "Speed command to the Power Electronics Coolant Fan 3.";
CM_ SG_ 2557935358 PECF3PH_8028 "Command to allow the Power Electronics Coolant Fan 3 to remain alive independently of the electrical enable input to the Accessory Motor.  
00 - Power Hold Disabled
01 - Power Hold Enabled
10 - Reserved
11 - Don't Care/Take no action";
CM_ SG_ 2557935358 PECF3EC_8027 "Enable and direction command to the Power Electonics Coolant Fan 3.

00 - Accessory Motor Off
01 - Accessory Motor On Normal/Default Direction
10 - Accessory Motor On Reverse Direction
11 - Don't Care/Take no action";
CM_ BO_ 2557869822 "Electrified Accessory Propulsion Motor Coolant Fan 1 Command - The command message to the electrified accessory: Propulsion Motor Coolant Fan 1.  See PGN 64505 for the corresponding status message.";
CM_ SG_ 2557869822 PMCF1PS_8042 "Speed command to the Propulsion Motor Coolant Fan 1 in percentage of maximum speed.";
CM_ SG_ 2557869822 PMCF1SC_8041 "Speed command to the Propulsion Motor Coolant Fan 1.";
CM_ SG_ 2557869822 PMCF1PH_8040 "Command to allow the Propulsion Motor Coolant Fan 1 to remain alive independently of the electrical enable input to the Accessory Motor. 
00 - Power Hold Disabled
01 - Power Hold Enabled
10 - Reserved
11 - Don't Care/Take no action";
CM_ SG_ 2557869822 PMCF1EC_8039 "Enable and direction command to the Propulsion Motor Coolant Fan 1.

00 - Accessory Motor Off
01 - Accessory Motor On Normal/Default Direction
10 - Accessory Motor On Reverse Direction
11 - Don't Care/Take no action";
CM_ BO_ 2557804286 "Electrified Accessory Propulsion Motor Coolant Fan 2 Command - The command message to the electrified accessory: Propulsion Motor Coolant Fan 2.  See PGN 64504 for the corresponding status message.";
CM_ SG_ 2557804286 PMCF2PS_8054 "Speed command to the Propulsion Motor Coolant Fan 2 in percentage of maximum speed.";
CM_ SG_ 2557804286 PMCF2SC_8053 "Speed command to the Propulsion Motor Coolant Fan 2.";
CM_ SG_ 2557804286 PMCF2PH_8052 "Command to allow the Propulsion Motor Coolant Fan 2 to remain alive independently of the electrical enable input to the Accessory Motor. 
00 - Power Hold Disabled
01 - Power Hold Enabled
10 - Reserved
11 - Don't Care/Take no action";
CM_ SG_ 2557804286 PMCF2EC_8051 "Enable and direction command to the Power Motor Coolant Fan 2.

00 - Accessory Motor Off
01 - Accessory Motor On Normal/Default Direction
10 - Accessory Motor On Reverse Direction
11 - Don't Care/Take no action";
CM_ BO_ 2557738750 "Electrified Accessory Propulsion Motor Coolant Fan 3 Command - The command message to the electrified accessory: Propulsion Motor Coolant Fan 3.  See PGN 64503 for the corresponding status message.";
CM_ SG_ 2557738750 PMCF3PS_8066 "Speed command to the Propulsion Motor Coolant Fan 3 in percentage of maximum speed.";
CM_ SG_ 2557738750 PMCF3SC_8065 "Speed command to the Propulsion Motor Coolant Fan 3.";
CM_ SG_ 2557738750 PMCF3PH_8064 "Command to allow the Propulsion Motor Coolant Fan 3 to remain alive independently of the electrical enable input to the Accessory Motor.  
00 - Power Hold Disabled
01 - Power Hold Enabled
10 - Reserved
11 - Don't Care/Take no action";
CM_ SG_ 2557738750 PMCF3EC_8063 "Enable and direction command to the Power Motor Coolant Fan 3.

00 - Accessory Motor Off
01 - Accessory Motor On Normal/Default Direction
10 - Accessory Motor On Reverse Direction
11 - Don't Care/Take no action";
CM_ SG_ 2557673214 ODMFB5CC_8203 "New starting value for total count of particles detected in Ferrous bin 6.";
CM_ SG_ 2557673214 ODMFB5CC_8202 "New starting value for total count of particles detected in Ferrous bin 5.";
CM_ SG_ 2557673214 ODMFB5CC_8201 "New starting value for total count of particles detected in Ferrous bin 4.";
CM_ SG_ 2557673214 ODMFB5CC_8200 "New starting value for total count of particles detected in Ferrous bin 3.";
CM_ SG_ 2557673214 ODMFB5CC_8199 "New starting value for total count of particles detected in Ferrous bin 2.";
CM_ SG_ 2557673214 ODMFB7CC_8198 "New starting value for total count of particles detected in Non-Ferrous bin 1.";
CM_ SG_ 2557673214 ODMFB6CC_8197 "New starting value for total count of particles detected in Ferrous bin 6.";
CM_ SG_ 2557673214 ODMFB5CC_8196 "New starting value for total count of particles detected in Ferrous bin 5.";
CM_ SG_ 2557673214 ODMFB4CC_8195 "New starting value for total count of particles detected in Ferrous bin 3.";
CM_ SG_ 2557673214 ODMFB2CC_8193 "New starting value for total count of particles detected in Ferrous bin 2.";
CM_ SG_ 2557673214 ODMFB3CC_8194 "New starting value for total count of particles detected in Ferrous bin 4.";
CM_ SG_ 2557673214 ODMCIN_8191 "Identification number of the Oil Debris Monitoring (ODM) sensor being configured. Identification numbers are application specific.";
CM_ BO_ 2350644979 "High Voltage Energy Storage 1 Control 1 - Control commands to be sent to High Voltage Energy Storage pack (or system) 1.";
CM_ BO_ 2566658558 "Payload System Totals 1
Payload measurement system accumulators related to the haul cycle productivity.";
CM_ SG_ 2566658558 TotalHaulCycleCount "The total accumulated number of haul cycles over the life of the product.
This should be a monotonically increasing number that sums Haul Cycle Count (SPN 6847). If transactions are supported via Payload Delivery Transaction Status (SPN 7702) then ...";
CM_ SG_ 2566658558 TotalDeliveredPayloadWeight "The accumulated delivered payload mass over the life of the product.
This should be a monotonically increasing number that sums delivered payload weights (SPN 6849) If transactions are supported (Payload Delivery Transaction Status, SPN 7702) then ...";
CM_ BO_ 2566658302 "Payload System Totals 2
Payload measurement system accumulators.";
CM_ SG_ 2566658302 TotalPayloadTransactionCount "The accumulated number of completed payload delivery transactions over the life of the product.
If transaction status monitoring is supported via Payload Delivery Transaction Status (SPN 7702) then total payload transaction count may increment when ...";
CM_ BO_ 2499549182 "Payload Temperature 1
Payload temperatures";
CM_ BO_ 2499548926 "Payload Temperature 2
Payload temperatures";
CM_ BO_ 2499548670 "Vehicle Electrical Power 6
Voltage and current measurements for batteries 3 and 4.";
CM_ BO_ 2499548158 "Door Latch Status
This message provides status of the cabin door  latches. Doors are numbered left to right, front to back.";
CM_ SG_ 2499548158 RightRearCabDoorLatchPos "Status of the right rear cab door latch. Door latches may have 3 positions indicating fully open, 1st detent or \"ajar\", and 2nd detent or fully closed.
000 = Door Latch Open
001 = Door Latch Fully Closed/Latched
010 = Door Latch Ajar
011 = ...";
CM_ SG_ 2499548158 LeftRearCabDoorLatchPos "Status of the left rear cab door latch. Door latches may have 3 positions indicating fully open, 1st detent or \"ajar\", and 2nd detent or fully closed.
000 = Door Latch Open
001 = Door Latch Fully Closed/Latched
010 = Door Latch Ajar
011 = ...";
CM_ SG_ 2499548158 RightFrontCabDoorLatchPos "Status of the right front cab door latch (passenger door for left-hand steer vehicles). Door latches may have 3 positions indicating fully open, 1st detent or \"ajar\", and 2nd detent or fully closed.
000 = Door Latch Open
001 = Door Latch Fully ...";
CM_ SG_ 2499548158 LeftFrontCabDoorLatchPos "Status of the left front cab door latch (driver door for left-hand steer vehicles). Door latches may have 3 positions indicating fully open, 1st detent or \"ajar\", and 2nd detent or fully closed.
000 = Door Latch Open
001 = Door Latch Fully ...";
CM_ BO_ 2499547902 "Cab Door Control
This message requests or commands the cabin door functionality; door latches, windows, and mirrors. Doors are numbered left to right, front to back.";
CM_ SG_ 2499547902 MirrorRight2HeatCmd "Command to activate heater for second mirror on the right side (passenger side for left-hand steer vehicle).  Mirror heat may be expected to latch in the \"on\" state upon receipt of the command, stay on while the command is \"take no action\" and turn ...";
CM_ SG_ 2499547902 MirrorLeft2HeatCmd "Command to activate heater for second mirror on the left side (driver side for left-hand steer vehicle).  Mirror heat may be expected to latch in the \"on\" state upon receipt of the command, stay on while the command is \"take no action\" and turn off ...";
CM_ SG_ 2499547902 MirrorRight1HeatCmd "Command to activate heater for primary mirror on the right side (passenger side for left-hand steer vehicle).  Mirror heat may be expected to latch in the \"on\" state upon receipt of the command, stay on while the command is \"take no action\" and turn ...";
CM_ SG_ 2499547902 MirrorLeft1HeatCmd "Command to activate heater for primary mirror on the left side (driver side for left-hand steer vehicle).  Mirror heat may be expected to latch in the \"on\" state upon receipt of the command, stay on while the command is \"take no action\" and turn off ...";
CM_ SG_ 2499547902 MirrorRight2VerticalCmd "Commands vertical position change of the second mirror on the right side (passenger side for lefthand steer vehicles).

00 = Move up
01 = Move down
10 = Reserved
11 = Take no action";
CM_ SG_ 2499547902 MirrorRight2HorizontalCmd "Commands horizontal position change of the second mirror on the right side (passenger side for lefthand steer vehicles).

00 = Move left
01 = Move right
10 = Reserved
11 = Take no action";
CM_ SG_ 2499547902 MirrorLeft2VerticalCmd "Commands vertical position change of the second mirror on the left side (driver side for left-hand steer vehicles). 

00 = Move up
01 = Move down
10 = Reserved
11 = Take no action";
CM_ SG_ 2499547902 MirrorLeft2HorizontalCmd "Commands horizontal position change of the second mirror on the left side (driver side for left-hand steer vehicles).

00 = Move left
01 = Move right
10 = Reserved
11 = Take no action";
CM_ SG_ 2499547902 MirrorRight1VerticalCmd "Commands vertical position change of the primary mirror on the right side (passenger side for lefthand steer vehicles).

00 = Move up
01 = Move down
10 = Reserved
11 = Take no action";
CM_ SG_ 2499547902 MirrorRight1HorizontalCmd "Commands horizontal position change of the primary mirror on the right side (passenger side for lefthand steer vehicles).

00 = Move left
01 = Move right
10 = Reserved
11 = Take no action";
CM_ SG_ 2499547902 MirrorLeft1VerticalCmd "Commands vertical position change of the primary mirror on the left side (driver side for left-hand steer vehicles).

00 = Move up
01 = Move down
10 = Reserved
11 = Take no action";
CM_ SG_ 2499547902 MirrorLeft1HorizontalCmd "Commands horizontal position change of the primary mirror on the left side (driver side for left-hand steer vehicles).

00 = Move left
01 = Move right
10 = Reserved
11 = Take no action";
CM_ SG_ 2499547902 RightRearWindowPosCmd "Commands position change of the right rear window.

000 = Window move up
001 = Window move down
010 = Window auto up
011 = Window auto down
100 = Reserved
101 = Reserved
110 = Reserved
111 = Take no action";
CM_ SG_ 2499547902 LeftRearWindowPosCmd "Commands position change of left rear window.

000 = Window move up
001 = Window move down
010 = Window auto up
011 = Window auto down
100 = Reserved
101 = Reserved
110 = Reserved
111 = Take no action";
CM_ SG_ 2499547902 RightFrontWindowPosCmd "Commands position change of right front window (passenger door window on left-hand steer vehicles).
000 = Window move up
001 = Window move down
010 = Window auto up
011 = Window auto down
100 = Reserved
101 = Reserved
110 = Reserved
111 = ...";
CM_ SG_ 2499547902 LeftFrontWindowPosCmd "Commands position change of left front window (driver door window on left-hand steer vehicles).
000 = Window move up
001 = Window move down
010 = Window auto up
011 = Window auto down
100 = Reserved
101 = Reserved
110 = Reserved
111 = Take ...";
CM_ SG_ 2499547902 RemoteCabDoorLockReq "Request to the cab door lock controller from Remote Keyless Entry or or other external device to lock or unlock doors.
This parameter is different from Cab Doors Lock Actuation Command (SPN xxxx) because this is a request to actuate door locks ...";
CM_ SG_ 2499547902 DoorsLockActCmd "Commands cab door latch state change: lock or unlock.
000 = Unlock left front cab door latch (driver door on LH steer vehicles)
001 = Unlock right front cab door latch (front passenger door for LH steer vehicles)
010 = Unlock left rear cab door ...";
CM_ BO_ 2566656510 "Total Gaseous Fuel Information
Reports the total fuel information of systems using gaseous fuel.";
CM_ SG_ 2566656510 EngTotalGasIdleFuelVolumeUsed "Accumulated volume of engine gaseous fuel used during vehicle operation under idle conditions, in standard cubic meters.";
CM_ SG_ 2566656510 EngTotalGasFuelVolumeUsed "Accumulated volume of engine gaseous fuel used during vehicle operation, in standard cubic meters.

See SPN 1040 for alternate units.";
CM_ BO_ 2565929214 "Advanced Driver Assistance Systems Interface Specification 3
Refer to ADASIS for specific message and parameter definitions. See the ADASIS1  (PGN xxx) for more information.";
CM_ BO_ 2565928958 "Advanced Driver Assistance Systems Interface Specification 2
Refer to ADASIS for specific message and parameter  definitions. See ADASIS1 (PGN 61686) for more information.";
CM_ BO_ 2565928702 "Advanced Driver Assistance Systems Interface Specification 1
Advanced Driver Assistance Systems Interface Specification (ADASIS) defines parameters that describe the upcoming vehicle's environment, including the attributes about the current ...";
CM_ BO_ 2431710718 "Engine Start Arbitrator
Message from the engine start arbitrator, used to manage engine starts.
Default broadcast rate of 20 ms unless the arbitrator is transmitting Engine Start Control Message Rate (SPN 7752) indicating a switch to 250 ms or on ...";
CM_ SG_ 2431710718 Checksum "Checksum to allow detection of data integrity issues. The receiving node shall calculate the checksum and compare its calculated value with the received checksum. In case of a mismatch the message shall be discarded.
The message checksum is ...";
CM_ SG_ 2431710718 MessageCounter "Message counter to allow detection of data integrity issues. The counter is incremented every time a device sends out the Engine Start Control message. When the counter has reached a value of 15 it starts over at 0 for the next message cycle ...";
CM_ SG_ 2431710718 AutomaticEngStartConsentSummary "Arbitrator’s summary of the consent statuses of all devices which the arbitrator considers for automatic start requests. The purpose of this parameter is for requesters to determine if an automatic start request would be honored at the current time.
 ...";
CM_ SG_ 2431710718 OpEngStartConsentSummary "Arbitrator’s summary of the consent statuses of all devices which the arbitrator considers for operator start requests. The purpose of this parameter is for requesters to determine if an operator start request would be honored at the current time.
 ...";
CM_ SG_ 2431710718 ReqLatchStatus "Indicates the arbitrator’s latch status for engine start requests. All “unlatched” states shall transition to state “0 - Start Request not received” after 1000 ms unless a different state becomes more appropriate in the meantime. While this time may ...";
CM_ SG_ 2431710718 StarterCmd "Command from the arbitrator to the engine starter controller(s).
The arbitrator takes input from consenters and requesters to initiate an engine start. This signal is used by the arbitrator to command the first or second starter instance.
Starter ...";
CM_ SG_ 2431710718 CtrlMessageRate "This signal is sent by the arbitrator to control the rate at which other participants send the Engine Start Control Message (ENGSC). The arbitrator sets this signal to the slower rate after the first engine start attempt after initial power-up is ...";
CM_ BO_ 2431708670 "Engine Start Control
Message used to manage engine starts.
Default broadcast rate of 20 ms unless the sending  device has received Engine Start Control Message Rate (SPN 7752j) from the engine start arbitrator indicating a  switch to 250 ms or on ...";
CM_ SG_ 2431708670 Checksum "Checksum to allow detection of data integrity issues. The receiving node shall calculate the checksum and compare its calculated value with the received checksum. In case of a mismatch the message shall be discarded.
The message checksum is ...";
CM_ SG_ 2431708670 MessageCounter "Message counter to allow detection of data integrity issues. The counter is incremented every time a device sends out the Engine Start Control message. When the counter has reached a value of 15 it starts over at 0 for the next message cycle ...";
CM_ SG_ 2431708670 Starter2Feedback "Feedback of the current state of second engine starter. This signal is intended to be used by the arbitrator as feedback to its command signal (SPN 7753).
Additional details regarding the starter state may be available in SPN 1675.
000 = Starter ...";
CM_ SG_ 2431708670 Starter1Feedback "Feedback of the current state of first engine starter. This signal is intended to be used by the arbitrator as feedback to its command signal (SPN 7753).
Additional details regarding the starter state may be available in SPN 1675.
000 = Starter ...";
CM_ SG_ 2431708670 AbortReq "Indicates the sender’s desire to abort an engine start. This signal is used by requesters and consenters to request that the arbitrator cancel an engine start that is in progress.
The sender of this signal may increase the broadcast rate ...";
CM_ SG_ 2431708670 Consent "Indicates the sender’s consent to start the engine for different start types. An operator-requested engine start is a start that is initiated directly by the operator (i.e. via the key switch). An automatic engine start is one that is initiated by a ...";
CM_ SG_ 2431708670 Req "Indicates the sender’s desire to start the engine. The engine start arbitrator latches this signal and, if possible, completes the engine start regardless of a change of state of this signal. Use Engine Start Abort Request (SPN 7747) to un-latch the ...";
CM_ BO_ 2566661118 "Fuel Consumption (Liquid) 2
Engine fuel consumption accumulators.";
CM_ SG_ 2566661118 EngTotalDieselFuelDemand "Accumulated amount of liquid fuel that would have been used during engine operation, including actual diesel fuel used and the diesel fuel that was displaced by gaseous fuel.

This is the cumulative value of SPN 7596.";
CM_ BO_ 2633769726 "Electronic Engine Controller 19
Engine related parameters";
CM_ SG_ 2633769726 TotalEngEnergy "The total amount of energy delivered by the engine. It is accumulated over the life of the engine.";
CM_ BO_ 2565926142 "Aftertreatment 2 Outlet Sensor 2
The purpose of this PGN is to group the aftertreatment outlet sensor data for bank 2.  These values include the NOx, %O2, status of the sensors with respect to the power being supplied and the heating element, ...";
CM_ SG_ 2565926142 O2Snsr2PreliminaryFMI "Used to identify the applicable J1939-73 FMI detected in the aftertreatment outlet oxygen second sensor by the manufacturer’s sensor control software in exhaust bank 2.  When there is no failure FMI 31 is sent.  In the case of multiple failures the ...";
CM_ SG_ 2565926142 NOxSnsr2SelfDiagStatus "Self-diagnosis result status for second NOx sensor ATO2 (Aftertreatment Outlet Bank 2)
000 Diagnosis not active
001 NOx Sensor ATO2 Self Diagnosis active flag
010 NOx Sensor ATO2 Self Diagnosis Result Complete
011 NOx Sensor ATO2 Self Diagnosis ...";
CM_ SG_ 2565926142 NOxSnsr2PreliminaryFMI "Used to identify the applicable J1939-73 FMI detected in the aftertreatment outlet NOx second sensor by the manufacturer’s sensor control software in exhaust bank 2.  When there is no failure FMI 31 is sent.  In the case of multiple failures the ...";
CM_ SG_ 2565926142 GasSnsr2HtrCtrl "Indicates the heater status in the warm-up process.  Upon receiving a power-up command, the gas second sensor ramps up according to a manufacturer defined profile.  The Preheat 1, Preheat 2, and Automatic messages are regions within this profile in ...";
CM_ SG_ 2565926142 GasSnsr2HtrPreliminaryFMI "Used to identify the applicable J1939-73 FMI detected in the heater of the outlet exhaust gas second sensor, either NOx or O2, by the manufacturer’s sensor control software in exhaust bank 2.  When there is no failure FMI 31 is sent.  In the case of ...";
CM_ SG_ 2565926142 WRPercentO22ReadingStable "Indicates that the percent oxygen reading of the aftertreatment outlet gas second sensor, either NOx or O2, is stable as determined by the manufacturer's control software in exhaust bank 2.
For a single exhaust bank system, refer to parameters in ...";
CM_ SG_ 2565926142 NOx2ReadingStable "Indicates that the NOx reading of the aftertreatment outlet NOx second sensor is stable as determined by the manufacturer’s control software in exhaust bank 2.
For a single exhaust bank system, refer to parameters in PGNs 61454, 61455, 64946, ...";
CM_ SG_ 2565926142 GasSnsr2AtTemp "Indicates that the heater element of the aftertreatment outlet gas second sensor, either NOx or O2, is within the manufacturer’s specified range for accurate measurements in exhaust bank 2.
For a single exhaust bank system, refer to parameters in ...";
CM_ SG_ 2565926142 GasSnsr2PwrInRange "Indicates that the power supplied to the aftertreatment outlet gas second sensor, either NOx or O2, is within the manufacturer’s specification in exhaust bank 2.
For a single exhaust bank system, refer to parameters in PGNs 61454, 61455, 64946, ...";
CM_ SG_ 2565926142 PercentO22 "The actual oxidation factor (percent oxygen) of the gas within the exhaust stream.  For positive values, the parameter represents the percent oxygen in excess of the amount required for stoichiometric combustion.  For negative values, the parameter ...";
CM_ SG_ 2565926142 NOx2 "The amount of combined NO and NO2 in the exhaust entering the aftertreatment system measured by the second NOx sensor at the aftertreatment outlet, represented in NOx molecule parts per million non-NOx molecules in exhaust bank 2.
For a single ...";
CM_ BO_ 2565925886 "Aftertreatment 2 Intake Sensor 2
The purpose of this PGN is to group the aftertreatment intake sensor data for bank 2.  These values include the NOx, %O2, status of the sensors with respect to the power being supplied and the heating element, ...";
CM_ SG_ 2565925886 O2Snsr2PreliminaryFMI "Used to identify the applicable J1939-73 FMI detected in the aftertreatment intake oxygen second sensor by the manufacturer’s sensor control software in exhaust bank 2.  When there is no failure FMI 31 is sent.  In the case of multiple failures the ...";
CM_ SG_ 2565925886 NOxSnsr2SelfDiagStatus "Self-diagnosis result status for NOx second sensor ATI2 (Aftertreatment Intake Bank 2)
000 Diagnosis not active
001 NOx Sensor ATI2 Self Diagnosis active flag
010 NOx Sensor ATI2 Self Diagnosis Result Complete
011 NOx Sensor ATI2 Self Diagnosis ...";
CM_ SG_ 2565925886 SCRInNOxSnsr2PreliminaryFMI "Used to identify the applicable J1939-73 FMI detected in the aftertreatment intake NOx second sensor by the manufacturer’s sensor control software in exhaust bank 2.  When there is no failure FMI 31 is sent.  In the case of multiple failures the ...";
CM_ SG_ 2565925886 GasSnsr2HtrCtrl "Indicates the heater status in the warm-up process.  Upon receiving a power-up command, the second gas sensor ramps up according to a manufacturer defined profile.  The Preheat 1, Preheat 2, and Automatic messages are regions within this profile in ...";
CM_ SG_ 2565925886 GasSnsr2HtrPreliminaryFMI "Used to identify the applicable J1939-73 FMI detected in the heater of the intake exhaust gas second sensor, either NOx or O2, by the manufacturer’s sensor control software in exhaust bank 2.  When there is no failure FMI 31 is sent.  In the case of ...";
CM_ SG_ 2565925886 WRPercentO22ReadingStable "Indicates that the percent oxygen reading of the aftertreatment intake gas second sensor, either NOx or O2, is stable as determined by the manufacturer's control software in exhaust bank 2.
For a single exhaust bank system, refer to parameters in ...";
CM_ SG_ 2565925886 SCRInNOx2ReadingStable "Indicates that the NOx reading of the aftertreatment intake NOx second sensor is stable as determined by the manufacturer’s control software in exhaust bank 2.
For a single exhaust bank system, refer to parameters in PGNs 61454, 61455, 64946, ...";
CM_ SG_ 2565925886 GasSnsr2AtTemp "Indicates that the heater element of the aftertreatment intake gas second sensor, either NOx or O2, is within the manufacturer’s specified range for accurate measurements in exhaust bank 2.
For a single exhaust bank system, refer to parameters in ...";
CM_ SG_ 2565925886 GasSnsr2PwrInRange "Indicates that the power supplied to the aftertreatment intake gas second sensor, either NOx or O2, is within the manufacturer’s specification in exhaust bank 2.
For a single exhaust bank system, refer to parameters in PGNs 61454, 61455, 64946, ...";
CM_ SG_ 2565925886 PercentO22 "The actual oxidation factor (percent oxygen) of the gas within the exhaust stream.  For positive values, the parameter represents the percent oxygen in excess of the amount required for stoichiometric combustion.  For negative values, the parameter ...";
CM_ SG_ 2565925886 SCRInNOx2 "The amount of combined NO and NO2 in the exhaust entering the aftertreatment system measured by the second NOx sensor at the aftertreatment intake, represented in NOx molecule parts per million non-NOx molecules in exhaust bank 2.
For a single ...";
CM_ BO_ 2565925630 "Aftertreatment 1 Outlet Gas 3
The purpose of this PGN is to group the aftertreatment outlet sensor data for bank 1.  These values include the NOx, %O2, Status of the sensors with respect to the power being supplied and the heating element, errors ...";
CM_ SG_ 2565925630 O2Snsr2PreliminaryFMI "Used to identify the applicable J1939-73 FMI detected in the aftertreatment outlet oxygen second sensor by the manufacturer’s sensor control software in exhaust bank 1.  When there is no failure FMI 31 is sent.  In the case of multiple failures the ...";
CM_ SG_ 2565925630 NOxSnsr2SelfDiagStatus "Self-diagnosis result status for NOx second sensor ATO1 (Aftertreatment Outlet Bank 1)
000 Diagnosis not active
001 NOx Sensor ATO1 Self Diagnosis active flag
010 NOx Sensor ATO1 Self Diagnosis Result Complete
011 NOx Sensor ATO1 Self Diagnosis ...";
CM_ SG_ 2565925630 NOxSnsr2PreliminaryFMI "Used to identify the applicable J1939-73 FMI detected in the aftertreatment outlet NOx second sensor by the manufacturer’s sensor control software in exhaust bank 1.  When there is no failure FMI 31 is sent.  In the case of multiple failures the ...";
CM_ SG_ 2565925630 Snsr2HtrCtrl "Indicates the heater status in the warm-up process.  Upon receiving a power-up command, the gas second sensor ramps up according to a manufacturer defined profile.  The Preheat 1, Preheat 2, and Automatic messages are regions within this profile in ...";
CM_ SG_ 2565925630 Snsr2HtrPreliminaryFMI "Used to identify the applicable J1939-73 FMI detected in the heater of the outlet exhaust gas second sensor, either NOx or O2, by the manufacturer’s sensor control software in exhaust bank 1.  When there is no failure FMI 31 is sent.  In the case of ...";
CM_ SG_ 2565925630 WRPercentO22ReadingStable "Indicates that the percent oxygen reading of the aftertreatment outlet gas second sensor, either NOx or O2, is stable as determined by the manufacturer's control software in exhaust bank 1.
00 - Not stable
01 - Stable
10 - Error
11 - Not ...";
CM_ SG_ 2565925630 NOx2ReadingStable "Indicates that the NOx reading of the aftertreatment outlet NOx second sensor is stable as determined by the manufacturer’s control software in exhaust bank 1.

00 - Not stable
01 - Stable
10 - Error
11 - Not available";
CM_ SG_ 2565925630 Snsr2AtTemp "Indicates that the heater element of the aftertreatment outlet gas second sensor, either NOx or O2, is within the manufacturer’s specified range for accurate measurements in exhaust bank 1.
00 - Not in range
01 - In range
10 - Error
11 - Not ...";
CM_ SG_ 2565925630 Snsr2PwrInRange "Indicates that the second measurement of power supplied to the aftertreatment outlet gas sensor, either NOx or O2, is within the manufacturer’s specification in exhaust bank 1. This parameter reports the status as reported by the sensor.
00 - Not ...";
CM_ SG_ 2565925630 PercentO22 "The second measurement of the actual oxidation factor (percent oxygen) of the gas within the exhaust stream.  For positive values, the parameter represents the percent oxygen in excess of the amount required for stoichiometric combustion.  For ...";
CM_ SG_ 2565925630 NOx2 "The second measurement of the amount of combined NO and NO2 in the exhaust exiting the aftertreatment system measured by a NOx sensor at the aftertreatment outlet, represented in NOx molecule parts per million non-NOx molecules in exhaust bank 1.";
CM_ BO_ 2565925374 "Aftertreatment 1 Intake Gas 3
The purpose of this PGN is to group the aftertreatment intake sensor data for bank 1.  These values include the NOx, %O2, Status of the sensors with respect to the power being supplied and the heating element, errors ...";
CM_ SG_ 2565925374 O2Snsr2PreliminaryFMI "Used to identify the second applicable J1939-73 FMI detected in the aftertreatment intake oxygen sensor by the manufacturer’s sensor control software in exhaust bank 1.  When there is no failure FMI 31 is sent.  In the case of multiple failures the ...";
CM_ SG_ 2565925374 NOxSnsr2SelfDiagStatus "Self-diagnosis result status for the second NOx sensor ATI1 (Aftertreatment Intake Bank 1)
000 Diagnosis not active
001 NOx Sensor ATI1 Self Diagnosis active flag
010 NOx Sensor ATI1 Self Diagnosis Result Complete
011 NOx Sensor ATI1 Self ...";
CM_ SG_ 2565925374 SCRInNOxSnsr2PreliminaryFMI "Used to identify the applicable J1939-73 FMI detected in the aftertreatment intake NOx second sensor by the manufacturer’s sensor control software in exhaust bank 1.  When there is no failure FMI 31 is sent.  In the case of multiple failures the ...";
CM_ SG_ 2565925374 Snsr2HtrCtrl "Indicates the heater status in the warm-up process.  Upon receiving a power-up command, the second gas sensor ramps up according to a manufacturer defined profile.  The Preheat 1, Preheat 2, and Automatic messages are regions within this profile in ...";
CM_ SG_ 2565925374 Snsr2HtrPreliminaryFMI "Used to identify the second applicable J1939-73 FMI detected in the heater of the intake exhaust gas sensor, either NOx or O2, by the manufacturer’s sensor control software in exhaust bank 1.  When there is no failure FMI 31 is sent.  In the case of ...";
CM_ SG_ 2565925374 WRPercentO22ReadingStable "Indicates that the second measurement of the percent oxygen reading of the aftertreatment intake gas sensor, either NOx or O2, is stable as determined by the manufacturer's control software in exhaust bank 1.
00 - Not stable
01 - Stable
10 - ...";
CM_ SG_ 2565925374 SCRInNOx2ReadingStable "Indicates that the NOx reading of the aftertreatment intake NOx second sensor is stable as determined by the manufacturer’s control software in exhaust bank 1.

00 - Not stable
01 - Stable
10 - Error
11 - Not available";
CM_ SG_ 2565925374 Snsr2AtTemp "Indicates that the heater element of the aftertreatment intake gas second sensor, either NOx or O2, is within the manufacturer’s specified range for accurate measurements in exhaust bank 1.
00 - Not in range
01 - In range
10 - Error
11 - Not ...";
CM_ SG_ 2565925374 Snsr2PwrInRange "Indicates that the second measurement of power supplied to the aftertreatment intake gas sensor, either NOx or O2, is within the manufacturer’s specification in exhaust bank 1.  This parameter reports the status as reported by the sensor.
00 - Not ...";
CM_ SG_ 2565925374 PercentO22 "The second measurement of the actual oxidation factor (Percent Oxygen) of the gas within the exhaust stream. For positive values, the parameter represents the percent oxygen in excess of the amount required for stoichiometric combustion. For ...";
CM_ SG_ 2565925374 SCRInNOx2 "The second measurement of the amount of combined NO and NO2 in the exhaust entering the aftertreatment system measured by a NOx sensor at the aftertreatment intake, represented in NOx molecule parts per million non-NOx molecules in exhaust bank 1 ...";
CM_ BO_ 2364598526 "Engine Throttle / Fuel Actuator Control Command 2
Used to control networked electronic throttle control actuator and/or fuel control actuator valves.
Otherwise, this PGN can be used to monitor commanded % positioning to electronic throttle control ...";
CM_ SG_ 2364598526 FuelAct4CtrlCmd "The control command to fuel actuator 4, normalized to percent, where 0% represents fully closed and 100% represents fully open.  Typically, this fuel actuator is used to regulate low pressure natural gas flow rate, mixing into the air flow, which ...";
CM_ SG_ 2364598526 FuelAct3CtrlCmd "The control command to fuel actuator 3, normalized to percent, where 0% represents fully closed and 100% represents fully open.  Typically, this fuel actuator is used to regulate low pressure natural gas flow rate, mixing into the air flow, which ...";
CM_ BO_ 2558525182 "Tire Sensor Identification Command - The tire sensor identification number command for each monitored tire.
The command will be used to program sensor identification numbers for individual tire. Since there are multiple tire sensors to report, the ...";
CM_ SG_ 2558525182 Num7586 "The identification number of tire sensor for the tire specified in the tire sensor tire number (SPN 7584) or tire sensor location (SPN 7585).";
CM_ SG_ 2558525182 Location_7585 "The location of monitored tire that corresponds with the tire sensor identification number SPN 7586. In order to specify the monitored tire by tire number, use the tire number SPN 7584.
The high order 4 bits indicate the vehicle axle position of ...";
CM_ SG_ 2558525182 Num_7584 "The number of the monitored tire that corresponds with the tire sensor identification number SPN 7586. In order to specify the monitored tire by location, use the tire location SPN 7585.

The value 0xFF indicates this SPN is not used.";
CM_ SG_ 2558525182 NumOfTireSensors_7583 "Total count of monitored tire sensor identification numbers represented in this instance of the parameter group.";
CM_ BO_ 2350841598 "Alternator Control
Parameters to control the alternator.";
CM_ SG_ 2350841598 TrqRampMaxSpdCmd "The Alternator Torque Ramp Time Command (SPN 7591) is applied if the alternator speed is less than Alternator Torque Ramp Maximum Speed Command (SPN 7592). If the alternator speed is greater than Alternator Torque Ramp Maximum Speed Command, then ...";
CM_ SG_ 2350841598 TrqRampTimeCmd "Sets the torque ramp rate in which the alternator can respond to a change in electrical load. 100% represents the reference engine torque (SPN 544).
This value will be applied if the alternator speed is less than Alternator Torque Ramp Maximum ...";
CM_ SG_ 2350841598 ExcitationMaxCurrentLmt "Command sent to alternator to set the maximum excitation current of the alternator.";
CM_ SG_ 2350841598 SetpointVoltageCmd "Setpoint voltage command to alternator. The setpoint voltage is the point that is regulated by the alternator. This may or may not be the output of the alternator.";
CM_ BO_ 2566838014 "Hybrid System Inputs 1
This message can be sent by any controller that has hybrid system related information.";
CM_ SG_ 2566838014 ShutdownSw "When the operator enables this switch, all hybrid system functionality is disabled including propulsion, regenerative braking, and hybrid powered accessories.  For electric hybrids, the hybrid system shall be placed in an electrically off state ...";
CM_ SG_ 2566838014 PropulsionDisableSw "When the operator enables this switch, the propulsion aspect of hybrid system operation will be disabled.  However, hybrid powered accessories may be on and the engine may still run.  Regenerative braking is allowed unless disabled by SPN 7552 ...";
CM_ SG_ 2566838014 HybrdSystmCstngRgnrtvBrkngLvlSlc "Indicates the coasting regenerative braking level selector position.  Coasting regenerative braking occurs when neither the accelerator nor the brake pedal are depressed.
The coasting regenerative braking level is the position of the driver’s ...";
CM_ SG_ 2566838014 HybrdSystmBrkPdlRgnrtvBrkngDsblS "Indicates the brake pedal regenerative braking disable switch position.  This switch allows the operator to disable regenerative braking (e.g. such as during slippery road conditions) that is controlled by brake pedal application.   Regenerative ...";
CM_ SG_ 2566838014 HybrdSystmRgnrtvBrkngDsbleSwitch "Indicates the regenerative braking disable switch position.  This switch gives the operator the ability to disable all regenerative braking from all inputs (e.g. such as during slippery road conditions).
00 = Regenerative Braking Disable Switch is ...";
CM_ SG_ 2566838014 HybrdSystmOffBrdChrgrCnnctnSttus "Indicates the off-board plug-in charger connection status.  One of the uses of this signal is to protect against vehicle motion while a charger is plugged in.
00 = Off-board charger is not connected
01 = Off-board charger is connected
10 = Error
 ...";
CM_ SG_ 2566838014 HybrdSystmPwrElctrncsClntLvlSwtc "Indicates the coolant level switch position in the hybrid system power electronics (e.g. Inverters, DC/DC converters) cooling system.

00 = Coolant Level is not sufficient
01 = Coolant Level is sufficient
10 = Error
11 = Not Available";
CM_ SG_ 2566838014 HybrdSystmPrplsnClantLevelSwitch "Indicates the coolant level switch position in the hybrid system propulsion (e.g. electric motor, generator) cooling system.

00 = Coolant Level is not sufficient
01 = Coolant Level is sufficient
10 = Error
11 = Not Available";
CM_ SG_ 2566838014 HybrdSystmPrtctionOverrideSwitch "Indicates the Protection Override switch position.  This switch allows the operator to override hybrid system protection features and failure modes allowing hybrid system to continue to operate if possible.
00 = Not Active
01 = Active
10 = Error
 ...";
CM_ BO_ 2566761726 "Engine Fuel Information
Configuration information for engine fuel system.";
CM_ SG_ 2566761726 EngIdleFuelFlowRateThreshold "A configuration value that indicates the maximum flow rate for engine idle operation.";
CM_ SG_ 2566761726 NmbrOfFlCnsmptnMntrngTransducers "The number of fuel consumption monitoring transducers installed in the fuel consumption monitoring system.";
CM_ BO_ 2566756350 "Fuel Information 3 (Liquid)
Message for reporting information associated with liquid fuel.";
CM_ SG_ 2566756350 EngFuelReturnTemp "The temperature of the fuel flowing through a fuel return line from the engine back to the fuel tank.";
CM_ SG_ 2566756350 EngFuelSupplyTemp "The temperature of the fuel flowing through a fuel supply line from the fuel tank to the engine.";
CM_ BO_ 2566756094 "Fuel Information 2 (Liquid)
Message for reporting information associated with liquid fuel.";
CM_ SG_ 2566756094 EngFuelReturnFlowRate "The rate of fuel flowing through a fuel return line carrying fuel from the engine back to fuel tank.";
CM_ SG_ 2566756094 EngFuelSupplyFlowRate "The rate of fuel flowing through a fuel supply line carrying fuel from the fuel tank to the engine.";
CM_ BO_ 2566687998 "Aftertreatment 1 Particulate Sensor Information 1
This message contains information for the particulate sensor in bank 1 of a 2 bank system or the particulate sensor in a single bank system.

This sensor is downstream of the DPF.";
CM_ SG_ 2566687998 TimeBetweenRegens "This is the time between the last two successful regenerations of the particulate sensor for the current power cycle. This parameter reflects the time when the engine was running, not a duration based on a real time clock. If two successful ...";
CM_ SG_ 2566687998 ActiveAccumulationTime "This is the amount of time since the last successful regeneration completed.  The sensor has been accumulating particulate matter since that time.";
CM_ SG_ 2566687998 RegenSt "Indicates if the particulate sensor regeneration is currently active, and if so, the reason for the regeneration.
0000 - Regeneration is not active
0001 - Regneration is active and has been initiated by request via SPN 6783
0010 - Regeneration is ...";
CM_ SG_ 2566687998 RegenStatus "The status of the most recent attempt of this power cycle to activate the particulate sensor regeneration process. This will not be updated until the regeneration is no longer active, as indicated by SPN 6774.
Power cycle refers to the time that ...";
CM_ SG_ 2566687998 HtrSt "The states of the particulate sensor heater.  The heater will change states from 11 to 10, 10 to 01, and 01 to 00 in a typical heating event.
00 - Heater is in closed loop control
01 - Heater is being held at a specified level
10 - Heater is in ...";
CM_ SG_ 2566687998 Res "This sensor is located in the exhaust stream somewhere after the DPF, but not necessarily immediately after the DPF.  It provides a resistance value that can be used to determine particulate matter in the exhaust stream. The value in this parameter ...";
CM_ BO_ 2566687742 "Aftertreatment 1 Particulate Sensor Information 2
This message contains information for the particulate sensor in bank 1 of a 2 bank system or the particulate sensor in a single bank system.

This sensor is downstream of the DPF.";
CM_ SG_ 2566687742 HtrRes "The resistance of the particulate sensor heater.";
CM_ SG_ 2566687742 MaxRes "This is the maximum resistance that the particulate sensor can measure.";
CM_ SG_ 2566687742 Temp "Temperature of the particulate sensor.";
CM_ SG_ 2566687742 RegenFailedCount "This is the number of times that the particulate sensor regeneration process has been attempted but failed to complete this power cycle.";
CM_ SG_ 2566687742 PwrSupply "State signal which indicates when the Aftertreatment 1 particulate sensor has power applied to it. Note that this is referring to the power supplied to the sensor, not the power supplied to the controller connected to the sensor.
00 - Off
01 - On
 ...";
CM_ SG_ 2566687742 DetectionStatus "Detection status of the particulate sensor
0000 - Initialization for particulate matter detection
0001 - Waiting for dew point (see SPN 6784)
0010 - Particulate matter detection
0011 - Heater is active for particulate sensor regeneration
0100 - ...";
CM_ BO_ 2365348350 "Engine Load Sharing Information
This PGN contains information relating to integrated engine load sharing status values.";
CM_ SG_ 2365348350 EngLoadShareStatus "This signal indicates that the status of an engine load sharing feature.

0000 - Offline
0001 - Master
0010 - Slave
0011 - Loading
0100 - Unloading
0101 -1101 - Reserved
1110 - Error
1111 - Unavailable";
CM_ SG_ 2365348350 EngUnloadStatus "This signal indicates the status of an external request to unload the engine, such as the external unload request switch.

00 - Not Requested
01 - Requested
10 - Error
11 - Not Available";
CM_ BO_ 2566674686 "Turbocharger Information 7
Turbocharger Information";
CM_ SG_ 2566674686 EngTurbo4LubeOilPress "Gage pressure of oil in the lubrication system for the 4th turbocharger.";
CM_ SG_ 2566674686 EngTurbo3LubeOilPress "Gage pressure of oil in the lubrication system for the 3rd turbocharger.";
CM_ SG_ 2566674686 EngTurbo2LubeOilPress "Gage pressure of oil in the lubrication system for the 2nd turbocharger.";
CM_ BO_ 2566674430 "SCR Operator Inducement Information 1
Contains timers that indicate how long specific causes for inducement have been active.";
CM_ SG_ 2566674430 DslExhstFldQalityMalfunctionTime "Indicates the amount of time an error has been active due to detection of low Diesel Exhaust Fluid Quality. This will accumulate over the life of the product and will never be reset.";
CM_ SG_ 2566674430 DieselExhaustFluidTank1EmptyTime "Indicates the time the Diesel Exhaust Fluid Tank 1 Level is indicated as empty. This will accumulate over the life of the product and will never be reset.";
CM_ BO_ 2566674174 "SCR Operator Inducement Information 2
Contains parameters that are related to SCR inducement.";
CM_ SG_ 2566674174 SCROperatorInducementTotalTime "Indicates the time that operator inducement has been active. This will accumulate over the life of the product and will never be reset.";
CM_ SG_ 2566674174 AFTSCRMalfunctionTime "Indicates the amount of time an error condition has been active due to a malfunction in the Aftertreatment SCR system.
The source of the malfunction condition could be a component failure, detection of tampering, or other reason that prevents ...";
CM_ BO_ 2566673406 "Engine Gaseous Leakage Information
Used to transmit the gaseous fuel leakage information determined by the engine monitoring system.";
CM_ SG_ 2566673406 GasLeakageDetection3Press "Pressure measured in gas leakage detection point 3. Measured media is of the gas, meaning it could be air, inert gas, fuel air mixture or charge air mixture, depending on the failure mode detected. The third measurement point is in a separate leak ...";
CM_ SG_ 2566673406 GasLeakageDetection2Press "Pressure measured in gas leakage detection point 2. Measured media is of the gas, meaning it could be air, inert gas, fuel air mixture or charge air mixture, depending on the failure mode detected. The second measurement point is either another ...";
CM_ SG_ 2566673406 GasLeakageDetection1Press "Pressure measured in gas leakage detection point 1. Measured media is of the gas, meaning it could be air, inert gas, fuel air mixture or charge air mixture, depending on the failure mode detected. The measurement point is typically in the engine ...";
CM_ SG_ 2566673406 GasFuelLeakage3Concentration "Percentage of detected gaseous fuel leak compared to the lower explosion limit (LEL). 100% means the measured value is on the lower explosion limit. 0% means no detected gaseous fuel in measurement point. The third measurement point is in a separate ...";
CM_ SG_ 2566673406 GasFuelLeakage2Concentration "Percentage of detected gaseous fuel leak compared to the lower explosion limit (LEL). 100% means the measured value is on the lower explosion limit. 0% means no detected gaseous fuel in measurement point. The second  measurement point is either ...";
CM_ SG_ 2566673406 GasFuelLeakage1Concentration "Percentage of detected gaseous fuel leak compared to the lower explosion limit (LEL). 100% means the measured value is on the lower explosion limit. 0% means no detected gaseous fuel in measurement point. The measurement point is typically in the ...";
CM_ BO_ 2633782014 "Bin Weight and Lift Count
Used to transmit bin weights.

Note:  This PGN is transmitted for as many Bin Instances as exist on the vehicle.";
CM_ SG_ 2633782014 NetBinWeight "Mass of bin contents at most recent unload";
CM_ SG_ 2633782014 BinLiftCount "Increments with each lift, whether or not net bin weight changes.  The count rolls over at data range limit.

The count can be reset using SPN 6898 in PGN 56832.";
CM_ SG_ 2633782014 BinWeighingErrorStatus "Bin weighing error status

0 = No error
1 = Bad lift cycle
2 = Weighing error: bin lifted, not emptied
3 = Weighing error: empty bin lifted, emptied
4 - 14 = Reserved
15 = Not available / not applicable";
CM_ SG_ 2633782014 BinInstance "Gives the instance of the bin on the vehicle whose parameters are transmitted in the remainder of the PGN, with the first or only bin as instance 1.";
CM_ BO_ 2365346302 "Air Suspension Control 7
Used for suspension control information";
CM_ SG_ 2365346302 LiftAxle2Status "Indicates the status of a tag axle 2.  Numbering of lift/tag axles starts at front axle.  SPN 1822 may be used if less detail is acceptable.
000 - Down (tag axle is laden)
001 - Unloading (load is being transferred from the tag axle)
010 - ...";
CM_ SG_ 2365346302 LiftAxle1Status "Indicates the status of a tag axle 1.  Numbering of lift/tag axles starts at front axle.  SPN 1743 may be used if less detail is acceptable.
000 - Down (tag axle is laden)
001 - Unloading (load is being transferred from the tag axle)
010 - ...";
CM_ BO_ 2566672638 "Payload System Status
Status Information for Payload Measurement Systems.
 
This provides the last haul cycle payload information to the operator.";
CM_ SG_ 2566672638 DeliveryTransactionStatus "The current state of the payload delivery transaction.
When a transaction is in progress, a receiving node may monitor Haul Cycle Count (SPN 6847) and Delivered Payload Weight (SPN 6849) in order to track the progress of a transaction, where the ...";
CM_ SG_ 2566672638 DeliveredPayloadConfidence "The level of confidence of the delivered payload weight measurement. Higher confidence values indicate greater probability the delivered payload weight is the actual weight and providing feedback on the potential for improving system accuracy.";
CM_ SG_ 2566672638 DeliveredPayloadWeight "The delivered payload mass during the last haul cycle. This is the amount of material moved and delivered by a machine is a key work cycle parameter.
Delivered payload weight is defined as the last loaded weight less the carry back weight (material ...";
CM_ SG_ 2566672638 HaulModeStatus "The current operating state of the haul cycle.
0000 - Not in Haul Mode
0001 - Loading -- Payload is being added to the machine
0010 - Approaching Loaded -- Machine is near its maximum capacity
0011 - Loaded -- Loading operation has been ...";
CM_ SG_ 2566672638 HaulCycleCount "A counter incremented by 1 with each instance of a new haul cycle, defined as a dump to dump cycle. The counter shall increment from 0 to 64255, rolling over to 0 on the next increment after 64255.";
CM_ BO_ 2566672382 "Payload Weight Sensor Information
Staus Information on each Payload sensor in a payload measurement system";
CM_ SG_ 2566672382 PayloadWeightSensor8Status "Status of the payload system sensor 8 measurement.

00 = Sensor fully functional
01 = Sensor degraded
10 = Error (Sensor failed)
11 = Not available";
CM_ SG_ 2566672382 PayloadWeightSensor7Status "Status of the payload system sensor 7 measurement.

00 = Sensor fully functional
01 = Sensor degraded
10 = Error (Sensor failed)
11 = Not available";
CM_ SG_ 2566672382 PayloadWeightSensor6Status "Status of the payload system sensor 6 measurement.

00 = Sensor fully functional
01 = Sensor degraded
10 = Error (Sensor failed)
11 = Not available";
CM_ SG_ 2566672382 PayloadWeightSensor5Status "Status of the payload system sensor 5 measurement.

00 = Sensor fully functional
01 = Sensor degraded
10 = Error (Sensor failed)
11 = Not available";
CM_ SG_ 2566672382 PayloadWeightSensor4Status "Status of the payload system sensor 4 measurement.

00 = Sensor fully functional
01 = Sensor degraded
10 = Error (Sensor failed)
11 = Not available";
CM_ SG_ 2566672382 PayloadWeightSensor3Status "Status of the payload system sensor 3 measurement.

00 = Sensor fully functional
01 = Sensor degraded
10 = Error (Sensor failed)
11 = Not available";
CM_ SG_ 2566672382 PayloadWeightSensor2Status "Status of the payload system sensor 2 measurement.

00 = Sensor fully functional
01 = Sensor degraded
10 = Error (Sensor failed)
11 = Not available";
CM_ SG_ 2566672382 PayloadWeightSensor1Status "Status of the payload system sensor 1 measurement.

00 = Sensor fully functional
01 = Sensor degraded
10 = Error (Sensor failed)
11 = Not available";
CM_ BO_ 2566672126 "Aftertreatment 1 SCR Dosing System Information 3
This message contains additional  SCR dosing system information for aftertreatment system 1 (or bank 1).";
CM_ SG_ 2566672126 DEFDoser2Temp "The temperature (measured closest to dosing valve) of the second DEF dosing unit for aftertreatment system 1 (exhaust bank 1).";
CM_ SG_ 2566672126 DEFDoser2AbsPress "The SCR doser 2 diesel exhaust fluid absolute pressure (measured closest to dosing valve) for aftertreatment system 1 (exhaust bank 1).";
CM_ SG_ 2566672126 DEFDosingPress "The SCR dosing diesel exhaust fluid gage pressure (measured closest to dosing valve) for aftertreatment system 1 (exhaust bank 1). This is the gage equivalent to SPN 4334.";
CM_ BO_ 2566671870 "Aftertreatment 2 SCR Dosing System Information 3
This message contains additional  SCR dosing system information for aftertreatment system 2 (or bank 2).";
CM_ SG_ 2566671870 DEFDosing2Temp "The temperature (measured closest to dosing valve) of the second DEF dosing unit for aftertreatment system 2 (exhaust bank 2).";
CM_ SG_ 2566671870 DEFDoser2AbsPress "The SCR doser 2 diesel exhaust fluid absolute pressure (measured closest to dosing valve) for aftertreatment system 2 (exhaust bank 2).";
CM_ SG_ 2566671870 DEFDosingPress "The SCR dosing diesel exhaust fluid gage pressure (measured closest to dosing valve) for aftertreatment system 2 (exhaust bank 2). This is the gage equivalent to SPN 4387.";
CM_ BO_ 2566671614 "SCR Operator Inducement Information 3
Contains parameters related to overriding the operator inducement.";
CM_ SG_ 2566671614 TtlNmbrOfSCROprtrIndcmntOvrrdEvn "Indicates total number of operator inducement override events activated throughout the lifetime of engine operation.
This number will remain at the maximum value once it is reached.
See EU Commission directive 2012/46/EU. Appendix 1 Section 5.5 ...";
CM_ SG_ 2566671614 NmbrOfSCROprtrIndcmntOvrrdEvntsR "During an operator inducement event, the operator may be able to override the inducement multiple times. This parameter indicates the remaining number of times that the currently active inducement can be overridden during an operator inducement ...";
CM_ SG_ 2566671614 SCROprtrIndcmntOvrrdTmeRemaining "This parameter is used to indicate the time remaining during an operator inducement override event.  See also SPN 7344 for an alternate SLOT.
When an operator inducement is not active, this parameter indicates the maximum time that an operator ...";
CM_ SG_ 2566671614 SCROprtrInducementOverrideEnable "Indicates if an operator inducement derate is allowed to be overridden.

Note: Inducement override is only allowed under certain conditions approved by EPA/ARB.

00 Override not allowed
01 Override allowed
10 SAE Reserved
11 Not available";
CM_ BO_ 2566671358 "Electronic Engine Controller 17
This message includes some parameters that are used to support PEMS.
Manufacturers that support this PGN shall support both PEMS Engine Fuel Mass Flow Rate (SPN 6893) and Vehicle Fuel Rate (SPN 6894) even if the ...";
CM_ SG_ 2566671358 CylFuelRate "Cylinder fuel rate shall indicate the amount of fuel injected into the cylinder for combustion during the most recent intake stroke of the engine.

NOTE: Cylinder fuel rate shall indicate zero mg/stroke when the engine is not running.";
CM_ SG_ 2566671358 EngExhaustFlowRate "Engine Exhaust Flow Rate shall indicate the measured/calculated exhaust gas mass flow upstream of the aftertreatment system.
Engine Exhaust Flow Rate shall be calculated as the average exhaust flow rate over the last 1000 milliseconds prior to the ...";
CM_ SG_ 2566671358 VehicleFuelRate "Vehicle Fuel Rate shall indicate the amount of fuel consumed by the engine and fuel injected directly into the aftertreatment system per unit of time, in grams per second.
Vehicle Fuel Rate shall be calculated as the sum of the fuel consumed over ...";
CM_ SG_ 2566671358 PEMSEngFuelMassFlowRate "PEMS Engine Fuel Mass Flow Rate shall indicate the amount of fuel consumed by the engine per unit of time (does not include fuel injected directly into the aftertreatment system, but does include fuel injected into the engine cylinders for the ...";
BA_DEF_  "DBName" STRING ;
BA_DEF_ SG_  "SigType" ENUM  "Default","Range","RangeSigned","ASCII","Discrete","Control","ReferencePGN","DTC","StringDelimiter","StringLength","StringLengthControl","MessageCounter","MessageChecksum";
BA_DEF_ SG_  "GenSigStartValue" INT 0 2147483647;
BA_DEF_ SG_  "GenSigSendType" ENUM  "Cyclic","OnWrite","OnWriteWithRepetition","OnChange","OnChangeWithRepetition","IfActive","IfActiveWithRepetition","NoSigSendType";
BA_DEF_ SG_  "GenSigILSupport" ENUM  "No","Yes";
BA_DEF_ SG_  "GenSigEVName" STRING ;
BA_DEF_ SG_  "SPN" INT 0 524287;
BA_DEF_ BO_  "TpJ1939VarDlc" ENUM  "No","Yes";
BA_DEF_ BO_  "GenMsgCycleTimeFast" INT 0 3600000;
BA_DEF_ BO_  "GenMsgStartDelayTime" INT 0 100000;
BA_DEF_ BO_  "GenMsgILSupport" ENUM  "No","Yes";
BA_DEF_ BO_  "GenMsgDelayTime" INT 0 1000;
BA_DEF_ BO_  "GenMsgRequestable" INT 0 1;
BA_DEF_ BO_  "GenMsgSendType" ENUM  "cyclic","NotUsed","NotUsed","NotUsed","NotUsed","NotUsed","NotUsed","IfActive","noMsgSendType";
BA_DEF_ BO_  "VFrameFormat" ENUM  "StandardCAN","ExtendedCAN","reserved","J1939PG";
BA_DEF_ BO_  "GenMsgCycleTime" INT 0 3600000;
BA_DEF_ BU_  "NmStationAddress" INT 0 255;
BA_DEF_ BU_  "NmJ1939IndustryGroup" INT 0 7;
BA_DEF_ BU_  "NmJ1939System" INT 0 127;
BA_DEF_ BU_  "NmJ1939Function" INT 0 255;
BA_DEF_ BU_  "NmJ1939FunctionInstance" INT 0 7;
BA_DEF_ BU_  "NmJ1939ECUInstance" INT 0 3;
BA_DEF_  "SAE_J1939_DA_SpecVersion" STRING ;
BA_DEF_  "SAE_J1939_81_SpecVersion" STRING ;
BA_DEF_  "DatabaseVersion" STRING ;
BA_DEF_  "BusType" STRING ;
BA_DEF_  "ProtocolType" STRING ;
BA_DEF_  "SAE_J1939_75_SpecVersion" STRING ;
BA_DEF_  "SAE_J1939_21_SpecVersion" STRING ;
BA_DEF_  "SAE_J1939_73_SpecVersion" STRING ;
BA_DEF_  "SAE_J1939_71_SpecVersion" STRING ;
BA_DEF_ SG_  "SystemSignalLongSymbol" STRING ;
BA_DEF_DEF_  "DBName" "";
BA_DEF_DEF_  "SigType" "Default";
BA_DEF_DEF_  "GenSigStartValue" 0;
BA_DEF_DEF_  "GenSigSendType" "NoSigSendType";
BA_DEF_DEF_  "GenSigILSupport" "Yes";
BA_DEF_DEF_  "GenSigEVName" "Env@Nodename_@Signame";
BA_DEF_DEF_  "SPN" 0;
BA_DEF_DEF_  "TpJ1939VarDlc" "No";
BA_DEF_DEF_  "GenMsgCycleTimeFast" 0;
BA_DEF_DEF_  "GenMsgStartDelayTime" 0;
BA_DEF_DEF_  "GenMsgILSupport" "Yes";
BA_DEF_DEF_  "GenMsgDelayTime" 0;
BA_DEF_DEF_  "GenMsgRequestable" 1;
BA_DEF_DEF_  "GenMsgSendType" "noMsgSendType";
BA_DEF_DEF_  "VFrameFormat" "J1939PG";
BA_DEF_DEF_  "GenMsgCycleTime" 0;
BA_DEF_DEF_  "NmStationAddress" 254;
BA_DEF_DEF_  "NmJ1939IndustryGroup" 0;
BA_DEF_DEF_  "NmJ1939System" 0;
BA_DEF_DEF_  "NmJ1939Function" 0;
BA_DEF_DEF_  "NmJ1939FunctionInstance" 0;
BA_DEF_DEF_  "NmJ1939ECUInstance" 0;
BA_DEF_DEF_  "SAE_J1939_DA_SpecVersion" "";
BA_DEF_DEF_  "SAE_J1939_81_SpecVersion" "";
BA_DEF_DEF_  "DatabaseVersion" "";
BA_DEF_DEF_  "BusType" "";
BA_DEF_DEF_  "ProtocolType" "";
BA_DEF_DEF_  "SAE_J1939_75_SpecVersion" "";
BA_DEF_DEF_  "SAE_J1939_21_SpecVersion" "";
BA_DEF_DEF_  "SAE_J1939_73_SpecVersion" "";
BA_DEF_DEF_  "SAE_J1939_71_SpecVersion" "";
BA_DEF_DEF_  "SystemSignalLongSymbol" "";
BA_ "SAE_J1939_DA_SpecVersion" "2015-01";
BA_ "SAE_J1939_81_SpecVersion" "2012-05";
BA_ "DatabaseVersion" "8.5";
BA_ "BusType" "CAN";
BA_ "ProtocolType" "J1939";
BA_ "SAE_J1939_75_SpecVersion" "2012-05";
BA_ "SAE_J1939_21_SpecVersion" "2006-10";
BA_ "SAE_J1939_73_SpecVersion" "2012-10";
BA_ "SAE_J1939_71_SpecVersion" "2012-10";
BA_ "DBName" "J1939";
BA_ "NmStationAddress" BU_ Battery_Management_Cntrl_1 243;
BA_ "NmStationAddress" BU_ PowertrainControlModule 90;
BA_ "NmStationAddress" BU_ AtmosphericSensor 89;
BA_ "NmJ1939Function" BU_ AtmosphericSensor 76;
BA_ "NmStationAddress" BU_ SafetyRestraintSystem2 88;
BA_ "NmJ1939Function" BU_ SafetyRestraintSystem2 132;
BA_ "NmJ1939FunctionInstance" BU_ SafetyRestraintSystem2 1;
BA_ "NmStationAddress" BU_ Aftertreatment_2_GasOutlet 87;
BA_ "NmJ1939Function" BU_ Aftertreatment_2_GasOutlet 68;
BA_ "NmJ1939FunctionInstance" BU_ Aftertreatment_2_GasOutlet 1;
BA_ "NmJ1939ECUInstance" BU_ Aftertreatment_2_GasOutlet 1;
BA_ "NmStationAddress" BU_ Aftertreatment_2_GasIntake 86;
BA_ "NmJ1939Function" BU_ Aftertreatment_2_GasIntake 68;
BA_ "NmJ1939FunctionInstance" BU_ Aftertreatment_2_GasIntake 1;
BA_ "NmStationAddress" BU_ DieselParticulateFilterControl 85;
BA_ "NmJ1939Function" BU_ DieselParticulateFilterControl 69;
BA_ "NmStationAddress" BU_ Turbocharger 2;
BA_ "NmJ1939Function" BU_ Turbocharger 133;
BA_ "NmStationAddress" BU_ SafetyRestraintSystem1 83;
BA_ "NmJ1939Function" BU_ SafetyRestraintSystem1 132;
BA_ "NmStationAddress" BU_ CabDisplay2 84;
BA_ "NmJ1939Function" BU_ CabDisplay2 60;
BA_ "NmJ1939FunctionInstance" BU_ CabDisplay2 1;
BA_ "NmStationAddress" BU_ Aftertreatment_1_GasOutlet 82;
BA_ "NmJ1939Function" BU_ Aftertreatment_1_GasOutlet 68;
BA_ "NmJ1939ECUInstance" BU_ Aftertreatment_1_GasOutlet 1;
BA_ "NmStationAddress" BU_ Aftertreatment_1_GasIntake 81;
BA_ "NmJ1939Function" BU_ Aftertreatment_1_GasIntake 68;
BA_ "NmStationAddress" BU_ OnBoardDataLogger 251;
BA_ "NmJ1939Function" BU_ OnBoardDataLogger 130;
BA_ "NmStationAddress" BU_ OffBoardDiagnosticTool2 250;
BA_ "NmJ1939Function" BU_ OffBoardDiagnosticTool2 129;
BA_ "NmJ1939FunctionInstance" BU_ OffBoardDiagnosticTool2 1;
BA_ "NmStationAddress" BU_ OffBoardDiagnosticTool1 249;
BA_ "NmJ1939Function" BU_ OffBoardDiagnosticTool1 129;
BA_ "NmStationAddress" BU_ FileServer 248;
BA_ "NmJ1939Function" BU_ FileServer 61;
BA_ "NmStationAddress" BU_ ParkingBrakeController 80;
BA_ "NmJ1939Function" BU_ ParkingBrakeController 9;
BA_ "NmJ1939FunctionInstance" BU_ ParkingBrakeController 1;
BA_ "NmStationAddress" BU_ SeatController2 79;
BA_ "NmJ1939Function" BU_ SeatController2 40;
BA_ "NmJ1939FunctionInstance" BU_ SeatController2 1;
BA_ "NmStationAddress" BU_ FanDriveController 78;
BA_ "NmJ1939Function" BU_ FanDriveController 58;
BA_ "NmStationAddress" BU_ SteeringColumnUnit 77;
BA_ "NmJ1939Function" BU_ SteeringColumnUnit 57;
BA_ "NmStationAddress" BU_ CommunicationUnitRadio 76;
BA_ "NmJ1939Function" BU_ CommunicationUnitRadio 56;
BA_ "NmStationAddress" BU_ CommunicationUnitSatellite 75;
BA_ "NmJ1939Function" BU_ CommunicationUnitSatellite 55;
BA_ "NmStationAddress" BU_ CommunicationUnitCellular 74;
BA_ "NmJ1939Function" BU_ CommunicationUnitCellular 54;
BA_ "NmStationAddress" BU_ PropulsionBatteryCharger 73;
BA_ "NmJ1939Function" BU_ PropulsionBatteryCharger 31;
BA_ "NmStationAddress" BU_ ChassisController2 72;
BA_ "NmJ1939Function" BU_ ChassisController2 52;
BA_ "NmJ1939FunctionInstance" BU_ ChassisController2 1;
BA_ "NmStationAddress" BU_ ChassisController1 71;
BA_ "NmJ1939Function" BU_ ChassisController1 52;
BA_ "NmStationAddress" BU_ EngineValveControl 70;
BA_ "NmJ1939Function" BU_ EngineValveControl 63;
BA_ "NmStationAddress" BU_ AuxiliaryHeater2 69;
BA_ "NmJ1939Function" BU_ AuxiliaryHeater2 50;
BA_ "NmJ1939FunctionInstance" BU_ AuxiliaryHeater2 1;
BA_ "NmStationAddress" BU_ AuxiliaryHeater1 68;
BA_ "NmJ1939Function" BU_ AuxiliaryHeater1 50;
BA_ "NmStationAddress" BU_ ClutchUnit 67;
BA_ "NmJ1939Function" BU_ ClutchUnit 49;
BA_ "NmStationAddress" BU_ RampControl 66;
BA_ "NmJ1939Function" BU_ RampControl 48;
BA_ "NmStationAddress" BU_ InformationSystem1 65;
BA_ "NmJ1939Function" BU_ InformationSystem1 47;
BA_ "NmStationAddress" BU_ SuspensionSystemController2 64;
BA_ "NmJ1939Function" BU_ SuspensionSystemController2 35;
BA_ "NmJ1939FunctionInstance" BU_ SuspensionSystemController2 1;
BA_ "NmStationAddress" BU_ OilSensor 63;
BA_ "NmJ1939Function" BU_ OilSensor 46;
BA_ "NmStationAddress" BU_ VehicleDynamicStability 62;
BA_ "NmJ1939Function" BU_ VehicleDynamicStability 45;
BA_ "NmStationAddress" BU_ ExhaustEmissionController 61;
BA_ "NmJ1939Function" BU_ ExhaustEmissionController 44;
BA_ "NmStationAddress" BU_ TransmissionDisplay2 60;
BA_ "NmJ1939Function" BU_ TransmissionDisplay2 43;
BA_ "NmJ1939FunctionInstance" BU_ TransmissionDisplay2 1;
BA_ "NmStationAddress" BU_ TransmissionDisplay1 59;
BA_ "NmJ1939Function" BU_ TransmissionDisplay1 43;
BA_ "NmStationAddress" BU_ ClimateControl2 58;
BA_ "NmJ1939Function" BU_ ClimateControl2 21;
BA_ "NmJ1939FunctionInstance" BU_ ClimateControl2 1;
BA_ "NmStationAddress" BU_ WaterPumpController 57;
BA_ "NmJ1939Function" BU_ WaterPumpController 42;
BA_ "NmStationAddress" BU_ RearAxleSteeringController 56;
BA_ "NmJ1939Function" BU_ RearAxleSteeringController 16;
BA_ "NmJ1939FunctionInstance" BU_ RearAxleSteeringController 1;
BA_ "NmStationAddress" BU_ LightingOperatorControl 55;
BA_ "NmJ1939Function" BU_ LightingOperatorControl 41;
BA_ "NmStationAddress" BU_ SeatController1 54;
BA_ "NmJ1939Function" BU_ SeatController1 40;
BA_ "NmStationAddress" BU_ IgnitionController2 53;
BA_ "NmJ1939Function" BU_ IgnitionController2 39;
BA_ "NmJ1939FunctionInstance" BU_ IgnitionController2 1;
BA_ "NmStationAddress" BU_ IgnitionController1 52;
BA_ "NmJ1939Function" BU_ IgnitionController1 39;
BA_ "NmStationAddress" BU_ TirePressureController 51;
BA_ "NmJ1939Function" BU_ TirePressureController 38;
BA_ "NmStationAddress" BU_ CabController2 50;
BA_ "NmJ1939Function" BU_ CabController2 37;
BA_ "NmJ1939FunctionInstance" BU_ CabController2 1;
BA_ "NmStationAddress" BU_ CabController1 49;
BA_ "NmJ1939Function" BU_ CabController1 37;
BA_ "NmStationAddress" BU_ PneumaticSystemController 48;
BA_ "NmJ1939Function" BU_ PneumaticSystemController 36;
BA_ "NmStationAddress" BU_ SuspensionSystemController1 47;
BA_ "NmJ1939Function" BU_ SuspensionSystemController1 35;
BA_ "NmStationAddress" BU_ HydraulicPumpController 46;
BA_ "NmJ1939Function" BU_ HydraulicPumpController 34;
BA_ "NmStationAddress" BU_ EnduranceBrakingSystem 45;
BA_ "NmJ1939Function" BU_ EnduranceBrakingSystem 64;
BA_ "NmStationAddress" BU_ RetarderExhaustEngine2 44;
BA_ "NmJ1939Function" BU_ RetarderExhaustEngine2 12;
BA_ "NmJ1939FunctionInstance" BU_ RetarderExhaustEngine2 1;
BA_ "NmStationAddress" BU_ OnBoardDiagnosticUnit 43;
BA_ "NmJ1939Function" BU_ OnBoardDiagnosticUnit 62;
BA_ "NmStationAddress" BU_ HeadwayController 42;
BA_ "NmJ1939Function" BU_ HeadwayController 32;
BA_ "NmStationAddress" BU_ RetarderExhaustEngine1 41;
BA_ "NmJ1939Function" BU_ RetarderExhaustEngine1 12;
BA_ "NmStationAddress" BU_ CabDisplay1 40;
BA_ "NmJ1939Function" BU_ CabDisplay1 60;
BA_ "NmStationAddress" BU_ ManagementComputer 39;
BA_ "NmJ1939Function" BU_ ManagementComputer 30;
BA_ "NmStationAddress" BU_ VirtualTerminal 38;
BA_ "NmJ1939Function" BU_ VirtualTerminal 29;
BA_ "NmStationAddress" BU_ OffVehicleGateway 37;
BA_ "NmJ1939Function" BU_ OffVehicleGateway 28;
BA_ "NmStationAddress" BU_ PowerTakeOffFront 36;
BA_ "NmJ1939Function" BU_ PowerTakeOffFront 27;
BA_ "NmStationAddress" BU_ HitchControl 35;
BA_ "NmStationAddress" BU_ AuxiliaryValveControl 34;
BA_ "NmJ1939IndustryGroup" BU_ AuxiliaryValveControl 2;
BA_ "NmJ1939System" BU_ AuxiliaryValveControl 1;
BA_ "NmJ1939Function" BU_ AuxiliaryValveControl 129;
BA_ "NmStationAddress" BU_ BodyController 33;
BA_ "NmJ1939Function" BU_ BodyController 26;
BA_ "NmStationAddress" BU_ TractorTrailerBridge1 32;
BA_ "NmJ1939Function" BU_ TractorTrailerBridge1 25;
BA_ "NmStationAddress" BU_ StarterSystem 31;
BA_ "NmJ1939Function" BU_ StarterSystem 59;
BA_ "NmStationAddress" BU_ ElectricalSystem 30;
BA_ "NmJ1939Function" BU_ ElectricalSystem 67;
BA_ "NmStationAddress" BU_ VehicleSecurity 29;
BA_ "NmJ1939Function" BU_ VehicleSecurity 24;
BA_ "NmStationAddress" BU_ VehicleNavigation 28;
BA_ "NmJ1939Function" BU_ VehicleNavigation 23;
BA_ "NmStationAddress" BU_ AerodynamicControl 27;
BA_ "NmJ1939Function" BU_ AerodynamicControl 22;
BA_ "NmStationAddress" BU_ ElectricalChargingSystem 26;
BA_ "NmJ1939Function" BU_ ElectricalChargingSystem 53;
BA_ "NmStationAddress" BU_ ClimateControl1 25;
BA_ "NmJ1939Function" BU_ ClimateControl1 21;
BA_ "NmStationAddress" BU_ TripRecorder 24;
BA_ "NmJ1939Function" BU_ TripRecorder 20;
BA_ "NmStationAddress" BU_ InstrumentCluster 23;
BA_ "NmJ1939Function" BU_ InstrumentCluster 19;
BA_ "NmStationAddress" BU_ SuspensionDriveAxle2 22;
BA_ "NmJ1939Function" BU_ SuspensionDriveAxle2 18;
BA_ "NmJ1939FunctionInstance" BU_ SuspensionDriveAxle2 1;
BA_ "NmStationAddress" BU_ SuspensionDriveAxle1 21;
BA_ "NmJ1939Function" BU_ SuspensionDriveAxle1 18;
BA_ "NmStationAddress" BU_ SuspensionSteerAxle 20;
BA_ "NmJ1939Function" BU_ SuspensionSteerAxle 17;
BA_ "NmStationAddress" BU_ SteeringController 19;
BA_ "NmJ1939Function" BU_ SteeringController 16;
BA_ "NmStationAddress" BU_ FuelSystem 18;
BA_ "NmJ1939Function" BU_ FuelSystem 15;
BA_ "NmStationAddress" BU_ CruiseControl 17;
BA_ "NmJ1939Function" BU_ CruiseControl 14;
BA_ "NmStationAddress" BU_ RetarderDriveline 16;
BA_ "NmJ1939Function" BU_ RetarderDriveline 13;
BA_ "NmStationAddress" BU_ RetarderEngine 15;
BA_ "NmJ1939Function" BU_ RetarderEngine 12;
BA_ "NmStationAddress" BU_ BrakesDriveAxle2 14;
BA_ "NmJ1939Function" BU_ BrakesDriveAxle2 11;
BA_ "NmJ1939FunctionInstance" BU_ BrakesDriveAxle2 1;
BA_ "NmStationAddress" BU_ BrakesDriveAxle1 13;
BA_ "NmJ1939Function" BU_ BrakesDriveAxle1 11;
BA_ "NmStationAddress" BU_ BrakesSystemController 11;
BA_ "NmJ1939Function" BU_ BrakesSystemController 9;
BA_ "NmStationAddress" BU_ BrakesSteerAxle 12;
BA_ "NmJ1939Function" BU_ BrakesSteerAxle 10;
BA_ "NmStationAddress" BU_ AxleDrive2 10;
BA_ "NmJ1939Function" BU_ AxleDrive2 8;
BA_ "NmJ1939FunctionInstance" BU_ AxleDrive2 1;
BA_ "NmStationAddress" BU_ AxleDrive1 9;
BA_ "NmJ1939Function" BU_ AxleDrive1 8;
BA_ "NmStationAddress" BU_ AxleSteering 8;
BA_ "NmJ1939Function" BU_ AxleSteering 7;
BA_ "NmStationAddress" BU_ PowerTakeOff 7;
BA_ "NmJ1939Function" BU_ PowerTakeOff 6;
BA_ "NmStationAddress" BU_ ShiftConsoleSecondary 6;
BA_ "NmJ1939Function" BU_ ShiftConsoleSecondary 5;
BA_ "NmJ1939FunctionInstance" BU_ ShiftConsoleSecondary 1;
BA_ "NmStationAddress" BU_ ShiftConsolePrimary 5;
BA_ "NmJ1939Function" BU_ ShiftConsolePrimary 5;
BA_ "NmStationAddress" BU_ Transmission2 4;
BA_ "NmJ1939Function" BU_ Transmission2 3;
BA_ "NmJ1939FunctionInstance" BU_ Transmission2 1;
BA_ "NmStationAddress" BU_ Transmission1 3;
BA_ "NmJ1939Function" BU_ Transmission1 3;
BA_ "NmStationAddress" BU_ Engine2 1;
BA_ "NmJ1939FunctionInstance" BU_ Engine2 1;
BA_ "NmStationAddress" BU_ Engine1 0;
BA_ "GenMsgSendType" BO_ 2364607475 0;
BA_ "GenMsgCycleTime" BO_ 2364607475 100;
BA_ "GenMsgSendType" BO_ 2364607219 0;
BA_ "GenMsgCycleTime" BO_ 2364607219 100;
BA_ "GenMsgSendType" BO_ 2364606707 0;
BA_ "GenMsgCycleTime" BO_ 2364606707 100;
BA_ "GenMsgSendType" BO_ 2364552947 0;
BA_ "GenMsgCycleTime" BO_ 2364552947 100;
BA_ "GenMsgSendType" BO_ 2633785075 7;
BA_ "GenMsgSendType" BO_ 2566675955 7;
BA_ "GenMsgSendType" BO_ 2364606963 0;
BA_ "GenMsgCycleTime" BO_ 2364606963 100;
BA_ "GenMsgSendType" BO_ 2364580083 0;
BA_ "GenMsgCycleTime" BO_ 2364580083 100;
BA_ "GenMsgCycleTimeFast" BO_ 2364577523 20;
BA_ "GenMsgSendType" BO_ 2364577523 0;
BA_ "GenMsgCycleTime" BO_ 2364577523 100;
BA_ "GenMsgSendType" BO_ 2364577267 0;
BA_ "GenMsgCycleTime" BO_ 2364577267 100;
BA_ "GenMsgSendType" BO_ 2364577011 0;
BA_ "GenMsgCycleTime" BO_ 2364577011 20;
BA_ "GenMsgSendType" BO_ 2364576755 0;
BA_ "GenMsgCycleTime" BO_ 2364576755 100;
BA_ "GenMsgCycleTime" BO_ 2364576499 20;
BA_ "GenMsgSendType" BO_ 2364576243 0;
BA_ "GenMsgCycleTime" BO_ 2364576243 20;
BA_ "GenMsgSendType" BO_ 2364575987 0;
BA_ "GenMsgCycleTime" BO_ 2364575987 20;
BA_ "GenMsgSendType" BO_ 2558263038 0;
BA_ "GenMsgCycleTime" BO_ 2558263038 1000;
BA_ "GenMsgSendType" BO_ 2558197502 0;
BA_ "GenMsgCycleTime" BO_ 2558197502 1000;
BA_ "GenMsgSendType" BO_ 2558131966 0;
BA_ "GenMsgCycleTime" BO_ 2558131966 1000;
BA_ "GenMsgSendType" BO_ 2558066430 0;
BA_ "GenMsgCycleTime" BO_ 2558066430 1000;
BA_ "GenMsgSendType" BO_ 2558000894 0;
BA_ "GenMsgCycleTime" BO_ 2558000894 1000;
BA_ "GenMsgSendType" BO_ 2557935358 0;
BA_ "GenMsgCycleTime" BO_ 2557935358 1000;
BA_ "GenMsgSendType" BO_ 2557869822 0;
BA_ "GenMsgCycleTime" BO_ 2557869822 1000;
BA_ "GenMsgSendType" BO_ 2557804286 0;
BA_ "GenMsgCycleTime" BO_ 2557804286 1000;
BA_ "GenMsgSendType" BO_ 2557738750 0;
BA_ "GenMsgCycleTime" BO_ 2557738750 1000;
BA_ "GenMsgCycleTime" BO_ 2350644979 20;
BA_ "GenMsgSendType" BO_ 2350644979 0;
BA_ "GenMsgSendType" BO_ 2566658558 0;
BA_ "GenMsgCycleTime" BO_ 2566658558 5000;
BA_ "GenMsgSendType" BO_ 2566658302 0;
BA_ "GenMsgCycleTime" BO_ 2566658302 5000;
BA_ "GenMsgSendType" BO_ 2499549182 0;
BA_ "GenMsgCycleTime" BO_ 2499549182 1000;
BA_ "GenMsgSendType" BO_ 2499548926 0;
BA_ "GenMsgCycleTime" BO_ 2499548926 1000;
BA_ "GenMsgSendType" BO_ 2499548670 0;
BA_ "GenMsgCycleTime" BO_ 2499548670 100;
BA_ "GenMsgDelayTime" BO_ 2499548158 100;
BA_ "GenMsgSendType" BO_ 2499548158 0;
BA_ "GenMsgCycleTime" BO_ 2499548158 1000;
BA_ "GenMsgDelayTime" BO_ 2499547902 100;
BA_ "GenMsgSendType" BO_ 2499547902 0;
BA_ "GenMsgCycleTime" BO_ 2499547902 1000;
BA_ "GenMsgDelayTime" BO_ 2431710718 20;
BA_ "GenMsgDelayTime" BO_ 2431708670 20;
BA_ "GenMsgSendType" BO_ 2565926142 0;
BA_ "GenMsgCycleTime" BO_ 2565926142 50;
BA_ "GenMsgSendType" BO_ 2565925886 0;
BA_ "GenMsgCycleTime" BO_ 2565925886 50;
BA_ "GenMsgSendType" BO_ 2565925630 0;
BA_ "GenMsgCycleTime" BO_ 2565925630 50;
BA_ "GenMsgSendType" BO_ 2565925374 0;
BA_ "GenMsgCycleTime" BO_ 2565925374 50;
BA_ "GenMsgSendType" BO_ 2364598526 0;
BA_ "GenMsgCycleTime" BO_ 2364598526 50;
BA_ "TpJ1939VarDlc" BO_ 2558525182 1;
BA_ "GenMsgSendType" BO_ 2350841598 0;
BA_ "GenMsgCycleTime" BO_ 2350841598 200;
BA_ "GenMsgSendType" BO_ 2566838014 0;
BA_ "GenMsgCycleTime" BO_ 2566838014 1000;
BA_ "GenMsgSendType" BO_ 2566756350 0;
BA_ "GenMsgCycleTime" BO_ 2566756350 1000;
BA_ "GenMsgSendType" BO_ 2566756094 0;
BA_ "GenMsgCycleTime" BO_ 2566756094 1000;
BA_ "GenMsgSendType" BO_ 2566687998 0;
BA_ "GenMsgCycleTime" BO_ 2566687998 200;
BA_ "GenMsgSendType" BO_ 2566687742 0;
BA_ "GenMsgCycleTime" BO_ 2566687742 200;
BA_ "GenMsgDelayTime" BO_ 2365348350 50;
BA_ "GenMsgSendType" BO_ 2365348350 0;
BA_ "GenMsgCycleTime" BO_ 2365348350 500;
BA_ "GenMsgSendType" BO_ 2566674686 0;
BA_ "GenMsgCycleTime" BO_ 2566674686 1000;
BA_ "GenMsgDelayTime" BO_ 2566674430 1000;
BA_ "GenMsgSendType" BO_ 2566674430 0;
BA_ "GenMsgCycleTime" BO_ 2566674430 10000;
BA_ "GenMsgDelayTime" BO_ 2566674174 1000;
BA_ "GenMsgSendType" BO_ 2566674174 0;
BA_ "GenMsgCycleTime" BO_ 2566674174 10000;
BA_ "GenMsgSendType" BO_ 2566673406 0;
BA_ "GenMsgCycleTime" BO_ 2566673406 500;
BA_ "GenMsgDelayTime" BO_ 2633782014 1000;
BA_ "GenMsgSendType" BO_ 2633782014 0;
BA_ "GenMsgCycleTime" BO_ 2633782014 10000;
BA_ "GenMsgSendType" BO_ 2365346302 0;
BA_ "GenMsgCycleTime" BO_ 2365346302 100;
BA_ "GenMsgSendType" BO_ 2566672638 0;
BA_ "GenMsgCycleTime" BO_ 2566672638 1000;
BA_ "GenMsgSendType" BO_ 2566672382 0;
BA_ "GenMsgCycleTime" BO_ 2566672382 1000;
BA_ "GenMsgSendType" BO_ 2566672126 0;
BA_ "GenMsgCycleTime" BO_ 2566672126 500;
BA_ "GenMsgSendType" BO_ 2566671870 0;
BA_ "GenMsgCycleTime" BO_ 2566671870 500;
BA_ "SPN" SG_ 3221225472 HVES1HVBPsvITR_8432 8432;
BA_ "SPN" SG_ 3221225472 HVES1HVBAcvITR_8431 8431;
BA_ "SPN" SG_ 3221225472 HVES1LoCellStOChaCellNo_8248 8248;
BA_ "SPN" SG_ 3221225472 HVES1LoCellStOChaModuNo_8247 8247;
BA_ "SPN" SG_ 3221225472 HVES1HiCellStOChaCellNo_8246 8246;
BA_ "SPN" SG_ 3221225472 HVES1HiCellStOChaModuNo_8245 8245;
BA_ "SPN" SG_ 3221225472 TranIdleGovrnrFuelingInhbit_7829 7829;
BA_ "SigType" SG_ 3221225472 NumberOfMembersInWorkingSet 3;
BA_ "SPN" SG_ 3221225472 NumberOfMembersInWorkingSet 2409;
BA_ "SPN" SG_ 3221225472 SourceAddress 5600;
BA_ "SPN" SG_ 3221225472 NncntnuslyMonitoredSystemsStatus 1223;
BA_ "SPN" SG_ 3221225472 NncntnslyMonitoredSystemsSupport 1222;
BA_ "SPN" SG_ 3221225472 CntnslyMntrdSystmsSupport_Status 1221;
BA_ "SigType" SG_ 3221225472 AETCTorqueValue 1;
BA_ "SPN" SG_ 3221225472 AETCTorqueValue 3561;
BA_ "SigType" SG_ 3221225472 TrailerWeight 1;
BA_ "SPN" SG_ 3221225472 TrailerWeight 180;
BA_ "SPN" SG_ 3221225472 ReferenceTirePressSetting 3193;
BA_ "SPN" SG_ 3221225472 ReferenceTirePress 3191;
BA_ "SPN" SG_ 3221225472 TirePressThresholdDetection 2587;
BA_ "SigType" SG_ 3221225472 TireAirLeakageRate 1;
BA_ "SPN" SG_ 3221225472 TireAirLeakageRate 2586;
BA_ "SigType" SG_ 3221225472 CTIWheelEndElectricalFault 4;
BA_ "SPN" SG_ 3221225472 CTIWheelEndElectricalFault 1697;
BA_ "SigType" SG_ 3221225472 CTITireStatus 4;
BA_ "SPN" SG_ 3221225472 CTITireStatus 1698;
BA_ "SigType" SG_ 3221225472 CTIWheelSensorStatus 4;
BA_ "SPN" SG_ 3221225472 CTIWheelSensorStatus 1699;
BA_ "SigType" SG_ 3221225472 TireTemp 1;
BA_ "SPN" SG_ 3221225472 TireTemp 242;
BA_ "SigType" SG_ 3221225472 TirePress 1;
BA_ "SPN" SG_ 3221225472 TirePress 241;
BA_ "SigType" SG_ 3221225472 EngTurningGearEngaged 4;
BA_ "SPN" SG_ 3221225472 EngTurningGearEngaged 1206;
BA_ "SigType" SG_ 3221225472 AETCSpeedValue 1;
BA_ "SPN" SG_ 3221225472 AETCSpeedValue 3560;
BA_ "SPN" SG_ 2364607475 HVES1LoCellTModuNo_8243 8243;
BA_ "SPN" SG_ 2364607475 HVES1LoCellTCellNo_8244 8244;
BA_ "SPN" SG_ 2364607475 HVES1HiCellTModuNo_8241 8241;
BA_ "SPN" SG_ 2364607475 HVES1HiCellTCellNo_8242 8242;
BA_ "SPN" SG_ 2364607219 HVES1AvgCellU_8240 8240;
BA_ "SPN" SG_ 2364607219 HVES1LoCellUModuNo_8238 8238;
BA_ "SPN" SG_ 2364607219 HVES1LoCellUCellNo_8239 8239;
BA_ "SPN" SG_ 2364607219 HVES1HiCellUModuNo_8236 8236;
BA_ "SPN" SG_ 2364607219 HVES1HiCellUCellNo_8237 8237;
BA_ "SPN" SG_ 2364606707 HVES1M11OperlSts_8224 8224;
BA_ "SPN" SG_ 2364606707 HVES1M9OperlSts_8222 8222;
BA_ "SPN" SG_ 2364606707 HVES1M8OperlSts_8221 8221;
BA_ "SPN" SG_ 2364606707 HVES1M7OperlSts_8220 8220;
BA_ "SPN" SG_ 2364606707 HVES1M6OperlSts_8219 8219;
BA_ "SPN" SG_ 2364606707 HVES1M5OperlSts_8218 8218;
BA_ "SPN" SG_ 2364606707 HVES1M4OperlSts_8217 8217;
BA_ "SPN" SG_ 2364606707 HVES1M3OperlSts_8216 8216;
BA_ "SPN" SG_ 2364606707 HVES1M2OperlSts_8215 8215;
BA_ "SPN" SG_ 2364606707 HVES1M1OperlSts_8214 8214;
BA_ "SPN" SG_ 2364606707 HVES1M16OperlSts_8229 8229;
BA_ "SPN" SG_ 2364606707 HVES1M15OperlSts_8228 8228;
BA_ "SPN" SG_ 2364606707 HVES1M14OperlSts_8227 8227;
BA_ "SPN" SG_ 2364606707 HVES1M13OperlSts_8226 8226;
BA_ "SPN" SG_ 2364606707 HVES1M12OperlSts_8225 8225;
BA_ "SPN" SG_ 2364606707 HVES1M10OperlSts_8223 8223;
BA_ "SPN" SG_ 2364552947 HVES1CPLDToUndefCause_8114 8114;
BA_ "SPN" SG_ 2364552947 HVES1CPLDTBT_8110 8110;
BA_ "SPN" SG_ 2364552947 HVES1CPLDTBOrCellV_8112 8112;
BA_ "SPN" SG_ 2364552947 HVES1CPLDTBDiagcCdn_8111 8111;
BA_ "SPN" SG_ 2364552947 HVES1CPLDTBCur_8113 8113;
BA_ "SPN" SG_ 2364552947 HVES1DPLDTStOfCha_8109 8109;
BA_ "SPN" SG_ 2364552947 HVES1DPLDTStOfCha_8103 8103;
BA_ "SPN" SG_ 2364552947 HVES1DPLDToUndefCause_8108 8108;
BA_ "SPN" SG_ 2364552947 HVES1DPLDTBT_8104 8104;
BA_ "SPN" SG_ 2364552947 HVES1DPLDTBOrCellV_8106 8106;
BA_ "SPN" SG_ 2364552947 HVES1DPLDTBDiagcCdn_8105 8105;
BA_ "SPN" SG_ 2364552947 HVES1DPLDTBCur_8107 8107;
BA_ "SPN" SG_ 2633785075 HVES1TotEgyThput_8211 8211;
BA_ "SPN" SG_ 2633785075 HVES1TotAccumCha_8212 8212;
BA_ "SPN" SG_ 2633785075 HVES1StOfHealth_8121 8121;
BA_ "SPN" SG_ 2633785075 HVES1CtorOpenUndLoa_8122 8122;
BA_ "SPN" SG_ 2566675955 HVES1RecomMinSOC_8118 8118;
BA_ "SPN" SG_ 2566675955 HVES1RecomMinOpergV_8116 8116;
BA_ "GenSigStartValue" SG_ 2566675955 HVES1RecomMinOpergT_8208 8736;
BA_ "SPN" SG_ 2566675955 HVES1RecomMinOpergT_8208 8208;
BA_ "SPN" SG_ 2566675955 HVES1RecomMaxSOC_8119 8119;
BA_ "SPN" SG_ 2566675955 HVES1RecomMaxOpergV_8117 8117;
BA_ "GenSigStartValue" SG_ 2566675955 HVES1RecomMaxOpergT_8120 8736;
BA_ "SPN" SG_ 2566675955 HVES1RecomMaxOpergT_8120 8120;
BA_ "SPN" SG_ 2566675955 HVES1NomVoltage_8115 8115;
BA_ "SPN" SG_ 2566675955 HVES1CellMinVLim_8210 8210;
BA_ "SPN" SG_ 2566675955 HVES1CellMaxVLim_8209 8209;
BA_ "SPN" SG_ 2364606963 HVES1TMSSLIInPwr_8230 8230;
BA_ "SPN" SG_ 2364606963 HVES1TMSRelHum_8233 8233;
BA_ "SPN" SG_ 2364606963 HVES1TMSMode_8235 8235;
BA_ "SPN" SG_ 2364606963 HVES1TMSHighV_8231 8231;
BA_ "SPN" SG_ 2364606963 HVES1TMSHeatrSts_8234 8234;
BA_ "SPN" SG_ 2364606963 HVES1TMSCpsr_8232 8232;
BA_ "SPN" SG_ 2364580083 HVES1MaxChaVLim_8090 8090;
BA_ "SPN" SG_ 2364580083 HVES1DischaEgyCp_8205 8205;
BA_ "SPN" SG_ 2364580083 HVES1ChaEgyCp_8206 8206;
BA_ "SPN" SG_ 2364577523 HVES1StOfChaSts_8100 8100;
BA_ "SPN" SG_ 2364577523 HVES1OperationlSts_8414 8414;
BA_ "SPN" SG_ 2364577523 HVES1IntChaSts_8207 8207;
BA_ "SPN" SG_ 2364577523 HVES1InertiaSwtSts_8099 8099;
BA_ "SPN" SG_ 2364577523 HVES1HVILSts_8098 8098;
BA_ "SPN" SG_ 2364577523 HVES1HVBusPsvIsoTstSts_8097 8097;
BA_ "SPN" SG_ 2364577523 HVES1HVBusPrechaRlySt_8094 8094;
BA_ "SPN" SG_ 2364577523 HVES1HVBusDiscnctWarn_8093 8093;
BA_ "SPN" SG_ 2364577523 HVES1HVBusCnctnSts_8413 8413;
BA_ "SPN" SG_ 2364577523 HVES1HVBusAcvIsoTstSts_8096 8096;
BA_ "SPN" SG_ 2364577523 HVES1HVBCtorStPos_8091 8091;
BA_ "SPN" SG_ 2364577523 HVES1HVBCtorStNeg_8092 8092;
BA_ "SPN" SG_ 2364577523 HVES1CtrOfPackCtorSt_8095 8095;
BA_ "SPN" SG_ 2364577523 HVES1CellBalnSts_8101 8101;
BA_ "SPN" SG_ 2364577523 HVES1CellBalnAcv_8102 8102;
BA_ "GenSigStartValue" SG_ 2364577267 HVES1ElectronicsT_8204 40;
BA_ "SPN" SG_ 2364577267 HVES1ElectronicsT_8204 8204;
BA_ "GenSigStartValue" SG_ 2364577267 HVES1OutletCooltT_8089 40;
BA_ "SPN" SG_ 2364577267 HVES1OutletCooltT_8089 8089;
BA_ "GenSigStartValue" SG_ 2364577267 HVES1InletCooltT_8088 40;
BA_ "SPN" SG_ 2364577267 HVES1InletCooltT_8088 8088;
BA_ "SPN" SG_ 2364577267 HVES1IgVoltage_8087 8087;
BA_ "SPN" SG_ 2364577267 HVES1BusVoltage_8086 8086;
BA_ "SPN" SG_ 2364577011 HVES1MinCellStOCha_8084 8084;
BA_ "SPN" SG_ 2364577011 HVES1MaxCellStOCha_8085 8085;
BA_ "GenSigStartValue" SG_ 2364577011 HVES1DchaCurLim_8082 32000;
BA_ "SPN" SG_ 2364577011 HVES1DchaCurLim_8082 8082;
BA_ "GenSigStartValue" SG_ 2364577011 HVES1ChaCurLim_8083 32000;
BA_ "SPN" SG_ 2364577011 HVES1ChaCurLim_8083 8083;
BA_ "SPN" SG_ 2364576755 HVES1DischargeCap_8079 8079;
BA_ "SPN" SG_ 2364576755 HVES1ChargeCap_8080 8080;
BA_ "SPN" SG_ 2364576755 HVES1CellBalnCt_8081 8081;
BA_ "GenSigStartValue" SG_ 2364576499 HVES1LowestCellT_8076 8736;
BA_ "SPN" SG_ 2364576499 HVES1LowestCellT_8076 8076;
BA_ "GenSigStartValue" SG_ 2364576499 HVES1HighestCellT_8075 8736;
BA_ "SPN" SG_ 2364576499 HVES1HighestCellT_8075 8075;
BA_ "SPN" SG_ 2364576499 HVES1CellTDftlSts_8078 8078;
BA_ "GenSigStartValue" SG_ 2364576499 HVES1AverageCellT_8077 8736;
BA_ "SPN" SG_ 2364576499 HVES1AverageCellT_8077 8077;
BA_ "SPN" SG_ 2364576243 HVES1LowCellVolt_5923 5923;
BA_ "SPN" SG_ 2364576243 HVES1HiCellVolt_5922 5922;
BA_ "SPN" SG_ 2364576243 HVES1FastUpdStOCh_5921 5921;
BA_ "SPN" SG_ 2364576243 HVES1CellVoltDftlSts_5924 5924;
BA_ "SPN" SG_ 2364575987 HVES1VoltageLevel_5919 5919;
BA_ "GenSigStartValue" SG_ 2364575987 HVES1Current_5920 32000;
BA_ "SPN" SG_ 2364575987 HVES1Current_5920 5920;
BA_ "SPN" SG_ 2364575987 HVES1AvlChPwr_5918 5918;
BA_ "SPN" SG_ 2364575987 HVES1AvlDchaPwr_5917 5917;
BA_ "SPN" SG_ 2558263038 PECPSC_7969 7969;
BA_ "SPN" SG_ 2558263038 PECPPS_7970 7970;
BA_ "SPN" SG_ 2558263038 PECPPH_7968 7968;
BA_ "SPN" SG_ 2558263038 PECPEC_7967 7967;
BA_ "SPN" SG_ 2558197502 PMCPPS_7982 7982;
BA_ "SPN" SG_ 2558197502 PMCPSC_7981 7981;
BA_ "SPN" SG_ 2558197502 PMCPPH_7980 7980;
BA_ "SPN" SG_ 2558197502 PMCPEC_7979 7979;
BA_ "SPN" SG_ 2558131966 PMOPPSC_7994 7994;
BA_ "SPN" SG_ 2558131966 PMOPSC_7993 7993;
BA_ "SPN" SG_ 2558131966 PMOPPH_7992 7992;
BA_ "SPN" SG_ 2558131966 PMOPEC_7991 7991;
BA_ "SPN" SG_ 2558066430 PECF1PS_8006 8006;
BA_ "SPN" SG_ 2558066430 PECF1SC_8005 8005;
BA_ "SPN" SG_ 2558066430 PECF1PH_8004 8004;
BA_ "SPN" SG_ 2558066430 PECF1EC_8003 8003;
BA_ "SPN" SG_ 2558000894 PECF2PS_8018 8018;
BA_ "SPN" SG_ 2558000894 PECF2SC_8017 8017;
BA_ "SPN" SG_ 2558000894 PECF2PH_8016 8016;
BA_ "SPN" SG_ 2558000894 PECF2EC_8015 8015;
BA_ "SPN" SG_ 2557935358 PECF3PS_8030 8030;
BA_ "SPN" SG_ 2557935358 PECF3SC_8029 8029;
BA_ "SPN" SG_ 2557935358 PECF3PH_8028 8028;
BA_ "SPN" SG_ 2557935358 PECF3EC_8027 8027;
BA_ "SPN" SG_ 2557869822 PMCF1PS_8042 8042;
BA_ "SPN" SG_ 2557869822 PMCF1SC_8041 8041;
BA_ "SPN" SG_ 2557869822 PMCF1PH_8040 8040;
BA_ "SPN" SG_ 2557869822 PMCF1EC_8039 8039;
BA_ "SPN" SG_ 2557804286 PMCF2PS_8054 8054;
BA_ "SPN" SG_ 2557804286 PMCF2SC_8053 8053;
BA_ "SPN" SG_ 2557804286 PMCF2PH_8052 8052;
BA_ "SPN" SG_ 2557804286 PMCF2EC_8051 8051;
BA_ "SPN" SG_ 2557738750 PMCF3PS_8066 8066;
BA_ "SPN" SG_ 2557738750 PMCF3SC_8065 8065;
BA_ "SPN" SG_ 2557738750 PMCF3PH_8064 8064;
BA_ "SPN" SG_ 2557738750 PMCF3EC_8063 8063;
BA_ "SPN" SG_ 2557673214 ODMFB5CC_8203 8203;
BA_ "SPN" SG_ 2557673214 ODMFB5CC_8202 8202;
BA_ "SPN" SG_ 2557673214 ODMFB5CC_8201 8201;
BA_ "SPN" SG_ 2557673214 ODMFB5CC_8200 8200;
BA_ "SPN" SG_ 2557673214 ODMFB5CC_8199 8199;
BA_ "SPN" SG_ 2557673214 ODMFB7CC_8198 8197;
BA_ "SPN" SG_ 2557673214 ODMFB6CC_8197 8197;
BA_ "SPN" SG_ 2557673214 ODMFB5CC_8196 8196;
BA_ "SPN" SG_ 2557673214 ODMFB4CC_8195 8195;
BA_ "SPN" SG_ 2557673214 ODMFB2CC_8193 8193;
BA_ "SPN" SG_ 2557673214 ODMFB3CC_8194 8194;
BA_ "SPN" SG_ 2557673214 ODMFB1CC_8192 8192;
BA_ "SPN" SG_ 2557673214 ODMCIN_8191 8191;
BA_ "SPN" SG_ 2350644979 HVES1_HVBLSRCR_8434 8434;
BA_ "SPN" SG_ 2350644979 HVES1_HVBHSRCR_8433 8433;
BA_ "SPN" SG_ 2350644979 HVES1_OC_8412 8412;
BA_ "SPN" SG_ 2350644979 HVES1_EICC_8213 8213;
BA_ "SPN" SG_ 2350644979 HVES1_CBC_8127 8127;
BA_ "SPN" SG_ 2350644979 HVES1_HVBPITC_8126 8126;
BA_ "SPN" SG_ 2350644979 HVES1_HVBAITC_8125 8125;
BA_ "SPN" SG_ 2350644979 HVES1_PDC_8124 8124;
BA_ "SPN" SG_ 2350644979 HVES1_HVBCC_8123 8123;
BA_ "SigType" SG_ 2566658558 TotalHaulCycleCount 1;
BA_ "SPN" SG_ 2566658558 TotalHaulCycleCount 7700;
BA_ "SigType" SG_ 2566658558 TotalDeliveredPayloadWeight 1;
BA_ "SPN" SG_ 2566658558 TotalDeliveredPayloadWeight 7699;
BA_ "SigType" SG_ 2566658302 TotalPayloadTransactionCount 1;
BA_ "SPN" SG_ 2566658302 TotalPayloadTransactionCount 7701;
BA_ "SPN" SG_ 2499548158 RightRearCabDoorLatchPos 7726;
BA_ "SPN" SG_ 2499548158 LeftRearCabDoorLatchPos 7725;
BA_ "SPN" SG_ 2499548158 RightFrontCabDoorLatchPos 7724;
BA_ "SPN" SG_ 2499548158 LeftFrontCabDoorLatchPos 7723;
BA_ "SigType" SG_ 2499547902 MirrorRight2HeatCmd 5;
BA_ "SPN" SG_ 2499547902 MirrorRight2HeatCmd 7744;
BA_ "SigType" SG_ 2499547902 MirrorLeft2HeatCmd 5;
BA_ "SPN" SG_ 2499547902 MirrorLeft2HeatCmd 7743;
BA_ "SigType" SG_ 2499547902 MirrorRight1HeatCmd 5;
BA_ "SPN" SG_ 2499547902 MirrorRight1HeatCmd 7742;
BA_ "SigType" SG_ 2499547902 MirrorLeft1HeatCmd 5;
BA_ "SPN" SG_ 2499547902 MirrorLeft1HeatCmd 7741;
BA_ "SigType" SG_ 2499547902 MirrorRight2VerticalCmd 5;
BA_ "SPN" SG_ 2499547902 MirrorRight2VerticalCmd 7740;
BA_ "SigType" SG_ 2499547902 MirrorRight2HorizontalCmd 5;
BA_ "SPN" SG_ 2499547902 MirrorRight2HorizontalCmd 7739;
BA_ "SigType" SG_ 2499547902 MirrorLeft2VerticalCmd 5;
BA_ "SPN" SG_ 2499547902 MirrorLeft2VerticalCmd 7738;
BA_ "SigType" SG_ 2499547902 MirrorLeft2HorizontalCmd 5;
BA_ "SPN" SG_ 2499547902 MirrorLeft2HorizontalCmd 7737;
BA_ "SigType" SG_ 2499547902 MirrorRight1VerticalCmd 5;
BA_ "SPN" SG_ 2499547902 MirrorRight1VerticalCmd 7736;
BA_ "SigType" SG_ 2499547902 MirrorRight1HorizontalCmd 5;
BA_ "SPN" SG_ 2499547902 MirrorRight1HorizontalCmd 7735;
BA_ "SigType" SG_ 2499547902 MirrorLeft1VerticalCmd 5;
BA_ "SPN" SG_ 2499547902 MirrorLeft1VerticalCmd 7734;
BA_ "SigType" SG_ 2499547902 MirrorLeft1HorizontalCmd 5;
BA_ "SPN" SG_ 2499547902 MirrorLeft1HorizontalCmd 7733;
BA_ "SPN" SG_ 2499547902 RightRearWindowPosCmd 7732;
BA_ "SPN" SG_ 2499547902 LeftRearWindowPosCmd 7731;
BA_ "SPN" SG_ 2499547902 RightFrontWindowPosCmd 7730;
BA_ "SPN" SG_ 2499547902 LeftFrontWindowPosCmd 7729;
BA_ "SPN" SG_ 2499547902 RemoteCabDoorLockReq 7728;
BA_ "SPN" SG_ 2499547902 DoorsLockActCmd 7727;
BA_ "SigType" SG_ 2566656510 EngTotalGasIdleFuelVolumeUsed 1;
BA_ "SPN" SG_ 2566656510 EngTotalGasIdleFuelVolumeUsed 7456;
BA_ "SigType" SG_ 2566656510 EngTotalGasFuelVolumeUsed 1;
BA_ "SPN" SG_ 2566656510 EngTotalGasFuelVolumeUsed 7455;
BA_ "SPN" SG_ 2431710718 Checksum 7758;
BA_ "SPN" SG_ 2431710718 MessageCounter 7757;
BA_ "SigType" SG_ 2431710718 AutomaticEngStartConsentSummary 5;
BA_ "SPN" SG_ 2431710718 AutomaticEngStartConsentSummary 7756;
BA_ "SigType" SG_ 2431710718 OpEngStartConsentSummary 5;
BA_ "SPN" SG_ 2431710718 OpEngStartConsentSummary 7755;
BA_ "SPN" SG_ 2431710718 ReqLatchStatus 7754;
BA_ "SPN" SG_ 2431710718 StarterCmd 7753;
BA_ "SigType" SG_ 2431710718 CtrlMessageRate 5;
BA_ "SPN" SG_ 2431710718 CtrlMessageRate 7752;
BA_ "SPN" SG_ 2431708670 Checksum 7751;
BA_ "SPN" SG_ 2431708670 MessageCounter 7750;
BA_ "SPN" SG_ 2431708670 Starter2Feedback 7749;
BA_ "SPN" SG_ 2431708670 Starter1Feedback 7748;
BA_ "SigType" SG_ 2431708670 AbortReq 5;
BA_ "SPN" SG_ 2431708670 AbortReq 7747;
BA_ "SPN" SG_ 2431708670 Consent 7746;
BA_ "SigType" SG_ 2431708670 Req 5;
BA_ "SPN" SG_ 2431708670 Req 7745;
BA_ "SigType" SG_ 2566661118 EngTotalDieselFuelDemand 1;
BA_ "SPN" SG_ 2566661118 EngTotalDieselFuelDemand 7597;
BA_ "SigType" SG_ 2633769726 TotalEngEnergy 1;
BA_ "SPN" SG_ 2633769726 TotalEngEnergy 7608;
BA_ "SPN" SG_ 2565926142 O2Snsr2PreliminaryFMI 7692;
BA_ "SPN" SG_ 2565926142 NOxSnsr2SelfDiagStatus 7691;
BA_ "SPN" SG_ 2565926142 NOxSnsr2PreliminaryFMI 7690;
BA_ "SigType" SG_ 2565926142 GasSnsr2HtrCtrl 5;
BA_ "SPN" SG_ 2565926142 GasSnsr2HtrCtrl 7689;
BA_ "SPN" SG_ 2565926142 GasSnsr2HtrPreliminaryFMI 7688;
BA_ "SigType" SG_ 2565926142 WRPercentO22ReadingStable 5;
BA_ "SPN" SG_ 2565926142 WRPercentO22ReadingStable 7687;
BA_ "SigType" SG_ 2565926142 NOx2ReadingStable 5;
BA_ "SPN" SG_ 2565926142 NOx2ReadingStable 7686;
BA_ "SigType" SG_ 2565926142 GasSnsr2AtTemp 5;
BA_ "SPN" SG_ 2565926142 GasSnsr2AtTemp 7685;
BA_ "SigType" SG_ 2565926142 GasSnsr2PwrInRange 5;
BA_ "SPN" SG_ 2565926142 GasSnsr2PwrInRange 7684;
BA_ "SigType" SG_ 2565926142 PercentO22 1;
BA_ "SPN" SG_ 2565926142 PercentO22 7683;
BA_ "SigType" SG_ 2565926142 NOx2 1;
BA_ "SPN" SG_ 2565926142 NOx2 7682;
BA_ "SPN" SG_ 2565925886 O2Snsr2PreliminaryFMI 7681;
BA_ "SPN" SG_ 2565925886 NOxSnsr2SelfDiagStatus 7680;
BA_ "SPN" SG_ 2565925886 SCRInNOxSnsr2PreliminaryFMI 7679;
BA_ "SigType" SG_ 2565925886 GasSnsr2HtrCtrl 5;
BA_ "SPN" SG_ 2565925886 GasSnsr2HtrCtrl 7678;
BA_ "SPN" SG_ 2565925886 GasSnsr2HtrPreliminaryFMI 7677;
BA_ "SigType" SG_ 2565925886 WRPercentO22ReadingStable 5;
BA_ "SPN" SG_ 2565925886 WRPercentO22ReadingStable 7676;
BA_ "SigType" SG_ 2565925886 SCRInNOx2ReadingStable 5;
BA_ "SPN" SG_ 2565925886 SCRInNOx2ReadingStable 7675;
BA_ "SigType" SG_ 2565925886 GasSnsr2AtTemp 5;
BA_ "SPN" SG_ 2565925886 GasSnsr2AtTemp 7674;
BA_ "SigType" SG_ 2565925886 GasSnsr2PwrInRange 5;
BA_ "SPN" SG_ 2565925886 GasSnsr2PwrInRange 7673;
BA_ "SigType" SG_ 2565925886 PercentO22 1;
BA_ "SPN" SG_ 2565925886 PercentO22 7672;
BA_ "SigType" SG_ 2565925886 SCRInNOx2 1;
BA_ "SPN" SG_ 2565925886 SCRInNOx2 7671;
BA_ "SPN" SG_ 2565925630 O2Snsr2PreliminaryFMI 7670;
BA_ "SPN" SG_ 2565925630 NOxSnsr2SelfDiagStatus 7669;
BA_ "SPN" SG_ 2565925630 NOxSnsr2PreliminaryFMI 7668;
BA_ "SigType" SG_ 2565925630 Snsr2HtrCtrl 5;
BA_ "SPN" SG_ 2565925630 Snsr2HtrCtrl 7667;
BA_ "SPN" SG_ 2565925630 Snsr2HtrPreliminaryFMI 7666;
BA_ "SigType" SG_ 2565925630 WRPercentO22ReadingStable 5;
BA_ "SPN" SG_ 2565925630 WRPercentO22ReadingStable 7665;
BA_ "SigType" SG_ 2565925630 NOx2ReadingStable 5;
BA_ "SPN" SG_ 2565925630 NOx2ReadingStable 7664;
BA_ "SigType" SG_ 2565925630 Snsr2AtTemp 5;
BA_ "SPN" SG_ 2565925630 Snsr2AtTemp 7663;
BA_ "SigType" SG_ 2565925630 Snsr2PwrInRange 5;
BA_ "SPN" SG_ 2565925630 Snsr2PwrInRange 7662;
BA_ "SigType" SG_ 2565925630 PercentO22 1;
BA_ "SPN" SG_ 2565925630 PercentO22 7661;
BA_ "SigType" SG_ 2565925630 NOx2 1;
BA_ "SPN" SG_ 2565925630 NOx2 7660;
BA_ "SPN" SG_ 2565925374 O2Snsr2PreliminaryFMI 7659;
BA_ "SPN" SG_ 2565925374 NOxSnsr2SelfDiagStatus 7658;
BA_ "SPN" SG_ 2565925374 SCRInNOxSnsr2PreliminaryFMI 7657;
BA_ "SigType" SG_ 2565925374 Snsr2HtrCtrl 5;
BA_ "SPN" SG_ 2565925374 Snsr2HtrCtrl 7656;
BA_ "SPN" SG_ 2565925374 Snsr2HtrPreliminaryFMI 7655;
BA_ "SigType" SG_ 2565925374 WRPercentO22ReadingStable 5;
BA_ "SPN" SG_ 2565925374 WRPercentO22ReadingStable 7654;
BA_ "SigType" SG_ 2565925374 SCRInNOx2ReadingStable 5;
BA_ "SPN" SG_ 2565925374 SCRInNOx2ReadingStable 7653;
BA_ "SigType" SG_ 2565925374 Snsr2AtTemp 5;
BA_ "SPN" SG_ 2565925374 Snsr2AtTemp 7652;
BA_ "SigType" SG_ 2565925374 Snsr2PwrInRange 5;
BA_ "SPN" SG_ 2565925374 Snsr2PwrInRange 7651;
BA_ "SigType" SG_ 2565925374 PercentO22 1;
BA_ "SPN" SG_ 2565925374 PercentO22 7650;
BA_ "SigType" SG_ 2565925374 SCRInNOx2 1;
BA_ "SPN" SG_ 2565925374 SCRInNOx2 7649;
BA_ "SigType" SG_ 2364598526 FuelAct4CtrlCmd 1;
BA_ "SPN" SG_ 2364598526 FuelAct4CtrlCmd 7594;
BA_ "SigType" SG_ 2364598526 FuelAct3CtrlCmd 1;
BA_ "SPN" SG_ 2364598526 FuelAct3CtrlCmd 7593;
BA_ "SigType" SG_ 2558525182 Num7586 8;
BA_ "SPN" SG_ 2558525182 Num7586 7586;
BA_ "SPN" SG_ 2558525182 Location_7585 7585;
BA_ "SigType" SG_ 2558525182 Num_7584 1;
BA_ "SPN" SG_ 2558525182 Num_7584 7584;
BA_ "SigType" SG_ 2558525182 NumOfTireSensors_7583 1;
BA_ "SPN" SG_ 2558525182 NumOfTireSensors_7583 7583;
BA_ "SigType" SG_ 2350841598 TrqRampMaxSpdCmd 1;
BA_ "SPN" SG_ 2350841598 TrqRampMaxSpdCmd 7592;
BA_ "SigType" SG_ 2350841598 TrqRampTimeCmd 1;
BA_ "GenSigStartValue" SG_ 2350841598 TrqRampTimeCmd 1;
BA_ "SPN" SG_ 2350841598 TrqRampTimeCmd 7591;
BA_ "SigType" SG_ 2350841598 ExcitationMaxCurrentLmt 1;
BA_ "SPN" SG_ 2350841598 ExcitationMaxCurrentLmt 7590;
BA_ "SigType" SG_ 2350841598 SetpointVoltageCmd 1;
BA_ "SPN" SG_ 2350841598 SetpointVoltageCmd 7589;
BA_ "SigType" SG_ 2566838014 ShutdownSw 4;
BA_ "SPN" SG_ 2566838014 ShutdownSw 7555;
BA_ "SigType" SG_ 2566838014 PropulsionDisableSw 4;
BA_ "SPN" SG_ 2566838014 PropulsionDisableSw 7554;
BA_ "SigType" SG_ 2566838014 HybrdSystmCstngRgnrtvBrkngLvlSlc 1;
BA_ "SPN" SG_ 2566838014 HybrdSystmCstngRgnrtvBrkngLvlSlc 7556;
BA_ "SigType" SG_ 2566838014 HybrdSystmBrkPdlRgnrtvBrkngDsblS 4;
BA_ "SPN" SG_ 2566838014 HybrdSystmBrkPdlRgnrtvBrkngDsblS 7553;
BA_ "SigType" SG_ 2566838014 HybrdSystmRgnrtvBrkngDsbleSwitch 4;
BA_ "SPN" SG_ 2566838014 HybrdSystmRgnrtvBrkngDsbleSwitch 7552;
BA_ "SigType" SG_ 2566838014 HybrdSystmOffBrdChrgrCnnctnSttus 4;
BA_ "SPN" SG_ 2566838014 HybrdSystmOffBrdChrgrCnnctnSttus 7551;
BA_ "SigType" SG_ 2566838014 HybrdSystmPwrElctrncsClntLvlSwtc 4;
BA_ "SPN" SG_ 2566838014 HybrdSystmPwrElctrncsClntLvlSwtc 7550;
BA_ "SigType" SG_ 2566838014 HybrdSystmPrplsnClantLevelSwitch 4;
BA_ "SPN" SG_ 2566838014 HybrdSystmPrplsnClantLevelSwitch 7549;
BA_ "SigType" SG_ 2566838014 HybrdSystmPrtctionOverrideSwitch 4;
BA_ "SPN" SG_ 2566838014 HybrdSystmPrtctionOverrideSwitch 7548;
BA_ "SigType" SG_ 2566761726 EngIdleFuelFlowRateThreshold 1;
BA_ "SPN" SG_ 2566761726 EngIdleFuelFlowRateThreshold 2778;
BA_ "SigType" SG_ 2566761726 NmbrOfFlCnsmptnMntrngTransducers 1;
BA_ "SPN" SG_ 2566761726 NmbrOfFlCnsmptnMntrngTransducers 2777;
BA_ "SigType" SG_ 2566756350 EngFuelReturnTemp 1;
BA_ "SPN" SG_ 2566756350 EngFuelReturnTemp 2776;
BA_ "SigType" SG_ 2566756350 EngFuelSupplyTemp 1;
BA_ "SPN" SG_ 2566756350 EngFuelSupplyTemp 2775;
BA_ "SigType" SG_ 2566756094 EngFuelReturnFlowRate 1;
BA_ "SPN" SG_ 2566756094 EngFuelReturnFlowRate 2774;
BA_ "SigType" SG_ 2566756094 EngFuelSupplyFlowRate 1;
BA_ "SPN" SG_ 2566756094 EngFuelSupplyFlowRate 2773;
BA_ "SigType" SG_ 2566687998 TimeBetweenRegens 1;
BA_ "SPN" SG_ 2566687998 TimeBetweenRegens 6776;
BA_ "SigType" SG_ 2566687998 ActiveAccumulationTime 1;
BA_ "SPN" SG_ 2566687998 ActiveAccumulationTime 6775;
BA_ "SPN" SG_ 2566687998 RegenSt 6774;
BA_ "SigType" SG_ 2566687998 RegenStatus 5;
BA_ "SPN" SG_ 2566687998 RegenStatus 6773;
BA_ "SigType" SG_ 2566687998 HtrSt 5;
BA_ "SPN" SG_ 2566687998 HtrSt 6772;
BA_ "SigType" SG_ 2566687998 Res 1;
BA_ "SPN" SG_ 2566687998 Res 6771;
BA_ "SigType" SG_ 2566687742 HtrRes 1;
BA_ "SPN" SG_ 2566687742 HtrRes 7070;
BA_ "SigType" SG_ 2566687742 MaxRes 1;
BA_ "SPN" SG_ 2566687742 MaxRes 6781;
BA_ "SigType" SG_ 2566687742 Temp 1;
BA_ "SPN" SG_ 2566687742 Temp 6780;
BA_ "SigType" SG_ 2566687742 RegenFailedCount 1;
BA_ "SPN" SG_ 2566687742 RegenFailedCount 6779;
BA_ "SigType" SG_ 2566687742 PwrSupply 4;
BA_ "SPN" SG_ 2566687742 PwrSupply 6778;
BA_ "SPN" SG_ 2566687742 DetectionStatus 6777;
BA_ "SPN" SG_ 2365348350 EngLoadShareStatus 6794;
BA_ "SigType" SG_ 2365348350 EngUnloadStatus 4;
BA_ "SPN" SG_ 2365348350 EngUnloadStatus 6793;
BA_ "SigType" SG_ 2566674686 EngTurbo4LubeOilPress 1;
BA_ "SPN" SG_ 2566674686 EngTurbo4LubeOilPress 6813;
BA_ "SigType" SG_ 2566674686 EngTurbo3LubeOilPress 1;
BA_ "SPN" SG_ 2566674686 EngTurbo3LubeOilPress 6812;
BA_ "SigType" SG_ 2566674686 EngTurbo2LubeOilPress 1;
BA_ "SPN" SG_ 2566674686 EngTurbo2LubeOilPress 6811;
BA_ "SigType" SG_ 2566674430 DslExhstFldQalityMalfunctionTime 1;
BA_ "SPN" SG_ 2566674430 DslExhstFldQalityMalfunctionTime 6818;
BA_ "SigType" SG_ 2566674430 DieselExhaustFluidTank1EmptyTime 1;
BA_ "SPN" SG_ 2566674430 DieselExhaustFluidTank1EmptyTime 6817;
BA_ "SigType" SG_ 2566674174 SCROperatorInducementTotalTime 1;
BA_ "SPN" SG_ 2566674174 SCROperatorInducementTotalTime 7095;
BA_ "SigType" SG_ 2566674174 AFTSCRMalfunctionTime 1;
BA_ "SPN" SG_ 2566674174 AFTSCRMalfunctionTime 6819;
BA_ "SigType" SG_ 2566673406 GasLeakageDetection3Press 1;
BA_ "SPN" SG_ 2566673406 GasLeakageDetection3Press 6839;
BA_ "SigType" SG_ 2566673406 GasLeakageDetection2Press 1;
BA_ "SPN" SG_ 2566673406 GasLeakageDetection2Press 6838;
BA_ "SigType" SG_ 2566673406 GasLeakageDetection1Press 1;
BA_ "SPN" SG_ 2566673406 GasLeakageDetection1Press 6837;
BA_ "SigType" SG_ 2566673406 GasFuelLeakage3Concentration 1;
BA_ "SPN" SG_ 2566673406 GasFuelLeakage3Concentration 6836;
BA_ "SigType" SG_ 2566673406 GasFuelLeakage2Concentration 1;
BA_ "SPN" SG_ 2566673406 GasFuelLeakage2Concentration 6835;
BA_ "SigType" SG_ 2566673406 GasFuelLeakage1Concentration 1;
BA_ "SPN" SG_ 2566673406 GasFuelLeakage1Concentration 6834;
BA_ "SigType" SG_ 2633782014 NetBinWeight 1;
BA_ "SPN" SG_ 2633782014 NetBinWeight 6841;
BA_ "SigType" SG_ 2633782014 BinLiftCount 1;
BA_ "SPN" SG_ 2633782014 BinLiftCount 6840;
BA_ "SPN" SG_ 2633782014 BinWeighingErrorStatus 6842;
BA_ "SPN" SG_ 2633782014 BinInstance 6845;
BA_ "SPN" SG_ 2365346302 LiftAxle2Status 6844;
BA_ "SPN" SG_ 2365346302 LiftAxle1Status 6843;
BA_ "SPN" SG_ 2566672638 DeliveryTransactionStatus 7702;
BA_ "SigType" SG_ 2566672638 DeliveredPayloadConfidence 1;
BA_ "SPN" SG_ 2566672638 DeliveredPayloadConfidence 6850;
BA_ "SPN" SG_ 2566672638 DeliveredPayloadWeight 6849;
BA_ "SPN" SG_ 2566672638 HaulModeStatus 6848;
BA_ "SigType" SG_ 2566672638 HaulCycleCount 1;
BA_ "SPN" SG_ 2566672638 HaulCycleCount 6847;
BA_ "SigType" SG_ 2566672382 PayloadWeightSensor8Status 5;
BA_ "SPN" SG_ 2566672382 PayloadWeightSensor8Status 6862;
BA_ "SigType" SG_ 2566672382 PayloadWeightSensor7Status 5;
BA_ "SPN" SG_ 2566672382 PayloadWeightSensor7Status 6861;
BA_ "SigType" SG_ 2566672382 PayloadWeightSensor6Status 5;
BA_ "SPN" SG_ 2566672382 PayloadWeightSensor6Status 6860;
BA_ "SigType" SG_ 2566672382 PayloadWeightSensor5Status 5;
BA_ "SPN" SG_ 2566672382 PayloadWeightSensor5Status 6859;
BA_ "SigType" SG_ 2566672382 PayloadWeightSensor4Status 5;
BA_ "SPN" SG_ 2566672382 PayloadWeightSensor4Status 6858;
BA_ "SigType" SG_ 2566672382 PayloadWeightSensor3Status 5;
BA_ "SPN" SG_ 2566672382 PayloadWeightSensor3Status 6857;
BA_ "SigType" SG_ 2566672382 PayloadWeightSensor2Status 5;
BA_ "SPN" SG_ 2566672382 PayloadWeightSensor2Status 6856;
BA_ "SigType" SG_ 2566672382 PayloadWeightSensor1Status 5;
BA_ "SPN" SG_ 2566672382 PayloadWeightSensor1Status 6855;
BA_ "SigType" SG_ 2566672126 DEFDoser2Temp 1;
BA_ "SPN" SG_ 2566672126 DEFDoser2Temp 7460;
BA_ "SigType" SG_ 2566672126 DEFDoser2AbsPress 1;
BA_ "SPN" SG_ 2566672126 DEFDoser2AbsPress 7459;
BA_ "SigType" SG_ 2566672126 DEFDosingPress 1;
BA_ "SPN" SG_ 2566672126 DEFDosingPress 6875;
BA_ "SigType" SG_ 2566671870 DEFDosing2Temp 1;
BA_ "SPN" SG_ 2566671870 DEFDosing2Temp 7465;
BA_ "SigType" SG_ 2566671870 DEFDoser2AbsPress 1;
BA_ "SPN" SG_ 2566671870 DEFDoser2AbsPress 7464;
BA_ "SigType" SG_ 2566671870 DEFDosingPress 1;
BA_ "SPN" SG_ 2566671870 DEFDosingPress 6876;
BA_ "SigType" SG_ 2566671614 TtlNmbrOfSCROprtrIndcmntOvrrdEvn 1;
BA_ "SPN" SG_ 2566671614 TtlNmbrOfSCROprtrIndcmntOvrrdEvn 6880;
BA_ "SigType" SG_ 2566671614 NmbrOfSCROprtrIndcmntOvrrdEvntsR 1;
BA_ "SPN" SG_ 2566671614 NmbrOfSCROprtrIndcmntOvrrdEvntsR 6879;
BA_ "SigType" SG_ 2566671614 SCROprtrIndcmntOvrrdTmeRemaining 1;
BA_ "SPN" SG_ 2566671614 SCROprtrIndcmntOvrrdTmeRemaining 6878;
BA_ "SigType" SG_ 2566671614 SCROprtrInducementOverrideEnable 5;
BA_ "SPN" SG_ 2566671614 SCROprtrInducementOverrideEnable 6877;
BA_ "SigType" SG_ 2566671358 CylFuelRate 1;
BA_ "SPN" SG_ 2566671358 CylFuelRate 7333;
BA_ "SigType" SG_ 2566671358 EngExhaustFlowRate 1;
BA_ "SPN" SG_ 2566671358 EngExhaustFlowRate 6895;
BA_ "SigType" SG_ 2566671358 VehicleFuelRate 1;
BA_ "SPN" SG_ 2566671358 VehicleFuelRate 6894;
BA_ "SigType" SG_ 2566671358 PEMSEngFuelMassFlowRate 1;
BA_ "SPN" SG_ 2566671358 PEMSEngFuelMassFlowRate 6893;
VAL_ 3221225472 TirePressThresholdDetection 7 "Not available" 6 "Error indicator" 5 "Not defined" 4 "Extreme under pressure" 3 "Under pressure" 2 "No warning pressure" 1 "Over pressure" 0 "Extreme over pressure" ;
VAL_ 3221225472 CTIWheelEndElectricalFault 3 "Not Supported" 2 "Error" 1 "Not Defined" 0 "Ok  No Fault" ;
VAL_ 3221225472 CTITireStatus 3 "Not Supported" 2 "Error" 1 "Tire leak detected" 0 "Ok no fault" ;
VAL_ 3221225472 CTIWheelSensorStatus 3 "Not Supported" 2 "Not Defined" 1 "On tire is polled" 0 "Off / isolated from CTI Pressure Controller" ;
VAL_ 3221225472 EngTurningGearEngaged 1 "Engaged" 0 "Not engaged" 3 "Not available" 2 "Error" ;
VAL_ 2364606707 HVES1M11OperlSts_8224 3 "Not Available" 2 "Error" 1 "Operational" 0 "Not Operational" ;
VAL_ 2364606707 HVES1M9OperlSts_8222 3 "Not Available" 2 "Error" 1 "Operational" 0 "Not Operational" ;
VAL_ 2364606707 HVES1M8OperlSts_8221 3 "Not Available" 2 "Error" 1 "Operational" 0 "Not Operational" ;
VAL_ 2364606707 HVES1M7OperlSts_8220 3 "Not Available" 2 "Error" 1 "Operational" 0 "Not Operational" ;
VAL_ 2364606707 HVES1M6OperlSts_8219 3 "Not Available" 2 "Error" 1 "Operational" 0 "Not Operational" ;
VAL_ 2364606707 HVES1M5OperlSts_8218 3 "Not Available" 2 "Error" 1 "Operational" 0 "Not Operational" ;
VAL_ 2364606707 HVES1M4OperlSts_8217 3 "Not Available" 2 "Error" 1 "Operational" 0 "Not Operational" ;
VAL_ 2364606707 HVES1M3OperlSts_8216 3 "Not Available" 2 "Error" 1 "Operational" 0 "Not Operational" ;
VAL_ 2364606707 HVES1M2OperlSts_8215 3 "Not Available" 2 "Error" 1 "Operational" 0 "Not Operational" ;
VAL_ 2364606707 HVES1M1OperlSts_8214 3 "Not Available" 2 "Error" 1 "Operational" 0 "Not Operational" ;
VAL_ 2364606707 HVES1M16OperlSts_8229 3 "Not Available" 2 "Error" 1 "Operational" 0 "Not Operational" ;
VAL_ 2364606707 HVES1M15OperlSts_8228 3 "Not Available" 2 "Error" 1 "Operational" 0 "Not Operational" ;
VAL_ 2364606707 HVES1M14OperlSts_8227 3 "Not Available" 2 "Error" 1 "Operational" 0 "Not Operational" ;
VAL_ 2364606707 HVES1M13OperlSts_8226 3 "Not Available" 2 "Error" 1 "Operational" 0 "Not Operational" ;
VAL_ 2364606707 HVES1M12OperlSts_8225 3 "Not Available" 2 "Error" 1 "Operational" 0 "Not Operational" ;
VAL_ 2364606707 HVES1M10OperlSts_8223 3 "Not Available" 2 "Error" 1 "Operational" 0 "Not Operational" ;
VAL_ 2364552947 HVES1CPLDToUndefCause_8114 3 "Not Available" 2 "Error" 1 "Power limited for this reason" 0 "Now power limit for this reason" ;
VAL_ 2364552947 HVES1CPLDTBT_8110 3 "Not Available" 2 "Error" 1 "Power limited for this reason" 0 "Now power limit for this reason" ;
VAL_ 2364552947 HVES1CPLDTBOrCellV_8112 3 "Not Available" 2 "Error" 1 "Power limited for this reason" 0 "Now power limit for this reason" ;
VAL_ 2364552947 HVES1CPLDTBDiagcCdn_8111 3 "Not Available" 2 "Error" 1 "Power limited for this reason" 0 "Now power limit for this reason" ;
VAL_ 2364552947 HVES1CPLDTBCur_8113 3 "Not Available" 2 "Error" 1 "Power limited for this reason" 0 "Now power limit for this reason" ;
VAL_ 2364552947 HVES1DPLDTStOfCha_8109 3 "Not Available" 2 "Error" 1 "Power limited for this reason" 0 "Now power limit for this reason" ;
VAL_ 2364552947 HVES1DPLDTStOfCha_8103 3 "Not Available" 2 "Error" 1 "Power limited for this reason" 0 "Now power limit for this reason" ;
VAL_ 2364552947 HVES1DPLDToUndefCause_8108 3 "Not Available" 2 "Error" 1 "Power limited for this reason" 0 "Now power limit for this reason" ;
VAL_ 2364552947 HVES1DPLDTBT_8104 3 "Not Available" 2 "Error" 1 "Power limited for this reason" 0 "Now power limit for this reason" ;
VAL_ 2364552947 HVES1DPLDTBOrCellV_8106 3 "Not Available" 2 "Error" 1 "Power limited for this reason" 0 "Now power limit for this reason" ;
VAL_ 2364552947 HVES1DPLDTBDiagcCdn_8105 3 "Not Available" 2 "Error" 1 "Power limited for this reason" 0 "Now power limit for this reason" ;
VAL_ 2364552947 HVES1DPLDTBCur_8107 3 "Not Available" 2 "Error" 1 "Power limited for this reason" 0 "Now power limit for this reason" ;
VAL_ 2364606963 HVES1TMSMode_8235 15 "Not Available" 14 "Error" 13 "Reserved" 12 "Reserved" 11 "Reserved" 10 "Reserved" 9 "Reserved" 8 "Reserved" 7 "Reserved" 6 "Reserved" 5 "Reserved" 4 "Drying" 3 "Heating" 2 "Cooling" 1 "Circulating" 0 "Off" ;
VAL_ 2364606963 HVES1TMSHeatrSts_8234 3 "Description for the value '3'" 2 "Error" 1 "Heater On" 0 "Heater Off" ;
VAL_ 2364577523 HVES1StOfChaSts_8100 15 "Description for the value '15'" 14 "Error" 13 "Reserved" 12 "Reserved" 11 "Reserved" 10 "Reserved" 9 "Reserved" 8 "Reserved" 7 "Reserved" 6 "SOC above recommended up lim" 5 "SOC at its recommended up lim" 4 " SOC approach recommend up lim" 3 "SOC below recommended low lim
" 2 "SOC at its recommended lower lim" 1 "SOC approach recommend low lim
" 0 "SOC level is acceptable" ;
VAL_ 2364577523 HVES1OperationlSts_8414 15 "Not Available" 14 "Error" 13 "Reserved" 12 "Reserved" 11 "Reserved" 10 "Reserved" 9 "Reserved" 8 "Reserved" 7 "Reserved" 6 "Disabled by int dec of HVES" 5 "Disabled by ext cmd. HVES non-op" 4 "Emergency Pwr-dwn in proc" 3 "Norm Pwr-dwn in proc." 2 "Operational" 1 " Init Complete, waiting consent" 0 "Init in proc, HVES powering up" ;
VAL_ 2364577523 HVES1IntChaSts_8207 3 "Not Available" 2 "Error" 1 "Charging on" 0 "Charging off" ;
VAL_ 2364577523 HVES1InertiaSwtSts_8099 3 "Description for the value '3'" 2 "Error" 1 "Impact sensed" 0 "No impact sensed" ;
VAL_ 2364577523 HVES1HVILSts_8098 3 "Not Available" 2 "Error" 1 "HVIL Open" 0 "HVIL Closed" ;
VAL_ 2364577523 HVES1HVBusPsvIsoTstSts_8097 15 "Description for the value '15'" 14 "Error" 13 "Reserved" 12 "Reserved" 11 "Reserved" 10 "Reserved" 9 "Reserved" 8 "Reserved" 7 "Reserved" 6 "Reserved" 5 "Test complete; isolation fault
" 4 " Test complete; isolat marginal" 3 "Test complete; isolation accept" 2 " Test in process
" 1 "Test requested but not in proc" 0 "No test requested or in process" ;
VAL_ 2364577523 HVES1HVBusPrechaRlySt_8094 3 "Not Available" 2 "Error" 1 "Relay Closed" 0 "Relay Open" ;
VAL_ 2364577523 HVES1HVBusDiscnctWarn_8093 16 "Description for the value '16'" 15 "Not Available" 14 "Error" 13 "Dis imminent - no reason given" 12 "Reserved" 11 "Reserved" 10 "Reserved" 9 "Reserved" 8 "Reserved" 7 "Dis imminent bp cur appro min" 6 "Dis imminent-cell V appr max" 5 "Dis imminent-cell V appr min" 4 "Dis imminent-mod V appr max" 3 "Discnct imminent-mod V appr min" 2 "Discnct imminent-bp V appr max" 1 "Discnct imminent-bp V appr min" 0 "Disconnect not pending" ;
VAL_ 2364577523 HVES1HVBusCnctnSts_8413 15 "Not Available" 14 "Error" 13 "Reserved" 12 "Reserved" 11 "Reserved" 10 "Reserved" 9 "Reserved" 8 "Reserved" 7 "Reserved" 6 "Reserved" 5 "Reserved" 4 "Disconnected; Precharge Failed" 3 "Disconnection in Process" 2 "Connection in Process" 1 "Connected.  contractors closed" 0 "Disconnected.  contactors open." ;
VAL_ 2364577523 HVES1HVBusAcvIsoTstSts_8096 15 "Description for the value '15'" 14 "Error" 13 "Reserved" 12 "Reserved" 11 "Reserved" 10 "Reserved" 9 "Reserved" 8 "Reserved" 7 "Reserved" 6 "Reserved" 5 "Test complete; isolation fault
" 4 " Test complete; isolat marginal" 3 "Test complete; isolation accept" 2 " Test in process
" 1 "Test requested but not in proc" 0 "No test requested or in process" ;
VAL_ 2364577523 HVES1HVBCtorStPos_8091 3 "Not Available" 2 "Error" 1 "Contractor Closed" 0 "Contractor Open" ;
VAL_ 2364577523 HVES1HVBCtorStNeg_8092 3 "Not Available" 2 "Error" 1 "Contractor Closed" 0 "Contractor Open" ;
VAL_ 2364577523 HVES1CtrOfPackCtorSt_8095 3 "Description for the value '3'" 2 "Error" 1 "Contractor Closed" 0 "Contractor Open" ;
VAL_ 2364577523 HVES1CellBalnSts_8101 3 "Not Available" 2 "Error" 1 "Cells are unbalanced" 0 "Cells are balanced" ;
VAL_ 2364577523 HVES1CellBalnAcv_8102 3 "Not Available" 2 "Error" 1 "Cell balancing is active
" 0 "Cell balancing is not active
" ;
VAL_ 2364576499 HVES1CellTDftlSts_8078 3 "Description for the value '3'" 2 "Error" 1 "T dftl exceeds acceptable lmts" 0 "T dftl within acceptable lmts" ;
VAL_ 2364576243 HVES1CellVoltDftlSts_5924 15 "Description for the value '15'" 14 "Error" 13 "Reserved" 12 "Reserved" 11 "Reserved" 10 "Reserved" 9 "Reserved" 8 "Reserved" 7 "Reserved" 6 "Reserved" 5 "Reserved" 4 "exc lim - restorability unknown" 3 "exceeds limits - can't restore" 2 "exceeds limits - maint bal reqd" 1 "exceeds limits but correctable" 0 "within acceptable limits" ;
VAL_ 2499548158 RightRearCabDoorLatchPos 7 "Not Available" 6 "Error" 5 "Reserved" 4 "Reserved" 3 "Reserved" 2 "Door Latch Ajar" 1 "Door Latch Fully Closed/Latched" 0 "Door Latch Open" ;
VAL_ 2499548158 LeftRearCabDoorLatchPos 7 "Not Available" 6 "Error" 5 "Reserved" 4 "Reserved" 3 "Reserved" 2 "Door Latch Ajar" 1 "Door Latch Fully Closed/Latched" 0 "Door Latch Open" ;
VAL_ 2499548158 RightFrontCabDoorLatchPos 7 "Not Available" 6 "Error" 5 "Reserved" 4 "Reserved" 3 "Reserved" 2 "Door Latch Ajar" 1 "Door Latch Fully Closed/Latched" 0 "Door Latch Open" ;
VAL_ 2499548158 LeftFrontCabDoorLatchPos 7 "Not Available" 6 "Error" 5 "Reserved" 4 "Reserved" 3 "Reserved" 2 "Door Latch Ajar" 1 "Door Latch Fully Closed/Latched" 0 "Door Latch Open" ;
VAL_ 2499547902 MirrorRight2HeatCmd 3 "Take no action" 2 "Reserved" 1 "Mirror heat on" 0 "Mirror heat off" ;
VAL_ 2499547902 MirrorLeft2HeatCmd 3 "Take no action" 2 "Reserved" 1 "Mirror heat on" 0 "Mirror heat off" ;
VAL_ 2499547902 MirrorRight1HeatCmd 3 "Take no action" 2 "Reserved" 1 "Mirror heat on" 0 "Mirror heat off" ;
VAL_ 2499547902 MirrorLeft1HeatCmd 3 "Take no action" 2 "Reserved" 1 "Mirror heat on" 0 "Mirror heat off" ;
VAL_ 2499547902 MirrorRight2VerticalCmd 3 "Take no action" 2 "Reserved" 1 "Move down" 0 "Move up" ;
VAL_ 2499547902 MirrorRight2HorizontalCmd 3 "Take no action" 2 "Reserved" 1 "Move right" 0 "Move left" ;
VAL_ 2499547902 MirrorLeft2VerticalCmd 3 "Take no action" 2 "Reserved" 1 "Move down" 0 "Move up" ;
VAL_ 2499547902 MirrorLeft2HorizontalCmd 3 "Take no action" 2 "Reserved" 1 "Move right" 0 "Move left" ;
VAL_ 2499547902 MirrorRight1VerticalCmd 3 "Take no action" 2 "Reserved" 1 "Move down" 0 "Move up" ;
VAL_ 2499547902 MirrorRight1HorizontalCmd 3 "Take no action" 2 "Reserved" 1 "Move right" 0 "Move left" ;
VAL_ 2499547902 MirrorLeft1VerticalCmd 3 "Take no action" 2 "Reserved" 1 "Move down" 0 "Move up" ;
VAL_ 2499547902 MirrorLeft1HorizontalCmd 3 "Take no action" 2 "Reserved" 1 "Move right" 0 "Move left" ;
VAL_ 2499547902 RightRearWindowPosCmd 7 "Take no action" 6 "Reserved" 5 "Reserved" 4 "Reserved" 3 "Window auto down" 2 "Window auto up" 1 "Window move down" 0 "Window move up" ;
VAL_ 2499547902 LeftRearWindowPosCmd 7 "Take no action" 6 "Reserved" 5 "Reserved" 4 "Reserved" 3 "Window auto down" 2 "Window auto up" 1 "Window move down" 0 "Window move up" ;
VAL_ 2499547902 RightFrontWindowPosCmd 7 "Take no action" 6 "Reserved" 5 "Reserved" 4 "Reserved" 3 "Window auto down" 2 "Window auto up" 1 "Window move down" 0 "Window move up" ;
VAL_ 2499547902 LeftFrontWindowPosCmd 7 "Take no action" 6 "Reserved" 5 "Reserved" 4 "Reserved" 3 "Window auto down" 2 "Window auto up" 1 "Window move down" 0 "Window move up" ;
VAL_ 2499547902 RemoteCabDoorLockReq 7 "Take no action" 6 "Reserved" 5 "Request lock all cab door latches" 4 "Request unlock all cab door latches" 3 "Request unlock right rear cab door latch" 2 "Request unlock left rear cab door latch" 1 "Request unlock right front cab door latch" 0 "Request unlock left front cab door latch" ;
VAL_ 2499547902 DoorsLockActCmd 7 "Take no action" 6 "Reserved" 5 "Lock all cab door latches" 4 "Unlock all cab door latches" 3 "Unlock right rear cab door latch" 2 "Unlock left rear cab door latch" 1 "Unlock right front cab door latch" 0 "Unlock left front cab door latch" ;
VAL_ 2431710718 AutomaticEngStartConsentSummary 3 "Not available" 2 "Error" 1 "Consent" 0 "No consent" ;
VAL_ 2431710718 OpEngStartConsentSummary 3 "Not available" 2 "Error" 1 "Consent" 0 "No consent" ;
VAL_ 2431710718 ReqLatchStatus 15 "Not available" 6 "Start request unlatched, start could not be completed because the starter command was not successful" 5 "Start request unlatched, start aborted due to abort request" 4 "Start request unlatched, consent not established within allowed time" 3 "Start request unlatched, start completed" 2 "Start request latched, consent confirmed" 1 "Start request latched, waiting for consent" 0 "Start request not received" ;
VAL_ 2431710718 StarterCmd 7 "Don’t care / Take no action" 3 "Command withdrawn" 2 "Command active for starter 2" 1 "Command active for starter 1" 0 "Command not active" ;
VAL_ 2431710718 CtrlMessageRate 3 "Not available" 2 "Reserved" 1 "Once every 250 ms or on change but no faster than 20 ms" 0 "Once every 20 ms" ;
VAL_ 2431708670 Starter2Feedback 7 "Not available" 4 "Starter command unlatched,  start aborted by starter controller" 3 "Starter command unlatched,  start abort command received from arbitrator" 2 "Starter command unlatched,  start completed" 1 "Starter command latched" 0 "Starter not commanded" ;
VAL_ 2431708670 Starter1Feedback 7 "Not available" 4 "Starter command unlatched,  start aborted by starter controller" 3 "Starter command unlatched,  start abort command received from arbitrator" 2 "Starter command unlatched,  start completed" 1 "Starter command latched" 0 "Starter not commanded" ;
VAL_ 2431708670 AbortReq 3 "Don’t care / Take no action" 2 "Reserved" 1 "Abort requested" 0 "Abort not requested" ;
VAL_ 2431708670 Consent 7 "Not available" 3 "Consent to both" 2 "Consent to automatic start only" 1 "Consent to operator-requested start only" 0 "No consent" ;
VAL_ 2431708670 Req 3 "Not available" 2 "Start requested,  automatic type" 1 "Start requested,  operator type" 0 "Start not requested" ;
VAL_ 2565926142 NOxSnsr2SelfDiagStatus 0 "Diagnosis not active" 7 "Not Supported" 4 "NOx Sensor ATO2 Self Diagnosis not possible" 3 "NOx Sensor ATO2 Self Diagnosis aborted" 2 "NOx Sensor ATO2 Self Diagnosis Result Complete" 1 "NOx Sensor ATO2 Self Diagnosis active flag" ;
VAL_ 2565926142 GasSnsr2HtrCtrl 3 "Heater off" 2 "Preheat 1" 1 "Preheat 2" 0 "Automatic" ;
VAL_ 2565926142 WRPercentO22ReadingStable 3 "Not available" 2 "Error" 1 "Stable" 0 "Not stable" ;
VAL_ 2565926142 NOx2ReadingStable 3 "Not available" 2 "Error" 1 "Stable" 0 "Not stable" ;
VAL_ 2565926142 GasSnsr2AtTemp 3 "Not available" 2 "Error" 1 "In range" 0 "Not in range" ;
VAL_ 2565926142 GasSnsr2PwrInRange 3 "Not available" 2 "Error" 1 "In range" 0 "Not in range" ;
VAL_ 2565925886 NOxSnsr2SelfDiagStatus 7 "Not Supported" 4 "NOx Sensor ATI2 Self Diagnosis not possible" 3 "NOx Sensor ATI2 Self Diagnosis aborted" 2 "NOx Sensor ATI2 Self Diagnosis Result Complete" 1 "NOx Sensor ATI2 Self Diagnosis active flag" 0 "Diagnosis not active" ;
VAL_ 2565925886 GasSnsr2HtrCtrl 3 "Heater off" 2 "Preheat 1" 1 "Preheat 2" 0 "Automatic" ;
VAL_ 2565925886 WRPercentO22ReadingStable 3 "Not available" 2 "Error" 1 "Stable" 0 "Not stable" ;
VAL_ 2565925886 SCRInNOx2ReadingStable 3 "Not available" 2 "Error" 1 "Stable" 0 "Not stable" ;
VAL_ 2565925886 GasSnsr2AtTemp 3 "Not available" 2 "Error" 1 "In range" 0 "Not in range" ;
VAL_ 2565925886 GasSnsr2PwrInRange 3 "Not available" 2 "Error" 1 "In range" 0 "Not in range" ;
VAL_ 2565925630 NOxSnsr2SelfDiagStatus 7 "Not Supported" 4 "NOx Sensor ATO1 Self Diagnosis not possible" 3 "NOx Sensor ATO1 Self Diagnosis aborted" 2 "NOx Sensor ATO1 Self Diagnosis Result Complete" 1 "NOx Sensor ATO1 Self Diagnosis active flag" 0 "Diagnosis not active" ;
VAL_ 2565925630 Snsr2HtrCtrl 3 "Heater off" 2 "Preheat 1" 1 "Preheat 2" 0 "Automatic" ;
VAL_ 2565925630 WRPercentO22ReadingStable 3 "Not available" 2 "Error" 1 "Stable" 0 "Not stable" ;
VAL_ 2565925630 NOx2ReadingStable 3 "Not available" 2 "Error" 1 "Stable" 0 "Not stable" ;
VAL_ 2565925630 Snsr2AtTemp 3 "Not available" 2 "Error" 1 "In range" 0 "Not in range" ;
VAL_ 2565925630 Snsr2PwrInRange 3 "Not available" 2 "Error" 1 "In range" 0 "Not in range" ;
VAL_ 2565925374 NOxSnsr2SelfDiagStatus 7 "Not Supported" 4 "NOx Sensor ATI1 Self Diagnosis not possible" 3 "NOx Sensor ATI1 Self Diagnosis aborted" 2 "NOx Sensor ATI1 Self Diagnosis Result Complete" 1 "NOx Sensor ATI1 Self Diagnosis active flag" 0 "Diagnosis not active" ;
VAL_ 2565925374 Snsr2HtrCtrl 3 "Heater off" 2 "Preheat 1" 1 "Preheat 2" 0 "Automatic" ;
VAL_ 2565925374 WRPercentO22ReadingStable 3 "Not available" 2 "Error" 1 "Stable" 0 "Not stable" ;
VAL_ 2565925374 SCRInNOx2ReadingStable 3 "Not available" 2 "Error" 1 "Stable" 0 "Not stable" ;
VAL_ 2565925374 Snsr2AtTemp 3 "Not available" 2 "Error" 1 "In range" 0 "Not in range" ;
VAL_ 2565925374 Snsr2PwrInRange 3 "Not available" 2 "Error" 1 "In range" 0 "Not in range" ;
VAL_ 2566838014 ShutdownSw 3 "Not Available" 2 "Error" 1 "On" 0 "Off" ;
VAL_ 2566838014 PropulsionDisableSw 3 "Not Available" 2 "Error" 1 "On" 0 "Off" ;
VAL_ 2566838014 HybrdSystmBrkPdlRgnrtvBrkngDsblS 3 "Not Available" 2 "Error" 1 "Brake pedal regenerative braking disable switch is on" 0 "Brake pedal regenerative braking disable switch is off" ;
VAL_ 2566838014 HybrdSystmRgnrtvBrkngDsbleSwitch 3 "Not Available" 2 "Error" 1 "Regenerative Braking  Disable Switch is on" 0 "Regenerative Braking Disable Switch is off" ;
VAL_ 2566838014 HybrdSystmOffBrdChrgrCnnctnSttus 3 "Not available" 2 "Error" 1 "Off-board charger is connected" 0 "Off-board charger is not connected" ;
VAL_ 2566838014 HybrdSystmPwrElctrncsClntLvlSwtc 3 "Not Available" 2 "Error" 1 "Coolant Level is sufficient" 0 "Coolant Level is not sufficient" ;
VAL_ 2566838014 HybrdSystmPrplsnClantLevelSwitch 3 "Not Available" 2 "Error" 1 "Coolant Level is sufficient" 0 "Coolant Level is not sufficient" ;
VAL_ 2566838014 HybrdSystmPrtctionOverrideSwitch 3 "Not Available" 2 "Error" 1 "Active" 0 "Not Active" ;
VAL_ 2566687998 RegenSt 15 "Not Available" 3 "Regeneration is active and has been initiated due to time based conditions" 2 "Regeneration is active and has been initiated because of sensor conditions" 1 "Regneration is active and has been initiated by request via SPN 6783" 0 "Regeneration is not active" ;
VAL_ 2566687998 RegenStatus 3 "not available" 2 "Regeneration failed" 1 "Regeneration was successful" 0 "Regeneration attempt has not occurred during this operational cycle" ;
VAL_ 2566687998 HtrSt 3 "Heater is off" 2 "Heater is in ramp up mode" 1 "Heater is being held at a specified level" 0 "Heater is in closed loop control" ;
VAL_ 2566687742 PwrSupply 3 "Unavailable" 2 "Error" 1 "On" 0 "Off" ;
VAL_ 2566687742 DetectionStatus 15 "Not supported" 8 "Halt particulate matter detection" 7 "Sensor regeneration did not complete due to system parameters out of range" 6 "Relearning particulate sensor resistance after particulate sensor regeneration" 5 "Heater diagnostics test" 4 "Cooling after particulate sensor regeneration" 3 "Heater is active for particulate sensor regeneration" 2 "Particulate matter detection" 1 "Waiting for dew point" 0 "Initialization for particulate matter detection" ;
VAL_ 2365348350 EngLoadShareStatus 15 "Unavailable" 14 "Error" 4 "Unloading" 3 "Loading" 2 "Slave" 1 "Master" 0 "Offline" ;
VAL_ 2365348350 EngUnloadStatus 3 "Not Available" 2 "Error" 1 "Requested" 0 "Not Requested" ;
VAL_ 2633782014 BinWeighingErrorStatus 15 "Not available / not applicable" 3 "Weighing error: empty bin lifted" 2 "Weighing error: bin lifted" 1 "Bad lift cycle" 0 "No error" ;
VAL_ 2365346302 LiftAxle2Status 7 "Not available" 6 "Error" 5 "Loading" 4 "Lowering" 3 "Up" 2 "Lifting" 1 "Unloading" 0 "Down" ;
VAL_ 2365346302 LiftAxle1Status 7 "Not available" 6 "Error" 5 "Loading" 4 "Lowering" 3 "Up" 2 "Lifting" 1 "Unloading" 0 "Down" ;
VAL_ 2566672638 DeliveryTransactionStatus 15 "Not Available" 14 "Error" 2 "Transaction Complete" 1 "Transaction In Progress" 0 "Transaction Not In Progress" ;
VAL_ 2566672638 HaulModeStatus 15 "Not Available" 14 "Error" 5 "Unloaded" 4 "Unloading" 3 "Loaded" 2 "Approaching Loaded" 1 "Loading" 0 "Not in Haul Mode" ;
VAL_ 2566672382 PayloadWeightSensor8Status 3 "Not available" 2 "Error" 1 "Sensor degraded" 0 "Sensor fully functional" ;
VAL_ 2566672382 PayloadWeightSensor7Status 3 "Not available" 2 "Error" 1 "Sensor degraded" 0 "Sensor fully functional" ;
VAL_ 2566672382 PayloadWeightSensor6Status 3 "Not available" 2 "Error" 1 "Sensor degraded" 0 "Sensor fully functional" ;
VAL_ 2566672382 PayloadWeightSensor5Status 3 "Not available" 2 "Error" 1 "Sensor degraded" 0 "Sensor fully functional" ;
VAL_ 2566672382 PayloadWeightSensor4Status 3 "Not available" 2 "Error" 1 "Sensor degraded" 0 "Sensor fully functional" ;
VAL_ 2566672382 PayloadWeightSensor3Status 3 "Not available" 2 "Error" 1 "Sensor degraded" 0 "Sensor fully functional" ;
VAL_ 2566672382 PayloadWeightSensor2Status 3 "Not available" 2 "Error" 1 "Sensor degraded" 0 "Sensor fully functional" ;
VAL_ 2566672382 PayloadWeightSensor1Status 2 "Error" 1 "Sensor degraded" 0 "Sensor fully functional" 3 "Not available" ;
VAL_ 2566671614 SCROprtrInducementOverrideEnable 3 "Not available" 2 "SAE Reserved" 1 "Override allowed" 0 "Override not allowed" ;
